[part 1 of 3: package /STLASWCs]
AUTOSAR XML (schema 4-3-0)
package /STLASWCs
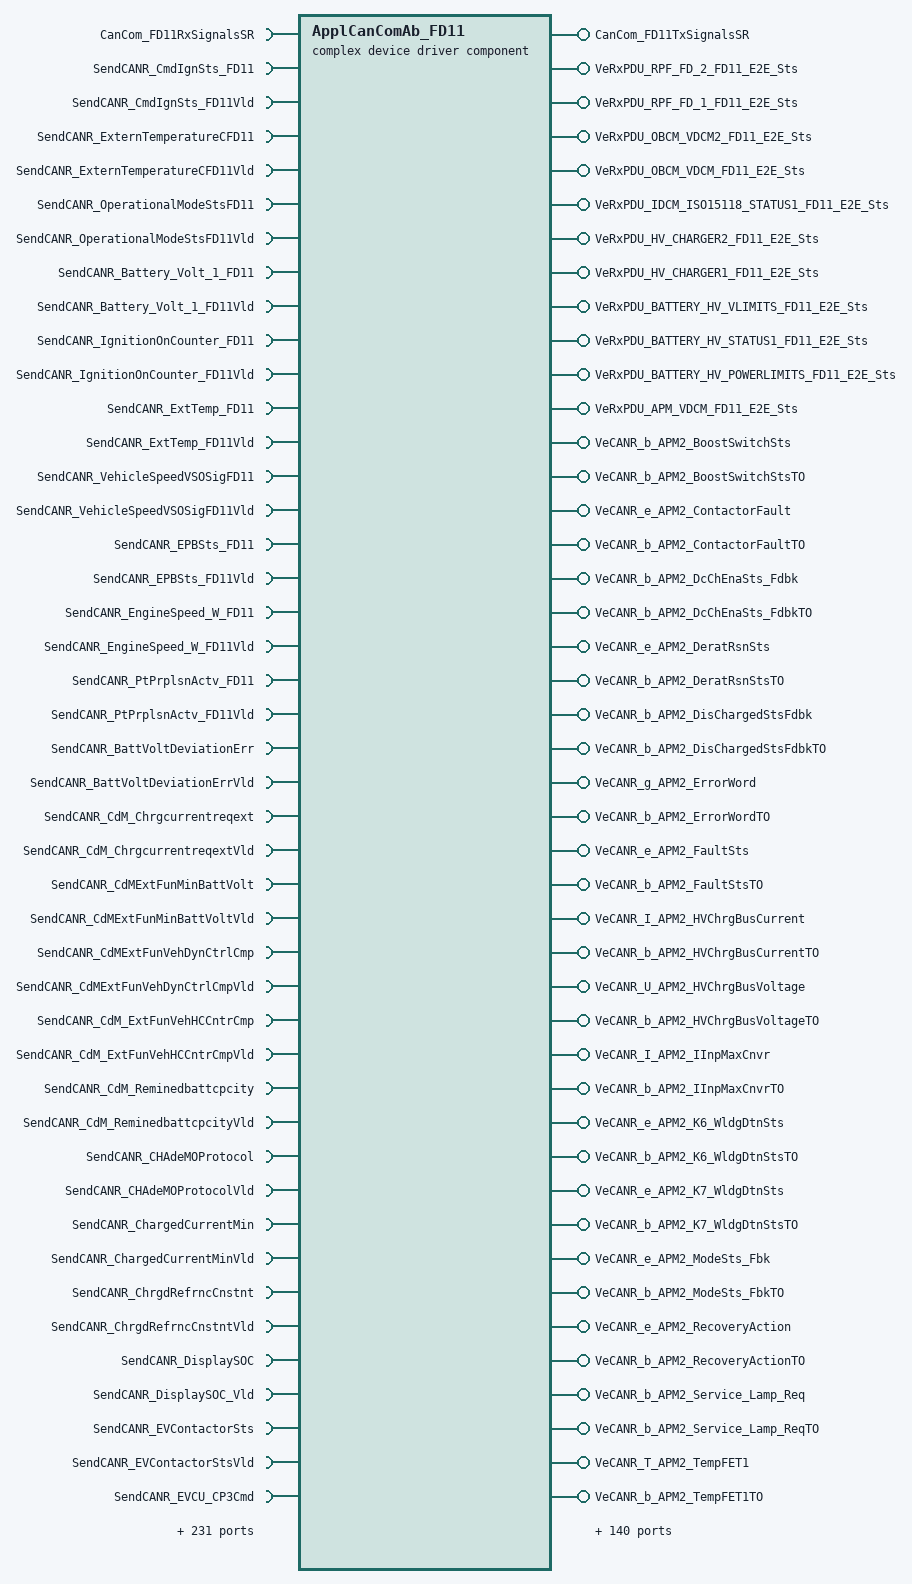
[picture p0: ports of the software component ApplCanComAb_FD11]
  complex device driver sw component type ApplCanComAb_FD11  # Application CAN Communication Abstraction Component - is responsible with receiving and sending CAN data from/to the lower BSW COM layers
    12 x provide port:
      CanCom_FD11TxSignalsSR: provided-interface=CanCom_FD11TxSignalsSR
        provided-com-specs:
          data-element=COMTX_CmdIgnSts_BCM_FD_10_FD11, init-value=constant-reference=COMTX_CmdIgnSts_BCM_FD_10_FD11_Init
          data-element=COMTX_ExternalTemperatureC_BCM_FD_10_FD11, init-value=constant-reference=COMTX_ExternalTemperatureC_BCM_FD_10_FD11_Init
          data-element=COMTX_OperationalModeSts_BCM_FD_2_FD11, init-value=constant-reference=COMTX_OperationalModeSts_BCM_FD_2_FD11_Init
          data-element=COMTX_Battery_Volt_1_BCM_FD_3_FD11, init-value=constant-reference=COMTX_Battery_Volt_1_BCM_FD_3_FD11_Init
          data-element=COMTX_IgnitionOnCounter_BCM_FD_7_FD11, init-value=constant-reference=COMTX_IgnitionOnCounter_BCM_FD_7_FD11_Init
          data-element=COMTX_ExternalTemperature_BCM_FD_9_FD11, init-value=constant-reference=COMTX_ExternalTemperature_BCM_FD_9_FD11_Init
          data-element=COMTX_VehicleSpeedVSOSig_BRAKE_FD_2_FD11, init-value=constant-reference=COMTX_VehicleSpeedVSOSig_BRAKE_FD_2_FD11_Init
          data-element=COMTX_EPBSts_BRAKE_FD_4_FD11, init-value=constant-reference=COMTX_EPBSts_BRAKE_FD_4_FD11_Init
          data-element=COMTX_EngineSpeed_W_ENGINE_FD_2_FD11, init-value=constant-reference=COMTX_EngineSpeed_W_ENGINE_FD_2_FD11_Init
          data-element=COMTX_PowertrainPrplsnActv_ENGINE_FD_2_FD11, init-value=constant-reference=COMTX_PowertrainPrplsnActv_ENGINE_FD_2_FD11_Init
          data-element=COMTX_BattVoltDeviationErr_EVCU_CHADEMO_STATUS1_FD11, init-value=constant-reference=COMTX_BattVoltDeviationErr_EVCU_CHADEMO_STATUS1_FD11_Init
          data-element=COMTX_CdM_Chrg_current_req_ext_EVCU_CHADEMO_STATUS1_FD11, init-value=constant-reference=COMTX_CdM_Chrg_current_req_ext_EVCU_CHADEMO_STATUS1_FD11_Init
          data-element=COMTX_CdM_ExtFun_Min_Batt_Volt_EVCU_CHADEMO_STATUS1_FD11, init-value=constant-reference=COMTX_CdM_ExtFun_Min_Batt_Volt_EVCU_CHADEMO_STATUS1_FD11_Init
          data-element=COMTX_CdM_ExtFun_Veh_Dyn_Control_Comp_EVCU_CHADEMO_STATUS1_FD11, init-value=constant-reference=COMTX_CdM_ExtFun_Veh_Dyn_Control_Comp_EVCU_CHADEMO_STATUS1_FD11_Init
          data-element=COMTX_CdM_ExtFun_Veh_HC_Control_Comp_EVCU_CHADEMO_STATUS1_FD11, init-value=constant-reference=COMTX_CdM_ExtFun_Veh_HC_Control_Comp_EVCU_CHADEMO_STATUS1_FD11_Init
          data-element=COMTX_CdM_Remained_batt_capacity_EVCU_CHADEMO_STATUS1_FD11, init-value=constant-reference=COMTX_CdM_Remained_batt_capacity_EVCU_CHADEMO_STATUS1_FD11_Init
          data-element=COMTX_CHAdeMOProtocol_EVCU_CHADEMO_STATUS1_FD11, init-value=constant-reference=COMTX_CHAdeMOProtocol_EVCU_CHADEMO_STATUS1_FD11_Init
          data-element=COMTX_ChargedCurrentMin_EVCU_CHADEMO_STATUS1_FD11, init-value=constant-reference=COMTX_ChargedCurrentMin_EVCU_CHADEMO_STATUS1_FD11_Init
          data-element=COMTX_ChargedReferenceConstant_EVCU_CHADEMO_STATUS1_FD11, init-value=constant-reference=COMTX_ChargedReferenceConstant_EVCU_CHADEMO_STATUS1_FD11_Init
          data-element=COMTX_DisplaySOC_EVCU_CHADEMO_STATUS1_FD11, init-value=constant-reference=COMTX_DisplaySOC_EVCU_CHADEMO_STATUS1_FD11_Init
          data-element=COMTX_EVContactorSts_EVCU_CHADEMO_STATUS1_FD11, init-value=constant-reference=COMTX_EVContactorSts_EVCU_CHADEMO_STATUS1_FD11_Init
          data-element=COMTX_EVCU_CP3Cmd_EVCU_CHADEMO_STATUS1_FD11, init-value=constant-reference=COMTX_EVCU_CP3Cmd_EVCU_CHADEMO_STATUS1_FD11_Init
          data-element=COMTX_MinBatteryPackVoltage_EVCU_CHADEMO_STATUS1_FD11, init-value=constant-reference=COMTX_MinBatteryPackVoltage_EVCU_CHADEMO_STATUS1_FD11_Init
          data-element=COMTX_StopReqBeforeCharge_EVCU_CHADEMO_STATUS1_FD11, init-value=constant-reference=COMTX_StopReqBeforeCharge_EVCU_CHADEMO_STATUS1_FD11_Init
          data-element=COMTX_TotalBatteryCapacity_EVCU_CHADEMO_STATUS1_FD11, init-value=constant-reference=COMTX_TotalBatteryCapacity_EVCU_CHADEMO_STATUS1_FD11_Init
          data-element=COMTX_VehicleDriveSts_EVCU_CHADEMO_STATUS1_FD11, init-value=constant-reference=COMTX_VehicleDriveSts_EVCU_CHADEMO_STATUS1_FD11_Init
          data-element=COMTX_N_PDU_7B_GLIWA_MCPA_TX_FD11, init-value=constant-reference=COMTX_N_PDU_7B_GLIWA_MCPA_TX_FD11_Init
          data-element=COMTX_N_PDU_7C_GLIWA_MCPB_TX_FD11, init-value=constant-reference=COMTX_N_PDU_7C_GLIWA_MCPB_TX_FD11_Init
          data-element=COMTX_N_PDU_86_GLIWA_SGCP_TX_FD11, init-value=constant-reference=COMTX_N_PDU_86_GLIWA_SGCP_TX_FD11_Init
          data-element=COMTX_N_PDU_342_GLIWA_T1_TX_FD11, init-value=constant-reference=COMTX_N_PDU_342_GLIWA_T1_TX_FD11_Init
          data-element=COMTX_CRC_HYBRID_DISPLAY2_HYBRID_DISPLAY2_FD11, init-value=constant-reference=COMTX_CRC_HYBRID_DISPLAY2_HYBRID_DISPLAY2_FD11_Init
          data-element=COMTX_DischargingSysStatus_HYBRID_DISPLAY2_FD11, init-value=constant-reference=COMTX_DischargingSysStatus_HYBRID_DISPLAY2_FD11_Init
          data-element=COMTX_LID_Status_120V_Socket_A_HYBRID_DISPLAY2_FD11, init-value=constant-reference=COMTX_LID_Status_120V_Socket_A_HYBRID_DISPLAY2_FD11_Init
          data-element=COMTX_LID_Status_120V_Socket_B_HYBRID_DISPLAY2_FD11, init-value=constant-reference=COMTX_LID_Status_120V_Socket_B_HYBRID_DISPLAY2_FD11_Init
          data-element=COMTX_LID_Status_240V_Socket_HYBRID_DISPLAY2_FD11, init-value=constant-reference=COMTX_LID_Status_240V_Socket_HYBRID_DISPLAY2_FD11_Init
          data-element=COMTX_Max_Allwd_AC_Output_Current_L1_HYBRID_DISPLAY2_FD11, init-value=constant-reference=COMTX_Max_Allwd_AC_Output_Current_L1_HYBRID_DISPLAY2_FD11_Init
          data-element=COMTX_Max_Allwd_AC_Output_Voltage_L1_HYBRID_DISPLAY2_FD11, init-value=constant-reference=COMTX_Max_Allwd_AC_Output_Voltage_L1_HYBRID_DISPLAY2_FD11_Init
          data-element=COMTX_MC_HYBRID_DISPLAY2_HYBRID_DISPLAY2_FD11, init-value=constant-reference=COMTX_MC_HYBRID_DISPLAY2_HYBRID_DISPLAY2_FD11_Init
          data-element=COMTX_CRC_HYBRID_SYSTEM_EPT1_HYBRID_SYSTEM_EPT1_FD11, init-value=constant-reference=COMTX_CRC_HYBRID_SYSTEM_EPT1_HYBRID_SYSTEM_EPT1_FD11_Init
          data-element=COMTX_HCP_ShutdownCommand_HYBRID_SYSTEM_EPT1_FD11, init-value=constant-reference=COMTX_HCP_ShutdownCommand_HYBRID_SYSTEM_EPT1_FD11_Init
          data-element=COMTX_HybridDriveModeSts_HYBRID_SYSTEM_EPT1_FD11, init-value=constant-reference=COMTX_HybridDriveModeSts_HYBRID_SYSTEM_EPT1_FD11_Init
          data-element=COMTX_LOC_DiagEnable_ePT_HYBRID_SYSTEM_EPT1_FD11, init-value=constant-reference=COMTX_LOC_DiagEnable_ePT_HYBRID_SYSTEM_EPT1_FD11_Init
          data-element=COMTX_MessageCounter_HYBRID_SYSTEM_EPT1_HYBRID_SYSTEM_EPT1_FD11, init-value=constant-reference=COMTX_MessageCounter_HYBRID_SYSTEM_EPT1_HYBRID_SYSTEM_EPT1_FD11_Init
          data-element=COMTX_PerWakeUp_Diag_HYBRID_SYSTEM_EPT1_FD11, init-value=constant-reference=COMTX_PerWakeUp_Diag_HYBRID_SYSTEM_EPT1_FD11_Init
          data-element=COMTX_PropulsionSystemActive_10B_HYBRID_SYSTEM_EPT1_FD11, init-value=constant-reference=COMTX_PropulsionSystemActive_10B_HYBRID_SYSTEM_EPT1_FD11_Init
          data-element=COMTX_WU_Timer_Value_HYBRID_SYSTEM_EPT1_FD11, init-value=constant-reference=COMTX_WU_Timer_Value_HYBRID_SYSTEM_EPT1_FD11_Init
          data-element=COMTX_IMPACTCommand_IMPACT_INFO_FD11, init-value=constant-reference=COMTX_IMPACTCommand_IMPACT_INFO_FD11_Init
          data-element=COMTX_IMPACTConfirm_IMPACT_INFO_FD11, init-value=constant-reference=COMTX_IMPACTConfirm_IMPACT_INFO_FD11_Init
          data-element=COMTX_TotalOdometer_IPC_FD_1_FD11, init-value=constant-reference=COMTX_TotalOdometer_IPC_FD_1_FD11_Init
          data-element=COMTX_MCPA_Temp_MCPA_DATA2_FD11, init-value=constant-reference=COMTX_MCPA_Temp_MCPA_DATA2_FD11_Init
          data-element=COMTX_CRC_MCPA_STATUS_MCPA_STATUS_FD11, init-value=constant-reference=COMTX_CRC_MCPA_STATUS_MCPA_STATUS_FD11_Init
          data-element=COMTX_MC_MCPA_STATUS_MCPA_STATUS_FD11, init-value=constant-reference=COMTX_MC_MCPA_STATUS_MCPA_STATUS_FD11_Init
          data-element=COMTX_MCPA_DC_Current_P_MCPA_STATUS_FD11, init-value=constant-reference=COMTX_MCPA_DC_Current_P_MCPA_STATUS_FD11_Init
          data-element=COMTX_MCPB_Temp_MCPB_DATA2_FD11, init-value=constant-reference=COMTX_MCPB_Temp_MCPB_DATA2_FD11_Init
          data-element=COMTX_CRC_MCPB_STATUS_MCPB_STATUS_FD11, init-value=constant-reference=COMTX_CRC_MCPB_STATUS_MCPB_STATUS_FD11_Init
          data-element=COMTX_MC_MCPB_STATUS_MCPB_STATUS_FD11, init-value=constant-reference=COMTX_MC_MCPB_STATUS_MCPB_STATUS_FD11_Init
          data-element=COMTX_MCPB_DC_Current_P_MCPB_STATUS_FD11, init-value=constant-reference=COMTX_MCPB_DC_Current_P_MCPB_STATUS_FD11_Init
          data-element=COMTX_CurrentCanNMState_FD03_EVCU2_PDC_INFO_FD_EVCU2_FD11, init-value=constant-reference=COMTX_CurrentCanNMState_FD03_EVCU2_PDC_INFO_FD_EVCU2_FD11_Init
          data-element=COMTX_CurrentCanNMState_FD05_EVCU2_PDC_INFO_FD_EVCU2_FD11, init-value=constant-reference=COMTX_CurrentCanNMState_FD05_EVCU2_PDC_INFO_FD_EVCU2_FD11_Init
          data-element=COMTX_CurrentCanNMState_FD11_EVCU2_PDC_INFO_FD_EVCU2_FD11, init-value=constant-reference=COMTX_CurrentCanNMState_FD11_EVCU2_PDC_INFO_FD_EVCU2_FD11_Init
          data-element=COMTX_CurrentCanNMState_FD16_EVCU2_PDC_INFO_FD_EVCU2_FD11, init-value=constant-reference=COMTX_CurrentCanNMState_FD16_EVCU2_PDC_INFO_FD_EVCU2_FD11_Init
          data-element=COMTX_CurrentFailSts_FD03_EVCU2_PDC_INFO_FD_EVCU2_FD11, init-value=constant-reference=COMTX_CurrentFailSts_FD03_EVCU2_PDC_INFO_FD_EVCU2_FD11_Init
          data-element=COMTX_CurrentFailSts_FD05_EVCU2_PDC_INFO_FD_EVCU2_FD11, init-value=constant-reference=COMTX_CurrentFailSts_FD05_EVCU2_PDC_INFO_FD_EVCU2_FD11_Init
          data-element=COMTX_CurrentFailSts_FD11_EVCU2_PDC_INFO_FD_EVCU2_FD11, init-value=constant-reference=COMTX_CurrentFailSts_FD11_EVCU2_PDC_INFO_FD_EVCU2_FD11_Init
          data-element=COMTX_CurrentFailSts_FD16_EVCU2_PDC_INFO_FD_EVCU2_FD11, init-value=constant-reference=COMTX_CurrentFailSts_FD16_EVCU2_PDC_INFO_FD_EVCU2_FD11_Init
          data-element=COMTX_DES_FD03_EVCU2_PDC_INFO_FD_EVCU2_FD11, init-value=constant-reference=COMTX_DES_FD03_EVCU2_PDC_INFO_FD_EVCU2_FD11_Init
          data-element=COMTX_DES_FD05_EVCU2_PDC_INFO_FD_EVCU2_FD11, init-value=constant-reference=COMTX_DES_FD05_EVCU2_PDC_INFO_FD_EVCU2_FD11_Init
          data-element=COMTX_DES_FD11_EVCU2_PDC_INFO_FD_EVCU2_FD11, init-value=constant-reference=COMTX_DES_FD11_EVCU2_PDC_INFO_FD_EVCU2_FD11_Init
          data-element=COMTX_DES_FD16_EVCU2_PDC_INFO_FD_EVCU2_FD11, init-value=constant-reference=COMTX_DES_FD16_EVCU2_PDC_INFO_FD_EVCU2_FD11_Init
          data-element=COMTX_EOL_FD03_EVCU2_PDC_INFO_FD_EVCU2_FD11, init-value=constant-reference=COMTX_EOL_FD03_EVCU2_PDC_INFO_FD_EVCU2_FD11_Init
          data-element=COMTX_EOL_FD05_EVCU2_PDC_INFO_FD_EVCU2_FD11, init-value=constant-reference=COMTX_EOL_FD05_EVCU2_PDC_INFO_FD_EVCU2_FD11_Init
          data-element=COMTX_EOL_FD11_EVCU2_PDC_INFO_FD_EVCU2_FD11, init-value=constant-reference=COMTX_EOL_FD11_EVCU2_PDC_INFO_FD_EVCU2_FD11_Init
          data-element=COMTX_EOL_FD16_EVCU2_PDC_INFO_FD_EVCU2_FD11, init-value=constant-reference=COMTX_EOL_FD16_EVCU2_PDC_INFO_FD_EVCU2_FD11_Init
          data-element=COMTX_GenericFailSts_FD03_EVCU2_PDC_INFO_FD_EVCU2_FD11, init-value=constant-reference=COMTX_GenericFailSts_FD03_EVCU2_PDC_INFO_FD_EVCU2_FD11_Init
          data-element=COMTX_GenericFailSts_FD05_EVCU2_PDC_INFO_FD_EVCU2_FD11, init-value=constant-reference=COMTX_GenericFailSts_FD05_EVCU2_PDC_INFO_FD_EVCU2_FD11_Init
          data-element=COMTX_GenericFailSts_FD11_EVCU2_PDC_INFO_FD_EVCU2_FD11, init-value=constant-reference=COMTX_GenericFailSts_FD11_EVCU2_PDC_INFO_FD_EVCU2_FD11_Init
          data-element=COMTX_GenericFailSts_FD16_EVCU2_PDC_INFO_FD_EVCU2_FD11, init-value=constant-reference=COMTX_GenericFailSts_FD16_EVCU2_PDC_INFO_FD_EVCU2_FD11_Init
          data-element=COMTX_PreviousCanNMState_FD03_EVCU2_PDC_INFO_FD_EVCU2_FD11, init-value=constant-reference=COMTX_PreviousCanNMState_FD03_EVCU2_PDC_INFO_FD_EVCU2_FD11_Init
          data-element=COMTX_PreviousCanNMState_FD05_EVCU2_PDC_INFO_FD_EVCU2_FD11, init-value=constant-reference=COMTX_PreviousCanNMState_FD05_EVCU2_PDC_INFO_FD_EVCU2_FD11_Init
          data-element=COMTX_PreviousCanNMState_FD11_EVCU2_PDC_INFO_FD_EVCU2_FD11, init-value=constant-reference=COMTX_PreviousCanNMState_FD11_EVCU2_PDC_INFO_FD_EVCU2_FD11_Init
          data-element=COMTX_PreviousCanNMState_FD16_EVCU2_PDC_INFO_FD_EVCU2_FD11, init-value=constant-reference=COMTX_PreviousCanNMState_FD16_EVCU2_PDC_INFO_FD_EVCU2_FD11_Init
          data-element=COMTX_StayActiveSource_FD03_EVCU2_PDC_INFO_FD_EVCU2_FD11, init-value=constant-reference=COMTX_StayActiveSource_FD03_EVCU2_PDC_INFO_FD_EVCU2_FD11_Init
          data-element=COMTX_StayActiveSource_FD05_EVCU2_PDC_INFO_FD_EVCU2_FD11, init-value=constant-reference=COMTX_StayActiveSource_FD05_EVCU2_PDC_INFO_FD_EVCU2_FD11_Init
          data-element=COMTX_StayActiveSource_FD11_EVCU2_PDC_INFO_FD_EVCU2_FD11, init-value=constant-reference=COMTX_StayActiveSource_FD11_EVCU2_PDC_INFO_FD_EVCU2_FD11_Init
          data-element=COMTX_StayActiveSource_FD16_EVCU2_PDC_INFO_FD_EVCU2_FD11, init-value=constant-reference=COMTX_StayActiveSource_FD16_EVCU2_PDC_INFO_FD_EVCU2_FD11_Init
          data-element=COMTX_WakeupSource_FD03_EVCU2_PDC_INFO_FD_EVCU2_FD11, init-value=constant-reference=COMTX_WakeupSource_FD03_EVCU2_PDC_INFO_FD_EVCU2_FD11_Init
          data-element=COMTX_WakeupSource_FD05_EVCU2_PDC_INFO_FD_EVCU2_FD11, init-value=constant-reference=COMTX_WakeupSource_FD05_EVCU2_PDC_INFO_FD_EVCU2_FD11_Init
          data-element=COMTX_WakeupSource_FD11_EVCU2_PDC_INFO_FD_EVCU2_FD11, init-value=constant-reference=COMTX_WakeupSource_FD11_EVCU2_PDC_INFO_FD_EVCU2_FD11_Init
          data-element=COMTX_WakeupSource_FD16_EVCU2_PDC_INFO_FD_EVCU2_FD11, init-value=constant-reference=COMTX_WakeupSource_FD16_EVCU2_PDC_INFO_FD_EVCU2_FD11_Init
          data-element=COMTX_DriveReady_PT_PT_SYSTEM_FD_1_FD11, init-value=constant-reference=COMTX_DriveReady_PT_PT_SYSTEM_FD_1_FD11_Init
          data-element=COMTX_GearEngaged_PT_PT_SYSTEM_FD_1_FD11, init-value=constant-reference=COMTX_GearEngaged_PT_PT_SYSTEM_FD_1_FD11_Init
          data-element=COMTX_GearEngagedForDisplay_PT_PT_SYSTEM_FD_1_FD11, init-value=constant-reference=COMTX_GearEngagedForDisplay_PT_PT_SYSTEM_FD_1_FD11_Init
          data-element=COMTX_PowertrainPrplsnActv_PT_PT_SYSTEM_FD_1_FD11, init-value=constant-reference=COMTX_PowertrainPrplsnActv_PT_PT_SYSTEM_FD_1_FD11_Init
          data-element=COMTX_SGCP_Temp_SGCP_DATA2_FD11, init-value=constant-reference=COMTX_SGCP_Temp_SGCP_DATA2_FD11_Init
          data-element=COMTX_SGCP_DC_Current_P_SGCP_STATUS_FD11, init-value=constant-reference=COMTX_SGCP_DC_Current_P_SGCP_STATUS_FD11_Init
          data-element=COMTX_QualifyDriveCycle_SYNCHRO_DC_GLOBAL_FD11, init-value=constant-reference=COMTX_QualifyDriveCycle_SYNCHRO_DC_GLOBAL_FD11_Init
          data-element=COMTX_GPS_Date_Day_TELEMATIC_FD_1_FD11, init-value=constant-reference=COMTX_GPS_Date_Day_TELEMATIC_FD_1_FD11_Init
          data-element=COMTX_GPS_Date_Month_TELEMATIC_FD_1_FD11, init-value=constant-reference=COMTX_GPS_Date_Month_TELEMATIC_FD_1_FD11_Init
          data-element=COMTX_GPS_Date_Year_TELEMATIC_FD_1_FD11, init-value=constant-reference=COMTX_GPS_Date_Year_TELEMATIC_FD_1_FD11_Init
          data-element=COMTX_GPS_UTC_Hour_TELEMATIC_FD_1_FD11, init-value=constant-reference=COMTX_GPS_UTC_Hour_TELEMATIC_FD_1_FD11_Init
          data-element=COMTX_GPS_UTC_Minute_TELEMATIC_FD_1_FD11, init-value=constant-reference=COMTX_GPS_UTC_Minute_TELEMATIC_FD_1_FD11_Init
          data-element=COMTX_GPS_UTC_Second_TELEMATIC_FD_1_FD11, init-value=constant-reference=COMTX_GPS_UTC_Second_TELEMATIC_FD_1_FD11_Init
          data-element=COMTX_GearEngagedForDisplay_TRANSM_FD_2_FD11, init-value=constant-reference=COMTX_GearEngagedForDisplay_TRANSM_FD_2_FD11_Init
          data-element=COMTX_HVCMS_BulkChargingComplete_VDCM_OBCM_FD11, init-value=constant-reference=COMTX_HVCMS_BulkChargingComplete_VDCM_OBCM_FD11_Init
          data-element=COMTX_HVCMS_ChargingComplete_VDCM_OBCM_FD11, init-value=constant-reference=COMTX_HVCMS_ChargingComplete_VDCM_OBCM_FD11_Init
          data-element=COMTX_HVCMS_EVEnergyCapacity_VDCM_OBCM_FD11, init-value=constant-reference=COMTX_HVCMS_EVEnergyCapacity_VDCM_OBCM_FD11_Init
          data-element=COMTX_HVCMS_EVEnergyRequest_VDCM_OBCM_FD11, init-value=constant-reference=COMTX_HVCMS_EVEnergyRequest_VDCM_OBCM_FD11_Init
          data-element=COMTX_HVCMS_EVErrorCode_VDCM_OBCM_FD11, init-value=constant-reference=COMTX_HVCMS_EVErrorCode_VDCM_OBCM_FD11_Init
          data-element=COMTX_HVCMS_EVMax_I_Limit_VDCM_OBCM_FD11, init-value=constant-reference=COMTX_HVCMS_EVMax_I_Limit_VDCM_OBCM_FD11_Init
          data-element=COMTX_HVCMS_EVMax_P_Limit_VDCM_OBCM_FD11, init-value=constant-reference=COMTX_HVCMS_EVMax_P_Limit_VDCM_OBCM_FD11_Init
          data-element=COMTX_HVCMS_EVMax_V_Limit_VDCM_OBCM_FD11, init-value=constant-reference=COMTX_HVCMS_EVMax_V_Limit_VDCM_OBCM_FD11_Init
          data-element=COMTX_HVCMS_EVReady_VDCM_OBCM_FD11, init-value=constant-reference=COMTX_HVCMS_EVReady_VDCM_OBCM_FD11_Init
          data-element=COMTX_HVCMS_EVRESS_SOC_VDCM_OBCM_FD11, init-value=constant-reference=COMTX_HVCMS_EVRESS_SOC_VDCM_OBCM_FD11_Init
          data-element=COMTX_HVCMS_EVRESSConditioning_VDCM_OBCM_FD11, init-value=constant-reference=COMTX_HVCMS_EVRESSConditioning_VDCM_OBCM_FD11_Init
          data-element=COMTX_HVCMS_EVTargetCurrent_VDCM_OBCM_FD11, init-value=constant-reference=COMTX_HVCMS_EVTargetCurrent_VDCM_OBCM_FD11_Init
          data-element=COMTX_HVCMS_EVTargetVoltage_VDCM_OBCM_FD11, init-value=constant-reference=COMTX_HVCMS_EVTargetVoltage_VDCM_OBCM_FD11_Init
          data-element=COMTX_HVCMS_Protocol_Entry{1..3}_VDCM_OBCM_FD11, init-value=constant-reference=COMTX_HVCMS_Protocol_Entry{1..3}_VDCM_OBCM_FD11_Init
          data-element=COMTX_HVCMS_ReadyToChargeState_VDCM_OBCM_FD11, init-value=constant-reference=COMTX_HVCMS_ReadyToChargeState_VDCM_OBCM_FD11_Init
          data-element=COMTX_HVCMS_RemaningTimeToBulkSOC_VDCM_OBCM_FD11, init-value=constant-reference=COMTX_HVCMS_RemaningTimeToBulkSOC_VDCM_OBCM_FD11_Init
          data-element=COMTX_HVCMS_RemaningTimeToFullSOC_VDCM_OBCM_FD11, init-value=constant-reference=COMTX_HVCMS_RemaningTimeToFullSOC_VDCM_OBCM_FD11_Init
          data-element=COMTX_HVCMS_SelectedEnergyTransferType_VDCM_OBCM_FD11, init-value=constant-reference=COMTX_HVCMS_SelectedEnergyTransferType_VDCM_OBCM_FD11_Init
          data-element=COMTX_HVCMS_SelectedPaymentOptn_VDCM_OBCM_FD11, init-value=constant-reference=COMTX_HVCMS_SelectedPaymentOptn_VDCM_OBCM_FD11_Init
          data-element=COMTX_HVCMS_SelectedServiceId_VDCM_OBCM_FD11, init-value=constant-reference=COMTX_HVCMS_SelectedServiceId_VDCM_OBCM_FD11_Init
          data-element=COMTX_HVCMS_ServiceCategory_VDCM_OBCM_FD11, init-value=constant-reference=COMTX_HVCMS_ServiceCategory_VDCM_OBCM_FD11_Init
          data-element=COMTX_HVCMS_ServiceScope_VDCM_OBCM_FD11, init-value=constant-reference=COMTX_HVCMS_ServiceScope_VDCM_OBCM_FD11_Init
          data-element=COMTX_OBCM_OutVoltageSyncTgt_VDCM_OBCM_FD11, init-value=constant-reference=COMTX_OBCM_OutVoltageSyncTgt_VDCM_OBCM_FD11_Init
          data-element=COMTX_V2X_HVCMS_SlctdEnergyTransfType_VDCM_OBCM_FD11, init-value=constant-reference=COMTX_V2X_HVCMS_SlctdEnergyTransfType_VDCM_OBCM_FD11_Init
          data-element=COMTX_VDCM_BattBulkSOC_VDCM_OBCM_FD11, init-value=constant-reference=COMTX_VDCM_BattBulkSOC_VDCM_OBCM_FD11_Init
          data-element=COMTX_VDCM_ContractAuthenticationID_VDCM_OBCM_FD11, init-value=constant-reference=COMTX_VDCM_ContractAuthenticationID_VDCM_OBCM_FD11_Init
          data-element=COMTX_VDCM_GenChallenge_VDCM_OBCM_FD11, init-value=constant-reference=COMTX_VDCM_GenChallenge_VDCM_OBCM_FD11_Init
          data-element=COMTX_VDCM_OBCDischCurrentLim_VDCM_OBCM_FD11, init-value=constant-reference=COMTX_VDCM_OBCDischCurrentLim_VDCM_OBCM_FD11_Init
          data-element=COMTX_VDCM_TypeCNegotiationSts_VDCM_OBCM_FD11, init-value=constant-reference=COMTX_VDCM_TypeCNegotiationSts_VDCM_OBCM_FD11_Init
          data-element=COMTX_ClrLgsDiagInfo_VDCM_PWT3_FD11, init-value=constant-reference=COMTX_ClrLgsDiagInfo_VDCM_PWT3_FD11_Init
          data-element=COMTX_VIN_DATA_VIN_FD11, init-value=constant-reference=COMTX_VIN_DATA_VIN_FD11_Init
          data-element=COMTX_VIN_MSG_VIN_FD11, init-value=constant-reference=COMTX_VIN_MSG_VIN_FD11_Init
      VeRxPDU_RPF_FD_2_FD11_E2E_Sts: provided-com-specs=[{data-element=E2ECheckSts, init-value=0}, {data-element=OpRetVal, init-value=0}], provided-interface=VeRxPDU_RPF_FD_2_FD11_E2E_Sts
      VeRxPDU_RPF_FD_1_FD11_E2E_Sts: provided-com-specs=[{data-element=E2ECheckSts, init-value=0}, {data-element=OpRetVal, init-value=0}], provided-interface=VeRxPDU_RPF_FD_1_FD11_E2E_Sts
      VeRxPDU_OBCM_VDCM2_FD11_E2E_Sts: provided-com-specs=[{data-element=E2ECheckSts, init-value=0}, {data-element=OpRetVal, init-value=0}], provided-interface=VeRxPDU_OBCM_VDCM2_FD11_E2E_Sts
      VeRxPDU_OBCM_VDCM_FD11_E2E_Sts: provided-com-specs=[{data-element=E2ECheckSts, init-value=0}, {data-element=OpRetVal, init-value=0}], provided-interface=VeRxPDU_OBCM_VDCM_FD11_E2E_Sts
      VeRxPDU_IDCM_ISO15118_STATUS1_FD11_E2E_Sts: provided-com-specs=[{data-element=E2ECheckSts, init-value=0}, {data-element=OpRetVal, init-value=0}], provided-interface=VeRxPDU_IDCM_ISO15118_STATUS1_FD11_E2E_Sts
      VeRxPDU_HV_CHARGER2_FD11_E2E_Sts: provided-com-specs=[{data-element=E2ECheckSts, init-value=0}, {data-element=OpRetVal, init-value=0}], provided-interface=VeRxPDU_HV_CHARGER2_FD11_E2E_Sts
      VeRxPDU_HV_CHARGER1_FD11_E2E_Sts: provided-com-specs=[{data-element=E2ECheckSts, init-value=0}, {data-element=OpRetVal, init-value=0}], provided-interface=VeRxPDU_HV_CHARGER1_FD11_E2E_Sts
      VeRxPDU_BATTERY_HV_VLIMITS_FD11_E2E_Sts: provided-com-specs=[{data-element=E2ECheckSts, init-value=0}, {data-element=OpRetVal, init-value=0}], provided-interface=VeRxPDU_BATTERY_HV_VLIMITS_FD11_E2E_Sts
      VeRxPDU_BATTERY_HV_STATUS1_FD11_E2E_Sts: provided-com-specs=[{data-element=E2ECheckSts, init-value=0}, {data-element=OpRetVal, init-value=0}], provided-interface=VeRxPDU_BATTERY_HV_STATUS1_FD11_E2E_Sts
      VeRxPDU_BATTERY_HV_POWERLIMITS_FD11_E2E_Sts: provided-com-specs=[{data-element=E2ECheckSts, init-value=0}, {data-element=OpRetVal, init-value=0}], provided-interface=VeRxPDU_BATTERY_HV_POWERLIMITS_FD11_E2E_Sts
      VeRxPDU_APM_VDCM_FD11_E2E_Sts: provided-com-specs=[{data-element=E2ECheckSts, init-value=0}, {data-element=OpRetVal, init-value=0}], provided-interface=VeRxPDU_APM_VDCM_FD11_E2E_Sts
    require port CanCom_FD11RxSignalsSR: required-interface=CanCom_FD11RxSignalsSR
      required-com-specs:
        data-element=COMRX_APM2_BoostSwitchSts_APM2_VDCM_FD11, alive-timeout=0.1, handle-never-received=true, init-value=constant-reference=COMRX_APM2_BoostSwitchSts_APM2_VDCM_FD11_Init
        data-element=COMRX_APM2_ContactorFault_APM2_VDCM_FD11, alive-timeout=0.1, handle-never-received=true, init-value=constant-reference=COMRX_APM2_ContactorFault_APM2_VDCM_FD11_Init
        data-element=COMRX_APM2_DcChEnaSts_Fdbk_APM2_VDCM_FD11, alive-timeout=0.1, handle-never-received=true, init-value=constant-reference=COMRX_APM2_DcChEnaSts_Fdbk_APM2_VDCM_FD11_Init
        data-element=COMRX_APM2_DeratRsnSts_APM2_VDCM_FD11, alive-timeout=0.1, handle-never-received=true, init-value=constant-reference=COMRX_APM2_DeratRsnSts_APM2_VDCM_FD11_Init
        data-element=COMRX_APM2_DisChargedSts_Fdbk_APM2_VDCM_FD11, alive-timeout=0.1, handle-never-received=true, init-value=constant-reference=COMRX_APM2_DisChargedSts_Fdbk_APM2_VDCM_FD11_Init
        data-element=COMRX_APM2_ErrorWord_APM2_VDCM_FD11, alive-timeout=0.1, handle-never-received=true, init-value=constant-reference=COMRX_APM2_ErrorWord_APM2_VDCM_FD11_Init
        data-element=COMRX_APM2_FaultSts_APM2_VDCM_FD11, alive-timeout=0.1, handle-never-received=true, init-value=constant-reference=COMRX_APM2_FaultSts_APM2_VDCM_FD11_Init
        data-element=COMRX_APM2_HVChrgBusCurrent_APM2_VDCM_FD11, alive-timeout=0.1, handle-never-received=true, init-value=constant-reference=COMRX_APM2_HVChrgBusCurrent_APM2_VDCM_FD11_Init
        data-element=COMRX_APM2_HVChrgBusVoltage_APM2_VDCM_FD11, alive-timeout=0.1, handle-never-received=true, init-value=constant-reference=COMRX_APM2_HVChrgBusVoltage_APM2_VDCM_FD11_Init
        data-element=COMRX_APM2_IInpMaxCnvr_APM2_VDCM_FD11, alive-timeout=0.1, handle-never-received=true, init-value=constant-reference=COMRX_APM2_IInpMaxCnvr_APM2_VDCM_FD11_Init
        data-element=COMRX_APM2_K6_WldgDtnSts_APM2_VDCM_FD11, alive-timeout=0.1, handle-never-received=true, init-value=constant-reference=COMRX_APM2_K6_WldgDtnSts_APM2_VDCM_FD11_Init
        data-element=COMRX_APM2_K7_WldgDtnSts_APM2_VDCM_FD11, alive-timeout=0.1, handle-never-received=true, init-value=constant-reference=COMRX_APM2_K7_WldgDtnSts_APM2_VDCM_FD11_Init
        data-element=COMRX_APM2_ModeSts_Fbk_APM2_VDCM_FD11, alive-timeout=0.1, handle-never-received=true, init-value=constant-reference=COMRX_APM2_ModeSts_Fbk_APM2_VDCM_FD11_Init
        data-element=COMRX_APM2_RecoveryAction_APM2_VDCM_FD11, alive-timeout=0.1, handle-never-received=true, init-value=constant-reference=COMRX_APM2_RecoveryAction_APM2_VDCM_FD11_Init
        data-element=COMRX_APM2_Service_Lamp_Request_APM2_VDCM_FD11, alive-timeout=0.1, handle-never-received=true, init-value=constant-reference=COMRX_APM2_Service_Lamp_Request_APM2_VDCM_FD11_Init
        data-element=COMRX_APM2_TempFET1_APM2_VDCM_FD11, alive-timeout=0.1, handle-never-received=true, init-value=constant-reference=COMRX_APM2_TempFET1_APM2_VDCM_FD11_Init
        data-element=COMRX_APM2_TempFET2_APM2_VDCM_FD11, alive-timeout=0.1, handle-never-received=true, init-value=constant-reference=COMRX_APM2_TempFET2_APM2_VDCM_FD11_Init
        data-element=COMRX_APM2_TempInlet_APM2_VDCM_FD11, alive-timeout=0.1, handle-never-received=true, init-value=constant-reference=COMRX_APM2_TempInlet_APM2_VDCM_FD11_Init
        data-element=COMRX_APM2_TempInt_APM2_VDCM_FD11, alive-timeout=0.1, handle-never-received=true, init-value=constant-reference=COMRX_APM2_TempInt_APM2_VDCM_FD11_Init
        data-element=COMRX_APM2_TempL1_APM2_VDCM_FD11, alive-timeout=0.1, handle-never-received=true, init-value=constant-reference=COMRX_APM2_TempL1_APM2_VDCM_FD11_Init
        data-element=COMRX_APM2_TempL2_APM2_VDCM_FD11, alive-timeout=0.1, handle-never-received=true, init-value=constant-reference=COMRX_APM2_TempL2_APM2_VDCM_FD11_Init
        data-element=COMRX_APM2_TempMargin_APM2_VDCM_FD11, alive-timeout=0.1, handle-never-received=true, init-value=constant-reference=COMRX_APM2_TempMargin_APM2_VDCM_FD11_Init
        data-element=COMRX_APM2InterlockSts_APM2_VDCM_FD11, alive-timeout=0.1, handle-never-received=true, init-value=constant-reference=COMRX_APM2InterlockSts_APM2_VDCM_FD11_Init
        data-element=COMRX_CurrEVSE_APM2_VDCM_FD11, alive-timeout=0.1, handle-never-received=true, init-value=constant-reference=COMRX_CurrEVSE_APM2_VDCM_FD11_Init
        data-element=COMRX_PwrEff_APM2_VDCM_FD11, alive-timeout=0.1, handle-never-received=true, init-value=constant-reference=COMRX_PwrEff_APM2_VDCM_FD11_Init
        data-element=COMRX_VltgChgEVSE_APM2_VDCM_FD11, alive-timeout=0.1, handle-never-received=true, init-value=constant-reference=COMRX_VltgChgEVSE_APM2_VDCM_FD11_Init
        data-element=COMRX_VltgChgInt_APM2_VDCM_FD11, alive-timeout=0.1, handle-never-received=true, init-value=constant-reference=COMRX_VltgChgInt_APM2_VDCM_FD11_Init
        data-element=COMRX_ImpactHardwire_BATTERY_HV_FD11, alive-timeout=0.1, handle-never-received=true, init-value=constant-reference=COMRX_ImpactHardwire_BATTERY_HV_FD11_Init
        data-element=COMRX_ImpactHardwireV_BATTERY_HV_FD11, alive-timeout=0.1, handle-never-received=true, init-value=constant-reference=COMRX_ImpactHardwireV_BATTERY_HV_FD11_Init
        data-element=COMRX_BMS_HV_High_Temp_Thrsh_BATTERY_HV2_FD11, alive-timeout=5, handle-never-received=true, init-value=constant-reference=COMRX_BMS_HV_High_Temp_Thrsh_BATTERY_HV2_FD11_Init
        data-element=COMRX_BMS_HV_Low_Temp_Thrsh_BATTERY_HV2_FD11, alive-timeout=5, handle-never-received=true, init-value=constant-reference=COMRX_BMS_HV_Low_Temp_Thrsh_BATTERY_HV2_FD11_Init
        data-element=COMRX_BMS_HV_SOC_AccuracySts_BATTERY_HV2_FD11, alive-timeout=5, handle-never-received=true, init-value=constant-reference=COMRX_BMS_HV_SOC_AccuracySts_BATTERY_HV2_FD11_Init
        data-element=COMRX_BMS_HV_SOC_Max_BATTERY_HV2_FD11, alive-timeout=5, handle-never-received=true, init-value=constant-reference=COMRX_BMS_HV_SOC_Max_BATTERY_HV2_FD11_Init
        data-element=COMRX_BMS_HV_SOC_Min_BATTERY_HV2_FD11, alive-timeout=5, handle-never-received=true, init-value=constant-reference=COMRX_BMS_HV_SOC_Min_BATTERY_HV2_FD11_Init
        data-element=COMRX_HEV_OnRq_BPCM_BATTERY_HV2_FD11, alive-timeout=5, handle-never-received=true, init-value=constant-reference=COMRX_HEV_OnRq_BPCM_BATTERY_HV2_FD11_Init
        data-element=COMRX_HVBatCell_Voltage_High_Thrsh_BATTERY_HV2_FD11, alive-timeout=5, handle-never-received=true, init-value=constant-reference=COMRX_HVBatCell_Voltage_High_Thrsh_BATTERY_HV2_FD11_Init
        data-element=COMRX_HVBatCell_Voltage_Low_Thrsh_BATTERY_HV2_FD11, alive-timeout=5, handle-never-received=true, init-value=constant-reference=COMRX_HVBatCell_Voltage_Low_Thrsh_BATTERY_HV2_FD11_Init
        data-element=COMRX_OBC_Temp{1..4}_DUALCHARGER_THERMAL_FD11, alive-timeout=2.5, handle-never-received=true, init-value=constant-reference=COMRX_OBC_Temp{1..4}_DUALCHARGER_THERMAL_FD11_Init
        data-element=COMRX_CRC_FOTA_MASTER_FOTA_MASTER_FD11, alive-timeout=10, handle-never-received=true, init-value=constant-reference=COMRX_CRC_FOTA_MASTER_FOTA_MASTER_FD11_Init
        data-element=COMRX_FOTA_Status_FOTA_MASTER_FD11, alive-timeout=10, handle-never-received=true, init-value=constant-reference=COMRX_FOTA_Status_FOTA_MASTER_FD11_Init
        data-element=COMRX_MessageCounter_FOTA_MASTER_FOTA_MASTER_FD11, alive-timeout=10, handle-never-received=true, init-value=constant-reference=COMRX_MessageCounter_FOTA_MASTER_FOTA_MASTER_FD11_Init
        data-element=COMRX_N_PDU_7E_GLIWA_MCPA_RX_FD11, handle-never-received=true, init-value=constant-reference=COMRX_N_PDU_7E_GLIWA_MCPA_RX_FD11_Init
        data-element=COMRX_N_PDU_7F_GLIWA_MCPB_RX_FD11, handle-never-received=true, init-value=constant-reference=COMRX_N_PDU_7F_GLIWA_MCPB_RX_FD11_Init
        data-element=COMRX_N_PDU_81_GLIWA_SGCP_RX_FD11, handle-never-received=true, init-value=constant-reference=COMRX_N_PDU_81_GLIWA_SGCP_RX_FD11_Init
        data-element=COMRX_N_PDU_343_GLIWA_T1_RX_FD11, handle-never-received=true, init-value=constant-reference=COMRX_N_PDU_343_GLIWA_T1_RX_FD11_Init
        data-element=COMRX_HVBatteryMILRequest_HVBATTERY2_FD11, alive-timeout=1, handle-never-received=true, init-value=constant-reference=COMRX_HVBatteryMILRequest_HVBATTERY2_FD11_Init
        data-element=COMRX_HVBattery_RealTimeClock_HVBATTERY5_FD11, alive-timeout=10, handle-never-received=true, init-value=constant-reference=COMRX_HVBattery_RealTimeClock_HVBATTERY5_FD11_Init
        data-element=COMRX_HVBattery_RealTimeClockV_HVBATTERY5_FD11, alive-timeout=10, handle-never-received=true, init-value=constant-reference=COMRX_HVBattery_RealTimeClockV_HVBATTERY5_FD11_Init
        data-element=COMRX_Warning_PackTempHigh_HVBATTERY_RM_CHARGING1_FD11, alive-timeout=10, handle-never-received=true, init-value=constant-reference=COMRX_Warning_PackTempHigh_HVBATTERY_RM_CHARGING1_FD11_Init
        data-element=COMRX_HVBatSleepTime_HVBATTERY_THERMAL_FD11, alive-timeout=1, handle-never-received=true, init-value=constant-reference=COMRX_HVBatSleepTime_HVBATTERY_THERMAL_FD11_Init
        data-element=COMRX_CdM_Avail_output_current_EXT_IDCM_CHADEMO_STATUS1_FD11, alive-timeout=1, handle-never-received=true, init-value=constant-reference=COMRX_CdM_Avail_output_current_EXT_IDCM_CHADEMO_STATUS1_FD11_Init
        data-element=COMRX_CdM_Charger_connector_lock_IDCM_CHADEMO_STATUS1_FD11, alive-timeout=1, handle-never-received=true, init-value=constant-reference=COMRX_CdM_Charger_connector_lock_IDCM_CHADEMO_STATUS1_FD11_Init
        data-element=COMRX_CdM_ExtFun_Thres_Volt_IDCM_CHADEMO_STATUS1_FD11, alive-timeout=1, handle-never-received=true, init-value=constant-reference=COMRX_CdM_ExtFun_Thres_Volt_IDCM_CHADEMO_STATUS1_FD11_Init
        data-element=COMRX_EVSE_BatteryCompatibilty_IDCM_CHADEMO_STATUS1_FD11, alive-timeout=1, handle-never-received=true, init-value=constant-reference=COMRX_EVSE_BatteryCompatibilty_IDCM_CHADEMO_STATUS1_FD11_Init
        data-element=COMRX_EVSE_CHAdeMOProtocol_IDCM_CHADEMO_STATUS1_FD11, alive-timeout=1, handle-never-received=true, init-value=constant-reference=COMRX_EVSE_CHAdeMOProtocol_IDCM_CHADEMO_STATUS1_FD11_Init
        data-element=COMRX_EVSE_ChargingSystemError_IDCM_CHADEMO_STATUS1_FD11, alive-timeout=1, handle-never-received=true, init-value=constant-reference=COMRX_EVSE_ChargingSystemError_IDCM_CHADEMO_STATUS1_FD11_Init
        data-element=COMRX_EVSE_EnergizingState_IDCM_CHADEMO_STATUS1_FD11, alive-timeout=1, handle-never-received=true, init-value=constant-reference=COMRX_EVSE_EnergizingState_IDCM_CHADEMO_STATUS1_FD11_Init
        data-element=COMRX_EVSE_RemainingMin_IDCM_CHADEMO_STATUS1_FD11, alive-timeout=1, handle-never-received=true, init-value=constant-reference=COMRX_EVSE_RemainingMin_IDCM_CHADEMO_STATUS1_FD11_Init
        data-element=COMRX_EVSE_RemainingSec_IDCM_CHADEMO_STATUS1_FD11, alive-timeout=1, handle-never-received=true, init-value=constant-reference=COMRX_EVSE_RemainingSec_IDCM_CHADEMO_STATUS1_FD11_Init
        data-element=COMRX_EVSE_ThrshldVoltage_IDCM_CHADEMO_STATUS1_FD11, alive-timeout=1, handle-never-received=true, init-value=constant-reference=COMRX_EVSE_ThrshldVoltage_IDCM_CHADEMO_STATUS1_FD11_Init
        data-element=COMRX_CRC_IDCM_OBD_DTC_IDCM_OBD_DTC_FD11, alive-timeout=1, handle-never-received=true, init-value=constant-reference=COMRX_CRC_IDCM_OBD_DTC_IDCM_OBD_DTC_FD11_Init
        data-element=COMRX_IDCM_CAL_ID_IDCM_OBD_DTC_FD11, alive-timeout=1, handle-never-received=true, init-value=constant-reference=COMRX_IDCM_CAL_ID_IDCM_OBD_DTC_FD11_Init
        data-element=COMRX_IDCM_CAL_VN_IDCM_OBD_DTC_FD11, alive-timeout=1, handle-never-received=true, init-value=constant-reference=COMRX_IDCM_CAL_VN_IDCM_OBD_DTC_FD11_Init
        data-element=COMRX_IDCM_DTC_Idx{1..8}_IDCM_OBD_DTC_FD11, alive-timeout=1, handle-never-received=true, init-value=constant-reference=COMRX_IDCM_DTC_Idx{1..8}_IDCM_OBD_DTC_FD11_Init
        data-element=COMRX_IDCM_DTC_Stat{1..8}_IDCM_OBD_DTC_FD11, alive-timeout=1, handle-never-received=true, init-value=constant-reference=COMRX_IDCM_DTC_Stat{1..8}_IDCM_OBD_DTC_FD11_Init
        data-element=COMRX_IDCM_RBM_Idx_IDCM_OBD_DTC_FD11, alive-timeout=1, handle-never-received=true, init-value=constant-reference=COMRX_IDCM_RBM_Idx_IDCM_OBD_DTC_FD11_Init
        data-element=COMRX_IDCM_RBM_Stat_IDCM_OBD_DTC_FD11, alive-timeout=1, handle-never-received=true, init-value=constant-reference=COMRX_IDCM_RBM_Stat_IDCM_OBD_DTC_FD11_Init
        data-element=COMRX_MessageCounter_IDCM_OBD_DTC_IDCM_OBD_DTC_FD11, alive-timeout=1, handle-never-received=true, init-value=constant-reference=COMRX_MessageCounter_IDCM_OBD_DTC_IDCM_OBD_DTC_FD11_Init
        data-element=COMRX_IDCM_Wakeup_HCP_LV_CHARGER1_FD11, alive-timeout=0.5, handle-never-received=true, init-value=constant-reference=COMRX_IDCM_Wakeup_HCP_LV_CHARGER1_FD11_Init
    172 x provide port:
      VeCANR_b_APM2_BoostSwitchSts: nonqueued-sender-com-spec{data-element=VeCANR_b_APM2_BoostSwitchSts, init-value=VeCANR_b_APM2_BoostSwitchStsValue:0}, provided-interface=VeCANR_b_APM2_BoostSwitchSts
      VeCANR_b_APM2_BoostSwitchStsTO: nonqueued-sender-com-spec{data-element=VeCANR_b_APM2_BoostSwitchStsTO, init-value=VeCANR_b_APM2_BoostSwitchStsTOValue:0}, provided-interface=VeCANR_b_APM2_BoostSwitchStsTO
      VeCANR_e_APM2_ContactorFault: nonqueued-sender-com-spec{data-element=VeCANR_e_APM2_ContactorFault, init-value=VeCANR_e_APM2_ContactorFaultValue:2}, provided-interface=VeCANR_e_APM2_ContactorFault
      VeCANR_b_APM2_ContactorFaultTO: nonqueued-sender-com-spec{data-element=VeCANR_b_APM2_ContactorFaultTO, init-value=VeCANR_b_APM2_ContactorFaultTOValue:0}, provided-interface=VeCANR_b_APM2_ContactorFaultTO
      VeCANR_b_APM2_DcChEnaSts_Fdbk: nonqueued-sender-com-spec{data-element=VeCANR_b_APM2_DcChEnaSts_Fdbk, init-value=VeCANR_b_APM2_DcChEnaSts_FdbkValue:0}, provided-interface=VeCANR_b_APM2_DcChEnaSts_Fdbk
      VeCANR_b_APM2_DcChEnaSts_FdbkTO: nonqueued-sender-com-spec{data-element=VeCANR_b_APM2_DcChEnaSts_FdbkTO, init-value=VeCANR_b_APM2_DcChEnaSts_FdbkTOValue:0}, provided-interface=VeCANR_b_APM2_DcChEnaSts_FdbkTO
      VeCANR_e_APM2_DeratRsnSts: nonqueued-sender-com-spec{data-element=VeCANR_e_APM2_DeratRsnSts, init-value=VeCANR_e_APM2_DeratRsnStsValue:0}, provided-interface=VeCANR_e_APM2_DeratRsnSts
      VeCANR_b_APM2_DeratRsnStsTO: nonqueued-sender-com-spec{data-element=VeCANR_b_APM2_DeratRsnStsTO, init-value=VeCANR_b_APM2_DeratRsnStsTOValue:0}, provided-interface=VeCANR_b_APM2_DeratRsnStsTO
      VeCANR_b_APM2_DisChargedStsFdbk: nonqueued-sender-com-spec{data-element=VeCANR_b_APM2_DisChargedStsFdbk, init-value=VeCANR_b_APM2_DisChargedStsFdbkValue:0}, provided-interface=VeCANR_b_APM2_DisChargedStsFdbk
      VeCANR_b_APM2_DisChargedStsFdbkTO: nonqueued-sender-com-spec{data-element=VeCANR_b_APM2_DisChargedStsFdbkTO, init-value=VeCANR_b_APM2_DisChargedStsFdbkTOValue:0}, provided-interface=VeCANR_b_APM2_DisChargedStsFdbkTO
      VeCANR_g_APM2_ErrorWord: nonqueued-sender-com-spec{data-element=VeCANR_g_APM2_ErrorWord, init-value=VeCANR_g_APM2_ErrorWordValue:0}, provided-interface=VeCANR_g_APM2_ErrorWord
      VeCANR_b_APM2_ErrorWordTO: nonqueued-sender-com-spec{data-element=VeCANR_b_APM2_ErrorWordTO, init-value=VeCANR_b_APM2_ErrorWordTOValue:0}, provided-interface=VeCANR_b_APM2_ErrorWordTO
      VeCANR_e_APM2_FaultSts: nonqueued-sender-com-spec{data-element=VeCANR_e_APM2_FaultSts, init-value=VeCANR_e_APM2_FaultStsValue:0}, provided-interface=VeCANR_e_APM2_FaultSts
      VeCANR_b_APM2_FaultStsTO: nonqueued-sender-com-spec{data-element=VeCANR_b_APM2_FaultStsTO, init-value=VeCANR_b_APM2_FaultStsTOValue:0}, provided-interface=VeCANR_b_APM2_FaultStsTO
      VeCANR_I_APM2_HVChrgBusCurrent: nonqueued-sender-com-spec{data-element=VeCANR_I_APM2_HVChrgBusCurrent, init-value=VeCANR_I_APM2_HVChrgBusCurrentValue:0}, provided-interface=VeCANR_I_APM2_HVChrgBusCurrent
      VeCANR_b_APM2_HVChrgBusCurrentTO: nonqueued-sender-com-spec{data-element=VeCANR_b_APM2_HVChrgBusCurrentTO, init-value=VeCANR_b_APM2_HVChrgBusCurrentTOValue:0}, provided-interface=VeCANR_b_APM2_HVChrgBusCurrentTO
      VeCANR_U_APM2_HVChrgBusVoltage: nonqueued-sender-com-spec{data-element=VeCANR_U_APM2_HVChrgBusVoltage, init-value=VeCANR_U_APM2_HVChrgBusVoltageValue:0}, provided-interface=VeCANR_U_APM2_HVChrgBusVoltage
      VeCANR_b_APM2_HVChrgBusVoltageTO: nonqueued-sender-com-spec{data-element=VeCANR_b_APM2_HVChrgBusVoltageTO, init-value=VeCANR_b_APM2_HVChrgBusVoltageTOValue:0}, provided-interface=VeCANR_b_APM2_HVChrgBusVoltageTO
      VeCANR_I_APM2_IInpMaxCnvr: nonqueued-sender-com-spec{data-element=VeCANR_I_APM2_IInpMaxCnvr, init-value=VeCANR_I_APM2_IInpMaxCnvrValue:0}, provided-interface=VeCANR_I_APM2_IInpMaxCnvr
      VeCANR_b_APM2_IInpMaxCnvrTO: nonqueued-sender-com-spec{data-element=VeCANR_b_APM2_IInpMaxCnvrTO, init-value=VeCANR_b_APM2_IInpMaxCnvrTOValue:0}, provided-interface=VeCANR_b_APM2_IInpMaxCnvrTO
      VeCANR_e_APM2_K6_WldgDtnSts: nonqueued-sender-com-spec{data-element=VeCANR_e_APM2_K6_WldgDtnSts, init-value=VeCANR_e_APM2_K6_WldgDtnStsValue:0}, provided-interface=VeCANR_e_APM2_K6_WldgDtnSts
      VeCANR_b_APM2_K6_WldgDtnStsTO: nonqueued-sender-com-spec{data-element=VeCANR_b_APM2_K6_WldgDtnStsTO, init-value=VeCANR_b_APM2_K6_WldgDtnStsTOValue:0}, provided-interface=VeCANR_b_APM2_K6_WldgDtnStsTO
      VeCANR_e_APM2_K7_WldgDtnSts: nonqueued-sender-com-spec{data-element=VeCANR_e_APM2_K7_WldgDtnSts, init-value=VeCANR_e_APM2_K7_WldgDtnStsValue:0}, provided-interface=VeCANR_e_APM2_K7_WldgDtnSts
      VeCANR_b_APM2_K7_WldgDtnStsTO: nonqueued-sender-com-spec{data-element=VeCANR_b_APM2_K7_WldgDtnStsTO, init-value=VeCANR_b_APM2_K7_WldgDtnStsTOValue:0}, provided-interface=VeCANR_b_APM2_K7_WldgDtnStsTO
      VeCANR_e_APM2_ModeSts_Fbk: nonqueued-sender-com-spec{data-element=VeCANR_e_APM2_ModeSts_Fbk, init-value=VeCANR_e_APM2_ModeSts_FbkValue:0}, provided-interface=VeCANR_e_APM2_ModeSts_Fbk
      VeCANR_b_APM2_ModeSts_FbkTO: nonqueued-sender-com-spec{data-element=VeCANR_b_APM2_ModeSts_FbkTO, init-value=VeCANR_b_APM2_ModeSts_FbkTOValue:0}, provided-interface=VeCANR_b_APM2_ModeSts_FbkTO
      VeCANR_e_APM2_RecoveryAction: nonqueued-sender-com-spec{data-element=VeCANR_e_APM2_RecoveryAction, init-value=VeCANR_e_APM2_RecoveryActionValue:0}, provided-interface=VeCANR_e_APM2_RecoveryAction
      VeCANR_b_APM2_RecoveryActionTO: nonqueued-sender-com-spec{data-element=VeCANR_b_APM2_RecoveryActionTO, init-value=VeCANR_b_APM2_RecoveryActionTOValue:0}, provided-interface=VeCANR_b_APM2_RecoveryActionTO
      VeCANR_b_APM2_Service_Lamp_Req: nonqueued-sender-com-spec{data-element=VeCANR_b_APM2_Service_Lamp_Req, init-value=VeCANR_b_APM2_Service_Lamp_ReqValue:0}, provided-interface=VeCANR_b_APM2_Service_Lamp_Req
      VeCANR_b_APM2_Service_Lamp_ReqTO: nonqueued-sender-com-spec{data-element=VeCANR_b_APM2_Service_Lamp_ReqTO, init-value=VeCANR_b_APM2_Service_Lamp_ReqTOValue:0}, provided-interface=VeCANR_b_APM2_Service_Lamp_ReqTO
      VeCANR_T_APM2_TempFET1: nonqueued-sender-com-spec{data-element=VeCANR_T_APM2_TempFET1, init-value=VeCANR_T_APM2_TempFET1Value:20}, provided-interface=VeCANR_T_APM2_TempFET1
      VeCANR_b_APM2_TempFET1TO: nonqueued-sender-com-spec{data-element=VeCANR_b_APM2_TempFET1TO, init-value=VeCANR_b_APM2_TempFET1TOValue:0}, provided-interface=VeCANR_b_APM2_TempFET1TO
      VeCANR_T_APM2_TempFET2: nonqueued-sender-com-spec{data-element=VeCANR_T_APM2_TempFET2, init-value=VeCANR_T_APM2_TempFET2Value:20}, provided-interface=VeCANR_T_APM2_TempFET2
      VeCANR_b_APM2_TempFET2TO: nonqueued-sender-com-spec{data-element=VeCANR_b_APM2_TempFET2TO, init-value=VeCANR_b_APM2_TempFET2TOValue:0}, provided-interface=VeCANR_b_APM2_TempFET2TO
      VeCANR_T_APM2_TempInlet: nonqueued-sender-com-spec{data-element=VeCANR_T_APM2_TempInlet, init-value=VeCANR_T_APM2_TempInletValue:-40}, provided-interface=VeCANR_T_APM2_TempInlet
      VeCANR_b_APM2_TempInletTO: nonqueued-sender-com-spec{data-element=VeCANR_b_APM2_TempInletTO, init-value=VeCANR_b_APM2_TempInletTOValue:0}, provided-interface=VeCANR_b_APM2_TempInletTO
      VeCANR_T_APM2_TempInt: nonqueued-sender-com-spec{data-element=VeCANR_T_APM2_TempInt, init-value=VeCANR_T_APM2_TempIntValue:20}, provided-interface=VeCANR_T_APM2_TempInt
      VeCANR_b_APM2_TempIntTO: nonqueued-sender-com-spec{data-element=VeCANR_b_APM2_TempIntTO, init-value=VeCANR_b_APM2_TempIntTOValue:0}, provided-interface=VeCANR_b_APM2_TempIntTO
      VeCANR_T_APM2_TempL1: nonqueued-sender-com-spec{data-element=VeCANR_T_APM2_TempL1, init-value=VeCANR_T_APM2_TempL1Value:20}, provided-interface=VeCANR_T_APM2_TempL1
      VeCANR_b_APM2_TempL1TO: nonqueued-sender-com-spec{data-element=VeCANR_b_APM2_TempL1TO, init-value=VeCANR_b_APM2_TempL1TOValue:0}, provided-interface=VeCANR_b_APM2_TempL1TO
      VeCANR_T_APM2_TempL2: nonqueued-sender-com-spec{data-element=VeCANR_T_APM2_TempL2, init-value=VeCANR_T_APM2_TempL2Value:20}, provided-interface=VeCANR_T_APM2_TempL2
      VeCANR_b_APM2_TempL2TO: nonqueued-sender-com-spec{data-element=VeCANR_b_APM2_TempL2TO, init-value=VeCANR_b_APM2_TempL2TOValue:0}, provided-interface=VeCANR_b_APM2_TempL2TO
      VeCANR_T_APM2_TempMargin: nonqueued-sender-com-spec{data-element=VeCANR_T_APM2_TempMargin, init-value=VeCANR_T_APM2_TempMarginValue:0.312000000000001}, provided-interface=VeCANR_T_APM2_TempMargin
      VeCANR_b_APM2_TempMarginTO: nonqueued-sender-com-spec{data-element=VeCANR_b_APM2_TempMarginTO, init-value=VeCANR_b_APM2_TempMarginTOValue:0}, provided-interface=VeCANR_b_APM2_TempMarginTO
      VeCANR_e_APM2InterlockSts: nonqueued-sender-com-spec{data-element=VeCANR_e_APM2InterlockSts, init-value=VeCANR_e_APM2InterlockStsValue:0}, provided-interface=VeCANR_e_APM2InterlockSts
      VeCANR_b_APM2InterlockStsTO: nonqueued-sender-com-spec{data-element=VeCANR_b_APM2InterlockStsTO, init-value=VeCANR_b_APM2InterlockStsTOValue:0}, provided-interface=VeCANR_b_APM2InterlockStsTO
      VeCANR_I_CurrEVSE: nonqueued-sender-com-spec{data-element=VeCANR_I_CurrEVSE, init-value=VeCANR_I_CurrEVSEValue:0}, provided-interface=VeCANR_I_CurrEVSE
      VeCANR_b_CurrEVSE_TO: nonqueued-sender-com-spec{data-element=VeCANR_b_CurrEVSE_TO, init-value=VeCANR_b_CurrEVSE_TOValue:0}, provided-interface=VeCANR_b_CurrEVSE_TO
      VeCANR_Pct_PwrEff: nonqueued-sender-com-spec{data-element=VeCANR_Pct_PwrEff, init-value=VeCANR_Pct_PwrEffValue:0}, provided-interface=VeCANR_Pct_PwrEff
      VeCANR_b_PwrEffTO: nonqueued-sender-com-spec{data-element=VeCANR_b_PwrEffTO, init-value=VeCANR_b_PwrEffTOValue:0}, provided-interface=VeCANR_b_PwrEffTO
      VeCANR_U_VltgChgEVSE: nonqueued-sender-com-spec{data-element=VeCANR_U_VltgChgEVSE, init-value=VeCANR_U_VltgChgEVSEValue:0}, provided-interface=VeCANR_U_VltgChgEVSE
      VeCANR_b_VltgChgEVSE_TO: nonqueued-sender-com-spec{data-element=VeCANR_b_VltgChgEVSE_TO, init-value=VeCANR_b_VltgChgEVSE_TOValue:0}, provided-interface=VeCANR_b_VltgChgEVSE_TO
      VeCANR_U_VltgChgInt: nonqueued-sender-com-spec{data-element=VeCANR_U_VltgChgInt, init-value=VeCANR_U_VltgChgIntValue:0}, provided-interface=VeCANR_U_VltgChgInt
      VeCANR_b_VltgChgIntTO: nonqueued-sender-com-spec{data-element=VeCANR_b_VltgChgIntTO, init-value=VeCANR_b_VltgChgIntTOValue:0}, provided-interface=VeCANR_b_VltgChgIntTO
      VeCANR_b_ImpactHardwire_FD11: nonqueued-sender-com-spec{data-element=VeCANR_b_ImpactHardwire_FD11, init-value=VeCANR_b_ImpactHardwire_FD11Value:0}, provided-interface=VeCANR_b_ImpactHardwire_FD11
      VeCANR_b_ImpactHardwire_FD11TO: nonqueued-sender-com-spec{data-element=VeCANR_b_ImpactHardwire_FD11TO, init-value=VeCANR_b_ImpactHardwire_FD11TOValue:0}, provided-interface=VeCANR_b_ImpactHardwire_FD11TO
      VeCANR_b_ImpactHardwireV_FD11: nonqueued-sender-com-spec{data-element=VeCANR_b_ImpactHardwireV_FD11, init-value=VeCANR_b_ImpactHardwireV_FD11Value:0}, provided-interface=VeCANR_b_ImpactHardwireV_FD11
      VeCANR_b_ImpactHardwireV_FD11TO: nonqueued-sender-com-spec{data-element=VeCANR_b_ImpactHardwireV_FD11TO, init-value=VeCANR_b_ImpactHardwireV_FD11TOValue:0}, provided-interface=VeCANR_b_ImpactHardwireV_FD11TO
      VeCANR_T_BMS_HV_HiTempThd_FD11: nonqueued-sender-com-spec{data-element=VeCANR_T_BMS_HV_HiTempThd_FD11, init-value=VeCANR_T_BMS_HV_HiTempThd_FD11Value:-40}, provided-interface=VeCANR_T_BMS_HV_HiTempThd_FD11
      VeCANR_b_BMS_HV_HiTempThd_FD11TO: nonqueued-sender-com-spec{data-element=VeCANR_b_BMS_HV_HiTempThd_FD11TO, init-value=VeCANR_b_BMS_HV_HiTempThd_FD11TOValue:0}, provided-interface=VeCANR_b_BMS_HV_HiTempThd_FD11TO
      VeCANR_T_BMS_HVLoTempThd_FD11: nonqueued-sender-com-spec{data-element=VeCANR_T_BMS_HVLoTempThd_FD11, init-value=VeCANR_T_BMS_HVLoTempThd_FD11Value:-40}, provided-interface=VeCANR_T_BMS_HVLoTempThd_FD11
      VeCANR_b_BMS_HVLoTempThd_FD11TO: nonqueued-sender-com-spec{data-element=VeCANR_b_BMS_HVLoTempThd_FD11TO, init-value=VeCANR_b_BMS_HVLoTempThd_FD11TOValue:0}, provided-interface=VeCANR_b_BMS_HVLoTempThd_FD11TO
      VeCANR_e_BMS_HV_SOCAcrcyStsFD11: nonqueued-sender-com-spec{data-element=VeCANR_e_BMS_HV_SOCAcrcyStsFD11, init-value=VeCANR_e_BMS_HV_SOCAcrcyStsFD11Value:0}, provided-interface=VeCANR_e_BMS_HV_SOCAcrcyStsFD11
      VeCANR_b_BMS_HV_SOCAcrcyStsFD11TO: nonqueued-sender-com-spec{data-element=VeCANR_b_BMS_HV_SOCAcrcyStsFD11TO, init-value=VeCANR_b_BMS_HV_SOCAcrcyStsFD11TOValue:0}, provided-interface=VeCANR_b_BMS_HV_SOCAcrcyStsFD11TO
      VeCANR_Pct_BMS_HV_SOC_Max_FD11: nonqueued-sender-com-spec{data-element=VeCANR_Pct_BMS_HV_SOC_Max_FD11, init-value=VeCANR_Pct_BMS_HV_SOC_Max_FD11Value:19.60785}, provided-interface=VeCANR_Pct_BMS_HV_SOC_Max_FD11
      VeCANR_b_BMS_HV_SOC_Max_FD11TO: nonqueued-sender-com-spec{data-element=VeCANR_b_BMS_HV_SOC_Max_FD11TO, init-value=VeCANR_b_BMS_HV_SOC_Max_FD11TOValue:0}, provided-interface=VeCANR_b_BMS_HV_SOC_Max_FD11TO
      VeCANR_Pct_BMS_HV_SOC_Min_FD11: nonqueued-sender-com-spec{data-element=VeCANR_Pct_BMS_HV_SOC_Min_FD11, init-value=VeCANR_Pct_BMS_HV_SOC_Min_FD11Value:19.56285}, provided-interface=VeCANR_Pct_BMS_HV_SOC_Min_FD11
      VeCANR_b_BMS_HV_SOC_Min_FD11TO: nonqueued-sender-com-spec{data-element=VeCANR_b_BMS_HV_SOC_Min_FD11TO, init-value=VeCANR_b_BMS_HV_SOC_Min_FD11TOValue:0}, provided-interface=VeCANR_b_BMS_HV_SOC_Min_FD11TO
      VeCANR_b_HEV_OnRq_BPCM_FD11: nonqueued-sender-com-spec{data-element=VeCANR_b_HEV_OnRq_BPCM_FD11, init-value=VeCANR_b_HEV_OnRq_BPCM_FD11Value:0}, provided-interface=VeCANR_b_HEV_OnRq_BPCM_FD11
      VeCANR_b_HEV_OnRq_BPCM_FD11TO: nonqueued-sender-com-spec{data-element=VeCANR_b_HEV_OnRq_BPCM_FD11TO, init-value=VeCANR_b_HEV_OnRq_BPCM_FD11TOValue:0}, provided-interface=VeCANR_b_HEV_OnRq_BPCM_FD11TO
      VeCANR_d_HVBatCelVoltHiThrsFD11: nonqueued-sender-com-spec{data-element=VeCANR_d_HVBatCelVoltHiThrsFD11, init-value=VeCANR_d_HVBatCelVoltHiThrsFD11Value:0}, provided-interface=VeCANR_d_HVBatCelVoltHiThrsFD11
      VeCANR_b_HVBatCelVoltHiThrsFD11TO: nonqueued-sender-com-spec{data-element=VeCANR_b_HVBatCelVoltHiThrsFD11TO, init-value=VeCANR_b_HVBatCelVoltHiThrsFD11TOValue:0}, provided-interface=VeCANR_b_HVBatCelVoltHiThrsFD11TO
      VeCANR_h_HVBatCelVoltLoThrsFD11: nonqueued-sender-com-spec{data-element=VeCANR_h_HVBatCelVoltLoThrsFD11, init-value=VeCANR_h_HVBatCelVoltLoThrsFD11Value:0}, provided-interface=VeCANR_h_HVBatCelVoltLoThrsFD11
      VeCANR_b_HVBatCelVoltLoThrsFD11TO: nonqueued-sender-com-spec{data-element=VeCANR_b_HVBatCelVoltLoThrsFD11TO, init-value=VeCANR_b_HVBatCelVoltLoThrsFD11TOValue:0}, provided-interface=VeCANR_b_HVBatCelVoltLoThrsFD11TO
      VeCANR_T_OBC_Temp1_FD11: nonqueued-sender-com-spec{data-element=VeCANR_T_OBC_Temp1_FD11, init-value=VeCANR_T_OBC_Temp1_FD11Value:-40}, provided-interface=VeCANR_T_OBC_Temp1_FD11
      VeCANR_b_OBC_Temp1_FD11TO: nonqueued-sender-com-spec{data-element=VeCANR_b_OBC_Temp1_FD11TO, init-value=VeCANR_b_OBC_Temp1_FD11TOValue:0}, provided-interface=VeCANR_b_OBC_Temp1_FD11TO
      VeCANR_T_OBC_Temp2_FD11: nonqueued-sender-com-spec{data-element=VeCANR_T_OBC_Temp2_FD11, init-value=VeCANR_T_OBC_Temp2_FD11Value:-40}, provided-interface=VeCANR_T_OBC_Temp2_FD11
      VeCANR_b_OBC_Temp2_FD11TO: nonqueued-sender-com-spec{data-element=VeCANR_b_OBC_Temp2_FD11TO, init-value=VeCANR_b_OBC_Temp2_FD11TOValue:0}, provided-interface=VeCANR_b_OBC_Temp2_FD11TO
      VeCANR_T_OBC_Temp3_FD11: nonqueued-sender-com-spec{data-element=VeCANR_T_OBC_Temp3_FD11, init-value=VeCANR_T_OBC_Temp3_FD11Value:-40}, provided-interface=VeCANR_T_OBC_Temp3_FD11
      VeCANR_b_OBC_Temp3_FD11TO: nonqueued-sender-com-spec{data-element=VeCANR_b_OBC_Temp3_FD11TO, init-value=VeCANR_b_OBC_Temp3_FD11TOValue:0}, provided-interface=VeCANR_b_OBC_Temp3_FD11TO
      VeCANR_T_OBC_Temp4_FD11: nonqueued-sender-com-spec{data-element=VeCANR_T_OBC_Temp4_FD11, init-value=VeCANR_T_OBC_Temp4_FD11Value:-40}, provided-interface=VeCANR_T_OBC_Temp4_FD11
      VeCANR_b_OBC_Temp4_FD11TO: nonqueued-sender-com-spec{data-element=VeCANR_b_OBC_Temp4_FD11TO, init-value=VeCANR_b_OBC_Temp4_FD11TOValue:0}, provided-interface=VeCANR_b_OBC_Temp4_FD11TO
      VeCANR_y_CRC_FOTA_MASTER: nonqueued-sender-com-spec{data-element=VeCANR_y_CRC_FOTA_MASTER, init-value=VeCANR_y_CRC_FOTA_MASTERValue:0}, provided-interface=VeCANR_y_CRC_FOTA_MASTER
      VeCANR_b_CRC_FOTA_MASTER_TO: nonqueued-sender-com-spec{data-element=VeCANR_b_CRC_FOTA_MASTER_TO, init-value=VeCANR_b_CRC_FOTA_MASTER_TOValue:0}, provided-interface=VeCANR_b_CRC_FOTA_MASTER_TO
      VeCANR_e_FOTA_Status: nonqueued-sender-com-spec{data-element=VeCANR_e_FOTA_Status, init-value=VeCANR_e_FOTA_StatusValue:0}, provided-interface=VeCANR_e_FOTA_Status
      VeCANR_b_FOTA_StatusTO: nonqueued-sender-com-spec{data-element=VeCANR_b_FOTA_StatusTO, init-value=VeCANR_b_FOTA_StatusTOValue:0}, provided-interface=VeCANR_b_FOTA_StatusTO
      VeCANR_y_MC_FOTA_MASTER: nonqueued-sender-com-spec{data-element=VeCANR_y_MC_FOTA_MASTER, init-value=VeCANR_y_MC_FOTA_MASTERValue:0}, provided-interface=VeCANR_y_MC_FOTA_MASTER
      VeCANR_b_MC_FOTA_MASTER_TO: nonqueued-sender-com-spec{data-element=VeCANR_b_MC_FOTA_MASTER_TO, init-value=VeCANR_b_MC_FOTA_MASTER_TOValue:0}, provided-interface=VeCANR_b_MC_FOTA_MASTER_TO
      VeCANR_cmp_N_PDU_7E_FD11: nonqueued-sender-com-spec{data-element=VeCANR_cmp_N_PDU_7E_FD11, init-value=VeCANR_cmp_N_PDU_7E_FD11Value:0}, provided-interface=VeCANR_cmp_N_PDU_7E_FD11
      VeCANR_b_N_PDU_7E_FD11TO: nonqueued-sender-com-spec{data-element=VeCANR_b_N_PDU_7E_FD11TO, init-value=VeCANR_b_N_PDU_7E_FD11TOValue:0}, provided-interface=VeCANR_b_N_PDU_7E_FD11TO
      VeCANR_cmp_N_PDU_7F_FD11: nonqueued-sender-com-spec{data-element=VeCANR_cmp_N_PDU_7F_FD11, init-value=VeCANR_cmp_N_PDU_7F_FD11Value:0}, provided-interface=VeCANR_cmp_N_PDU_7F_FD11
      VeCANR_b_N_PDU_7F_FD11TO: nonqueued-sender-com-spec{data-element=VeCANR_b_N_PDU_7F_FD11TO, init-value=VeCANR_b_N_PDU_7F_FD11TOValue:0}, provided-interface=VeCANR_b_N_PDU_7F_FD11TO
      VeCANR_cmp_N_PDU_81_FD11: nonqueued-sender-com-spec{data-element=VeCANR_cmp_N_PDU_81_FD11, init-value=VeCANR_cmp_N_PDU_81_FD11Value:0}, provided-interface=VeCANR_cmp_N_PDU_81_FD11
      VeCANR_b_N_PDU_81_FD11TO: nonqueued-sender-com-spec{data-element=VeCANR_b_N_PDU_81_FD11TO, init-value=VeCANR_b_N_PDU_81_FD11TOValue:0}, provided-interface=VeCANR_b_N_PDU_81_FD11TO
      VeCANR_cmp_N_PDU_343_FD11: nonqueued-sender-com-spec{data-element=VeCANR_cmp_N_PDU_343_FD11, init-value=VeCANR_cmp_N_PDU_343_FD11Value:0}, provided-interface=VeCANR_cmp_N_PDU_343_FD11
      VeCANR_b_N_PDU_343_FD11TO: nonqueued-sender-com-spec{data-element=VeCANR_b_N_PDU_343_FD11TO, init-value=VeCANR_b_N_PDU_343_FD11TOValue:0}, provided-interface=VeCANR_b_N_PDU_343_FD11TO
      VeCANR_b_HVBatteryMILReq_FD11: nonqueued-sender-com-spec{data-element=VeCANR_b_HVBatteryMILReq_FD11, init-value=VeCANR_b_HVBatteryMILReq_FD11Value:0}, provided-interface=VeCANR_b_HVBatteryMILReq_FD11
      VeCANR_b_HVBatteryMILReq_FD11TO: nonqueued-sender-com-spec{data-element=VeCANR_b_HVBatteryMILReq_FD11TO, init-value=VeCANR_b_HVBatteryMILReq_FD11TOValue:0}, provided-interface=VeCANR_b_HVBatteryMILReq_FD11TO
      VeCANR_t_HVBattRealTimeClkFD11: nonqueued-sender-com-spec{data-element=VeCANR_t_HVBattRealTimeClkFD11, init-value=VeCANR_t_HVBattRealTimeClkFD11Value:0}, provided-interface=VeCANR_t_HVBattRealTimeClkFD11
      VeCANR_b_HVBattRealTimeClkFD11TO: nonqueued-sender-com-spec{data-element=VeCANR_b_HVBattRealTimeClkFD11TO, init-value=VeCANR_b_HVBattRealTimeClkFD11TOValue:0}, provided-interface=VeCANR_b_HVBattRealTimeClkFD11TO
      VeCANR_b_HVBattRealTimeClkVFD11: nonqueued-sender-com-spec{data-element=VeCANR_b_HVBattRealTimeClkVFD11, init-value=VeCANR_b_HVBattRealTimeClkVFD11Value:0}, provided-interface=VeCANR_b_HVBattRealTimeClkVFD11
      VeCANR_b_HVBattRealTimeClkVFD11TO: nonqueued-sender-com-spec{data-element=VeCANR_b_HVBattRealTimeClkVFD11TO, init-value=VeCANR_b_HVBattRealTimeClkVFD11TOValue:0}, provided-interface=VeCANR_b_HVBattRealTimeClkVFD11TO
      VeCANR_b_Wrng_PackTempHigh_FD11: nonqueued-sender-com-spec{data-element=VeCANR_b_Wrng_PackTempHigh_FD11, init-value=VeCANR_b_Wrng_PackTempHigh_FD11Value:0}, provided-interface=VeCANR_b_Wrng_PackTempHigh_FD11
      VeCANR_b_Wrng_PackTempHigh_FD11TO: nonqueued-sender-com-spec{data-element=VeCANR_b_Wrng_PackTempHigh_FD11TO, init-value=VeCANR_b_Wrng_PackTempHigh_FD11TOValue:0}, provided-interface=VeCANR_b_Wrng_PackTempHigh_FD11TO
      VeCANR_t_HVBatSleepTime_FD11: nonqueued-sender-com-spec{data-element=VeCANR_t_HVBatSleepTime_FD11, init-value=VeCANR_t_HVBatSleepTime_FD11Value:0}, provided-interface=VeCANR_t_HVBatSleepTime_FD11
      VeCANR_b_HVBatSleepTime_FD11TO: nonqueued-sender-com-spec{data-element=VeCANR_b_HVBatSleepTime_FD11TO, init-value=VeCANR_b_HVBatSleepTime_FD11TOValue:0}, provided-interface=VeCANR_b_HVBatSleepTime_FD11TO
      VeCANR_I_CdMAvailopcurentEXT: nonqueued-sender-com-spec{data-element=VeCANR_I_CdMAvailopcurentEXT, init-value=VeCANR_I_CdMAvailopcurentEXTValue:0}, provided-interface=VeCANR_I_CdMAvailopcurentEXT
      VeCANR_b_CdMAvailopcurentEXT_TO: nonqueued-sender-com-spec{data-element=VeCANR_b_CdMAvailopcurentEXT_TO, init-value=VeCANR_b_CdMAvailopcurentEXT_TOValue:0}, provided-interface=VeCANR_b_CdMAvailopcurentEXT_TO
      VeCANR_b_CdMChargerconnectlock: nonqueued-sender-com-spec{data-element=VeCANR_b_CdMChargerconnectlock, init-value=VeCANR_b_CdMChargerconnectlockValue:0}, provided-interface=VeCANR_b_CdMChargerconnectlock
      VeCANR_b_CdMChargerconnectlockTO: nonqueued-sender-com-spec{data-element=VeCANR_b_CdMChargerconnectlockTO, init-value=VeCANR_b_CdMChargerconnectlockTOValue:0}, provided-interface=VeCANR_b_CdMChargerconnectlockTO
      VeCANR_U_CdM_ExtFun_Thres_Volt: nonqueued-sender-com-spec{data-element=VeCANR_U_CdM_ExtFun_Thres_Volt, init-value=VeCANR_U_CdM_ExtFun_Thres_VoltValue:0}, provided-interface=VeCANR_U_CdM_ExtFun_Thres_Volt
      VeCANR_b_CdM_ExtFun_Thres_VoltTO: nonqueued-sender-com-spec{data-element=VeCANR_b_CdM_ExtFun_Thres_VoltTO, init-value=VeCANR_b_CdM_ExtFun_Thres_VoltTOValue:0}, provided-interface=VeCANR_b_CdM_ExtFun_Thres_VoltTO
      VeCANR_b_EVSEBTRyCompatibilty: nonqueued-sender-com-spec{data-element=VeCANR_b_EVSEBTRyCompatibilty, init-value=VeCANR_b_EVSEBTRyCompatibiltyValue:0}, provided-interface=VeCANR_b_EVSEBTRyCompatibilty
      VeCANR_b_EVSEBTRyCompatibiltyTO: nonqueued-sender-com-spec{data-element=VeCANR_b_EVSEBTRyCompatibiltyTO, init-value=VeCANR_b_EVSEBTRyCompatibiltyTOValue:0}, provided-interface=VeCANR_b_EVSEBTRyCompatibiltyTO
      VeCANR_e_EVSE_CHAdeMOProtocol: nonqueued-sender-com-spec{data-element=VeCANR_e_EVSE_CHAdeMOProtocol, init-value=VeCANR_e_EVSE_CHAdeMOProtocolValue:0}, provided-interface=VeCANR_e_EVSE_CHAdeMOProtocol
      VeCANR_b_EVSE_CHAdeMOProtocolTO: nonqueued-sender-com-spec{data-element=VeCANR_b_EVSE_CHAdeMOProtocolTO, init-value=VeCANR_b_EVSE_CHAdeMOProtocolTOValue:0}, provided-interface=VeCANR_b_EVSE_CHAdeMOProtocolTO
      VeCANR_b_EVSEChargingStmError: nonqueued-sender-com-spec{data-element=VeCANR_b_EVSEChargingStmError, init-value=VeCANR_b_EVSEChargingStmErrorValue:0}, provided-interface=VeCANR_b_EVSEChargingStmError
      VeCANR_b_EVSEChargingStmErrorTO: nonqueued-sender-com-spec{data-element=VeCANR_b_EVSEChargingStmErrorTO, init-value=VeCANR_b_EVSEChargingStmErrorTOValue:0}, provided-interface=VeCANR_b_EVSEChargingStmErrorTO
      VeCANR_b_EVSE_EnergizingState: nonqueued-sender-com-spec{data-element=VeCANR_b_EVSE_EnergizingState, init-value=VeCANR_b_EVSE_EnergizingStateValue:0}, provided-interface=VeCANR_b_EVSE_EnergizingState
      VeCANR_b_EVSE_EnergizingStateTO: nonqueued-sender-com-spec{data-element=VeCANR_b_EVSE_EnergizingStateTO, init-value=VeCANR_b_EVSE_EnergizingStateTOValue:0}, provided-interface=VeCANR_b_EVSE_EnergizingStateTO
      VeCANR_t_EVSE_RemainingMin: nonqueued-sender-com-spec{data-element=VeCANR_t_EVSE_RemainingMin, init-value=VeCANR_t_EVSE_RemainingMinValue:0}, provided-interface=VeCANR_t_EVSE_RemainingMin
      VeCANR_b_EVSE_RemainingMinTO: nonqueued-sender-com-spec{data-element=VeCANR_b_EVSE_RemainingMinTO, init-value=VeCANR_b_EVSE_RemainingMinTOValue:0}, provided-interface=VeCANR_b_EVSE_RemainingMinTO
      VeCANR_t_EVSE_RemainingSec: nonqueued-sender-com-spec{data-element=VeCANR_t_EVSE_RemainingSec, init-value=VeCANR_t_EVSE_RemainingSecValue:0}, provided-interface=VeCANR_t_EVSE_RemainingSec
      VeCANR_b_EVSE_RemainingSecTO: nonqueued-sender-com-spec{data-element=VeCANR_b_EVSE_RemainingSecTO, init-value=VeCANR_b_EVSE_RemainingSecTOValue:0}, provided-interface=VeCANR_b_EVSE_RemainingSecTO
      VeCANR_U_EVSE_ThrshldVoltage: nonqueued-sender-com-spec{data-element=VeCANR_U_EVSE_ThrshldVoltage, init-value=VeCANR_U_EVSE_ThrshldVoltageValue:0}, provided-interface=VeCANR_U_EVSE_ThrshldVoltage
      VeCANR_b_EVSE_ThrshldVoltageTO: nonqueued-sender-com-spec{data-element=VeCANR_b_EVSE_ThrshldVoltageTO, init-value=VeCANR_b_EVSE_ThrshldVoltageTOValue:0}, provided-interface=VeCANR_b_EVSE_ThrshldVoltageTO
      VeCANR_y_CRC_IDCM_OBD_DTC: nonqueued-sender-com-spec{data-element=VeCANR_y_CRC_IDCM_OBD_DTC, init-value=VeCANR_y_CRC_IDCM_OBD_DTCValue:0}, provided-interface=VeCANR_y_CRC_IDCM_OBD_DTC
      VeCANR_b_CRC_IDCM_OBD_DTC_TO: nonqueued-sender-com-spec{data-element=VeCANR_b_CRC_IDCM_OBD_DTC_TO, init-value=VeCANR_b_CRC_IDCM_OBD_DTC_TOValue:0}, provided-interface=VeCANR_b_CRC_IDCM_OBD_DTC_TO
      VeCANR_y_IDCM_CAL_ID: nonqueued-sender-com-spec{data-element=VeCANR_y_IDCM_CAL_ID, init-value=VeCANR_y_IDCM_CAL_IDValue:0}, provided-interface=VeCANR_y_IDCM_CAL_ID
      VeCANR_b_IDCM_CAL_ID_TO: nonqueued-sender-com-spec{data-element=VeCANR_b_IDCM_CAL_ID_TO, init-value=VeCANR_b_IDCM_CAL_ID_TOValue:0}, provided-interface=VeCANR_b_IDCM_CAL_ID_TO
      VeCANR_y_IDCM_CAL_VN: nonqueued-sender-com-spec{data-element=VeCANR_y_IDCM_CAL_VN, init-value=VeCANR_y_IDCM_CAL_VNValue:0}, provided-interface=VeCANR_y_IDCM_CAL_VN
      VeCANR_b_IDCM_CAL_VN_TO: nonqueued-sender-com-spec{data-element=VeCANR_b_IDCM_CAL_VN_TO, init-value=VeCANR_b_IDCM_CAL_VN_TOValue:0}, provided-interface=VeCANR_b_IDCM_CAL_VN_TO
      VeCANR_y_IDCM_DTC_Idx1: nonqueued-sender-com-spec{data-element=VeCANR_y_IDCM_DTC_Idx1, init-value=VeCANR_y_IDCM_DTC_Idx1Value:0}, provided-interface=VeCANR_y_IDCM_DTC_Idx1
      VeCANR_b_IDCM_DTC_Idx1TO: nonqueued-sender-com-spec{data-element=VeCANR_b_IDCM_DTC_Idx1TO, init-value=VeCANR_b_IDCM_DTC_Idx1TOValue:0}, provided-interface=VeCANR_b_IDCM_DTC_Idx1TO
      VeCANR_y_IDCM_DTC_Idx2: nonqueued-sender-com-spec{data-element=VeCANR_y_IDCM_DTC_Idx2, init-value=VeCANR_y_IDCM_DTC_Idx2Value:0}, provided-interface=VeCANR_y_IDCM_DTC_Idx2
      VeCANR_b_IDCM_DTC_Idx2TO: nonqueued-sender-com-spec{data-element=VeCANR_b_IDCM_DTC_Idx2TO, init-value=VeCANR_b_IDCM_DTC_Idx2TOValue:0}, provided-interface=VeCANR_b_IDCM_DTC_Idx2TO
      VeCANR_y_IDCM_DTC_Idx3: nonqueued-sender-com-spec{data-element=VeCANR_y_IDCM_DTC_Idx3, init-value=VeCANR_y_IDCM_DTC_Idx3Value:0}, provided-interface=VeCANR_y_IDCM_DTC_Idx3
      VeCANR_b_IDCM_DTC_Idx3TO: nonqueued-sender-com-spec{data-element=VeCANR_b_IDCM_DTC_Idx3TO, init-value=VeCANR_b_IDCM_DTC_Idx3TOValue:0}, provided-interface=VeCANR_b_IDCM_DTC_Idx3TO
      VeCANR_y_IDCM_DTC_Idx4: nonqueued-sender-com-spec{data-element=VeCANR_y_IDCM_DTC_Idx4, init-value=VeCANR_y_IDCM_DTC_Idx4Value:0}, provided-interface=VeCANR_y_IDCM_DTC_Idx4
      VeCANR_b_IDCM_DTC_Idx4TO: nonqueued-sender-com-spec{data-element=VeCANR_b_IDCM_DTC_Idx4TO, init-value=VeCANR_b_IDCM_DTC_Idx4TOValue:0}, provided-interface=VeCANR_b_IDCM_DTC_Idx4TO
      VeCANR_y_IDCM_DTC_Idx5: nonqueued-sender-com-spec{data-element=VeCANR_y_IDCM_DTC_Idx5, init-value=VeCANR_y_IDCM_DTC_Idx5Value:0}, provided-interface=VeCANR_y_IDCM_DTC_Idx5
      VeCANR_b_IDCM_DTC_Idx5TO: nonqueued-sender-com-spec{data-element=VeCANR_b_IDCM_DTC_Idx5TO, init-value=VeCANR_b_IDCM_DTC_Idx5TOValue:0}, provided-interface=VeCANR_b_IDCM_DTC_Idx5TO
      VeCANR_y_IDCM_DTC_Idx6: nonqueued-sender-com-spec{data-element=VeCANR_y_IDCM_DTC_Idx6, init-value=VeCANR_y_IDCM_DTC_Idx6Value:0}, provided-interface=VeCANR_y_IDCM_DTC_Idx6
      VeCANR_b_IDCM_DTC_Idx6TO: nonqueued-sender-com-spec{data-element=VeCANR_b_IDCM_DTC_Idx6TO, init-value=VeCANR_b_IDCM_DTC_Idx6TOValue:0}, provided-interface=VeCANR_b_IDCM_DTC_Idx6TO
      VeCANR_y_IDCM_DTC_Idx7: nonqueued-sender-com-spec{data-element=VeCANR_y_IDCM_DTC_Idx7, init-value=VeCANR_y_IDCM_DTC_Idx7Value:0}, provided-interface=VeCANR_y_IDCM_DTC_Idx7
      VeCANR_b_IDCM_DTC_Idx7TO: nonqueued-sender-com-spec{data-element=VeCANR_b_IDCM_DTC_Idx7TO, init-value=VeCANR_b_IDCM_DTC_Idx7TOValue:0}, provided-interface=VeCANR_b_IDCM_DTC_Idx7TO
      VeCANR_y_IDCM_DTC_Idx8: nonqueued-sender-com-spec{data-element=VeCANR_y_IDCM_DTC_Idx8, init-value=VeCANR_y_IDCM_DTC_Idx8Value:0}, provided-interface=VeCANR_y_IDCM_DTC_Idx8
      VeCANR_b_IDCM_DTC_Idx8TO: nonqueued-sender-com-spec{data-element=VeCANR_b_IDCM_DTC_Idx8TO, init-value=VeCANR_b_IDCM_DTC_Idx8TOValue:0}, provided-interface=VeCANR_b_IDCM_DTC_Idx8TO
      VeCANR_e_IDCM_DTC_Stat1: nonqueued-sender-com-spec{data-element=VeCANR_e_IDCM_DTC_Stat1, init-value=VeCANR_e_IDCM_DTC_Stat1Value:0}, provided-interface=VeCANR_e_IDCM_DTC_Stat1
      VeCANR_b_IDCM_DTC_Stat1TO: nonqueued-sender-com-spec{data-element=VeCANR_b_IDCM_DTC_Stat1TO, init-value=VeCANR_b_IDCM_DTC_Stat1TOValue:0}, provided-interface=VeCANR_b_IDCM_DTC_Stat1TO
      VeCANR_e_IDCM_DTC_Stat2: nonqueued-sender-com-spec{data-element=VeCANR_e_IDCM_DTC_Stat2, init-value=VeCANR_e_IDCM_DTC_Stat2Value:0}, provided-interface=VeCANR_e_IDCM_DTC_Stat2
      VeCANR_b_IDCM_DTC_Stat2TO: nonqueued-sender-com-spec{data-element=VeCANR_b_IDCM_DTC_Stat2TO, init-value=VeCANR_b_IDCM_DTC_Stat2TOValue:0}, provided-interface=VeCANR_b_IDCM_DTC_Stat2TO
      VeCANR_e_IDCM_DTC_Stat3: nonqueued-sender-com-spec{data-element=VeCANR_e_IDCM_DTC_Stat3, init-value=VeCANR_e_IDCM_DTC_Stat3Value:0}, provided-interface=VeCANR_e_IDCM_DTC_Stat3
      VeCANR_b_IDCM_DTC_Stat3TO: nonqueued-sender-com-spec{data-element=VeCANR_b_IDCM_DTC_Stat3TO, init-value=VeCANR_b_IDCM_DTC_Stat3TOValue:0}, provided-interface=VeCANR_b_IDCM_DTC_Stat3TO
      VeCANR_e_IDCM_DTC_Stat4: nonqueued-sender-com-spec{data-element=VeCANR_e_IDCM_DTC_Stat4, init-value=VeCANR_e_IDCM_DTC_Stat4Value:0}, provided-interface=VeCANR_e_IDCM_DTC_Stat4
      VeCANR_b_IDCM_DTC_Stat4TO: nonqueued-sender-com-spec{data-element=VeCANR_b_IDCM_DTC_Stat4TO, init-value=VeCANR_b_IDCM_DTC_Stat4TOValue:0}, provided-interface=VeCANR_b_IDCM_DTC_Stat4TO
      VeCANR_e_IDCM_DTC_Stat5: nonqueued-sender-com-spec{data-element=VeCANR_e_IDCM_DTC_Stat5, init-value=VeCANR_e_IDCM_DTC_Stat5Value:0}, provided-interface=VeCANR_e_IDCM_DTC_Stat5
      VeCANR_b_IDCM_DTC_Stat5TO: nonqueued-sender-com-spec{data-element=VeCANR_b_IDCM_DTC_Stat5TO, init-value=VeCANR_b_IDCM_DTC_Stat5TOValue:0}, provided-interface=VeCANR_b_IDCM_DTC_Stat5TO
      VeCANR_e_IDCM_DTC_Stat6: nonqueued-sender-com-spec{data-element=VeCANR_e_IDCM_DTC_Stat6, init-value=VeCANR_e_IDCM_DTC_Stat6Value:0}, provided-interface=VeCANR_e_IDCM_DTC_Stat6
      VeCANR_b_IDCM_DTC_Stat6TO: nonqueued-sender-com-spec{data-element=VeCANR_b_IDCM_DTC_Stat6TO, init-value=VeCANR_b_IDCM_DTC_Stat6TOValue:0}, provided-interface=VeCANR_b_IDCM_DTC_Stat6TO
      VeCANR_e_IDCM_DTC_Stat7: nonqueued-sender-com-spec{data-element=VeCANR_e_IDCM_DTC_Stat7, init-value=VeCANR_e_IDCM_DTC_Stat7Value:0}, provided-interface=VeCANR_e_IDCM_DTC_Stat7
      VeCANR_b_IDCM_DTC_Stat7TO: nonqueued-sender-com-spec{data-element=VeCANR_b_IDCM_DTC_Stat7TO, init-value=VeCANR_b_IDCM_DTC_Stat7TOValue:0}, provided-interface=VeCANR_b_IDCM_DTC_Stat7TO
      VeCANR_e_IDCM_DTC_Stat8: nonqueued-sender-com-spec{data-element=VeCANR_e_IDCM_DTC_Stat8, init-value=VeCANR_e_IDCM_DTC_Stat8Value:0}, provided-interface=VeCANR_e_IDCM_DTC_Stat8
      VeCANR_b_IDCM_DTC_Stat8TO: nonqueued-sender-com-spec{data-element=VeCANR_b_IDCM_DTC_Stat8TO, init-value=VeCANR_b_IDCM_DTC_Stat8TOValue:0}, provided-interface=VeCANR_b_IDCM_DTC_Stat8TO
      VeCANR_y_IDCM_RBM_Idx: nonqueued-sender-com-spec{data-element=VeCANR_y_IDCM_RBM_Idx, init-value=VeCANR_y_IDCM_RBM_IdxValue:0}, provided-interface=VeCANR_y_IDCM_RBM_Idx
      VeCANR_b_IDCM_RBM_IdxTO: nonqueued-sender-com-spec{data-element=VeCANR_b_IDCM_RBM_IdxTO, init-value=VeCANR_b_IDCM_RBM_IdxTOValue:0}, provided-interface=VeCANR_b_IDCM_RBM_IdxTO
      VeCANR_y_IDCM_RBM_Stat: nonqueued-sender-com-spec{data-element=VeCANR_y_IDCM_RBM_Stat, init-value=VeCANR_y_IDCM_RBM_StatValue:0}, provided-interface=VeCANR_y_IDCM_RBM_Stat
      VeCANR_b_IDCM_RBM_StatTO: nonqueued-sender-com-spec{data-element=VeCANR_b_IDCM_RBM_StatTO, init-value=VeCANR_b_IDCM_RBM_StatTOValue:0}, provided-interface=VeCANR_b_IDCM_RBM_StatTO
      VeCANR_y_MCIDCMOBDDTC: nonqueued-sender-com-spec{data-element=VeCANR_y_MCIDCMOBDDTC, init-value=VeCANR_y_MCIDCMOBDDTCValue:0}, provided-interface=VeCANR_y_MCIDCMOBDDTC
      VeCANR_b_MCIDCMOBDDTC_TO: nonqueued-sender-com-spec{data-element=VeCANR_b_MCIDCMOBDDTC_TO, init-value=VeCANR_b_MCIDCMOBDDTC_TOValue:0}, provided-interface=VeCANR_b_MCIDCMOBDDTC_TO
      VeCANR_b_IDCM_Wakeup_HCP_FD11: nonqueued-sender-com-spec{data-element=VeCANR_b_IDCM_Wakeup_HCP_FD11, init-value=VeCANR_b_IDCM_Wakeup_HCP_FD11Value:0}, provided-interface=VeCANR_b_IDCM_Wakeup_HCP_FD11
      VeCANR_b_IDCM_Wakeup_HCP_FD11TO: nonqueued-sender-com-spec{data-element=VeCANR_b_IDCM_Wakeup_HCP_FD11TO, init-value=VeCANR_b_IDCM_Wakeup_HCP_FD11TOValue:0}, provided-interface=VeCANR_b_IDCM_Wakeup_HCP_FD11TO
    274 x require port:
      SendCANR_CmdIgnSts_FD11: nonqueued-receiver-com-spec{data-element=SendCANR_CmdIgnSts_FD11, init-value=SendCANR_CmdIgnSts_FD11Value:0}, required-interface=SendCANR_CmdIgnSts_FD11
      SendCANR_CmdIgnSts_FD11Vld: nonqueued-receiver-com-spec{data-element=SendCANR_CmdIgnSts_FD11Vld, init-value=SendCANR_CmdIgnSts_FD11VldValue:1}, required-interface=SendCANR_CmdIgnSts_FD11Vld
      SendCANR_ExternTemperatureCFD11: nonqueued-receiver-com-spec{data-element=SendCANR_ExternTemperatureCFD11, init-value=SendCANR_ExternTemperatureCFD11Value:170.5}, required-interface=SendCANR_ExternTemperatureCFD11
      SendCANR_ExternTemperatureCFD11Vld: nonqueued-receiver-com-spec{data-element=SendCANR_ExternTemperatureCFD11Vld, init-value=SendCANR_ExternTemperatureCFD11VldValue:1}, required-interface=SendCANR_ExternTemperatureCFD11Vld
      SendCANR_OperationalModeStsFD11: nonqueued-receiver-com-spec{data-element=SendCANR_OperationalModeStsFD11, init-value=SendCANR_OperationalModeStsFD11Value:0}, required-interface=SendCANR_OperationalModeStsFD11
      SendCANR_OperationalModeStsFD11Vld: nonqueued-receiver-com-spec{data-element=SendCANR_OperationalModeStsFD11Vld, init-value=SendCANR_OperationalModeStsFD11VldValue:1}, required-interface=SendCANR_OperationalModeStsFD11Vld
      SendCANR_Battery_Volt_1_FD11: nonqueued-receiver-com-spec{data-element=SendCANR_Battery_Volt_1_FD11, init-value=SendCANR_Battery_Volt_1_FD11Value:5}, required-interface=SendCANR_Battery_Volt_1_FD11
      SendCANR_Battery_Volt_1_FD11Vld: nonqueued-receiver-com-spec{data-element=SendCANR_Battery_Volt_1_FD11Vld, init-value=SendCANR_Battery_Volt_1_FD11VldValue:1}, required-interface=SendCANR_Battery_Volt_1_FD11Vld
      SendCANR_IgnitionOnCounter_FD11: nonqueued-receiver-com-spec{data-element=SendCANR_IgnitionOnCounter_FD11, init-value=SendCANR_IgnitionOnCounter_FD11Value:0}, required-interface=SendCANR_IgnitionOnCounter_FD11
      SendCANR_IgnitionOnCounter_FD11Vld: nonqueued-receiver-com-spec{data-element=SendCANR_IgnitionOnCounter_FD11Vld, init-value=SendCANR_IgnitionOnCounter_FD11VldValue:1}, required-interface=SendCANR_IgnitionOnCounter_FD11Vld
      SendCANR_ExtTemp_FD11: nonqueued-receiver-com-spec{data-element=SendCANR_ExtTemp_FD11, init-value=SendCANR_ExtTemp_FD11Value:-85}, required-interface=SendCANR_ExtTemp_FD11
      SendCANR_ExtTemp_FD11Vld: nonqueued-receiver-com-spec{data-element=SendCANR_ExtTemp_FD11Vld, init-value=SendCANR_ExtTemp_FD11VldValue:1}, required-interface=SendCANR_ExtTemp_FD11Vld
      SendCANR_VehicleSpeedVSOSigFD11: nonqueued-receiver-com-spec{data-element=SendCANR_VehicleSpeedVSOSigFD11, init-value=SendCANR_VehicleSpeedVSOSigFD11Value:0}, required-interface=SendCANR_VehicleSpeedVSOSigFD11
      SendCANR_VehicleSpeedVSOSigFD11Vld: nonqueued-receiver-com-spec{data-element=SendCANR_VehicleSpeedVSOSigFD11Vld, init-value=SendCANR_VehicleSpeedVSOSigFD11VldValue:1}, required-interface=SendCANR_VehicleSpeedVSOSigFD11Vld
      SendCANR_EPBSts_FD11: nonqueued-receiver-com-spec{data-element=SendCANR_EPBSts_FD11, init-value=SendCANR_EPBSts_FD11Value:0}, required-interface=SendCANR_EPBSts_FD11
      SendCANR_EPBSts_FD11Vld: nonqueued-receiver-com-spec{data-element=SendCANR_EPBSts_FD11Vld, init-value=SendCANR_EPBSts_FD11VldValue:1}, required-interface=SendCANR_EPBSts_FD11Vld
      SendCANR_EngineSpeed_W_FD11: nonqueued-receiver-com-spec{data-element=SendCANR_EngineSpeed_W_FD11, init-value=SendCANR_EngineSpeed_W_FD11Value:0}, required-interface=SendCANR_EngineSpeed_W_FD11
      SendCANR_EngineSpeed_W_FD11Vld: nonqueued-receiver-com-spec{data-element=SendCANR_EngineSpeed_W_FD11Vld, init-value=SendCANR_EngineSpeed_W_FD11VldValue:1}, required-interface=SendCANR_EngineSpeed_W_FD11Vld
      SendCANR_PtPrplsnActv_FD11: nonqueued-receiver-com-spec{data-element=SendCANR_PtPrplsnActv_FD11, init-value=SendCANR_PtPrplsnActv_FD11Value:0}, required-interface=SendCANR_PtPrplsnActv_FD11
      SendCANR_PtPrplsnActv_FD11Vld: nonqueued-receiver-com-spec{data-element=SendCANR_PtPrplsnActv_FD11Vld, init-value=SendCANR_PtPrplsnActv_FD11VldValue:1}, required-interface=SendCANR_PtPrplsnActv_FD11Vld
      SendCANR_BattVoltDeviationErr: nonqueued-receiver-com-spec{data-element=SendCANR_BattVoltDeviationErr, init-value=SendCANR_BattVoltDeviationErrValue:0}, required-interface=SendCANR_BattVoltDeviationErr
      SendCANR_BattVoltDeviationErrVld: nonqueued-receiver-com-spec{data-element=SendCANR_BattVoltDeviationErrVld, init-value=SendCANR_BattVoltDeviationErrVldValue:1}, required-interface=SendCANR_BattVoltDeviationErrVld
      SendCANR_CdM_Chrgcurrentreqext: nonqueued-receiver-com-spec{data-element=SendCANR_CdM_Chrgcurrentreqext, init-value=SendCANR_CdM_ChrgcurrentreqextValue:0}, required-interface=SendCANR_CdM_Chrgcurrentreqext
      SendCANR_CdM_ChrgcurrentreqextVld: nonqueued-receiver-com-spec{data-element=SendCANR_CdM_ChrgcurrentreqextVld, init-value=SendCANR_CdM_ChrgcurrentreqextVldValue:1}, required-interface=SendCANR_CdM_ChrgcurrentreqextVld
      SendCANR_CdMExtFunMinBattVolt: nonqueued-receiver-com-spec{data-element=SendCANR_CdMExtFunMinBattVolt, init-value=SendCANR_CdMExtFunMinBattVoltValue:0}, required-interface=SendCANR_CdMExtFunMinBattVolt
      SendCANR_CdMExtFunMinBattVoltVld: nonqueued-receiver-com-spec{data-element=SendCANR_CdMExtFunMinBattVoltVld, init-value=SendCANR_CdMExtFunMinBattVoltVldValue:1}, required-interface=SendCANR_CdMExtFunMinBattVoltVld
      SendCANR_CdMExtFunVehDynCtrlCmp: nonqueued-receiver-com-spec{data-element=SendCANR_CdMExtFunVehDynCtrlCmp, init-value=SendCANR_CdMExtFunVehDynCtrlCmpValue:0}, required-interface=SendCANR_CdMExtFunVehDynCtrlCmp
      SendCANR_CdMExtFunVehDynCtrlCmpVld: nonqueued-receiver-com-spec{data-element=SendCANR_CdMExtFunVehDynCtrlCmpVld, init-value=SendCANR_CdMExtFunVehDynCtrlCmpVldValue:1}, required-interface=SendCANR_CdMExtFunVehDynCtrlCmpVld
      SendCANR_CdM_ExtFunVehHCCntrCmp: nonqueued-receiver-com-spec{data-element=SendCANR_CdM_ExtFunVehHCCntrCmp, init-value=SendCANR_CdM_ExtFunVehHCCntrCmpValue:0}, required-interface=SendCANR_CdM_ExtFunVehHCCntrCmp
      SendCANR_CdM_ExtFunVehHCCntrCmpVld: nonqueued-receiver-com-spec{data-element=SendCANR_CdM_ExtFunVehHCCntrCmpVld, init-value=SendCANR_CdM_ExtFunVehHCCntrCmpVldValue:1}, required-interface=SendCANR_CdM_ExtFunVehHCCntrCmpVld
      SendCANR_CdM_Reminedbattcpcity: nonqueued-receiver-com-spec{data-element=SendCANR_CdM_Reminedbattcpcity, init-value=SendCANR_CdM_ReminedbattcpcityValue:0}, required-interface=SendCANR_CdM_Reminedbattcpcity
      SendCANR_CdM_ReminedbattcpcityVld: nonqueued-receiver-com-spec{data-element=SendCANR_CdM_ReminedbattcpcityVld, init-value=SendCANR_CdM_ReminedbattcpcityVldValue:1}, required-interface=SendCANR_CdM_ReminedbattcpcityVld
      SendCANR_CHAdeMOProtocol: nonqueued-receiver-com-spec{data-element=SendCANR_CHAdeMOProtocol, init-value=SendCANR_CHAdeMOProtocolValue:0}, required-interface=SendCANR_CHAdeMOProtocol
      SendCANR_CHAdeMOProtocolVld: nonqueued-receiver-com-spec{data-element=SendCANR_CHAdeMOProtocolVld, init-value=SendCANR_CHAdeMOProtocolVldValue:1}, required-interface=SendCANR_CHAdeMOProtocolVld
      SendCANR_ChargedCurrentMin: nonqueued-receiver-com-spec{data-element=SendCANR_ChargedCurrentMin, init-value=SendCANR_ChargedCurrentMinValue:0}, required-interface=SendCANR_ChargedCurrentMin
      SendCANR_ChargedCurrentMinVld: nonqueued-receiver-com-spec{data-element=SendCANR_ChargedCurrentMinVld, init-value=SendCANR_ChargedCurrentMinVldValue:1}, required-interface=SendCANR_ChargedCurrentMinVld
      SendCANR_ChrgdRefrncCnstnt: nonqueued-receiver-com-spec{data-element=SendCANR_ChrgdRefrncCnstnt, init-value=SendCANR_ChrgdRefrncCnstntValue:0}, required-interface=SendCANR_ChrgdRefrncCnstnt
      SendCANR_ChrgdRefrncCnstntVld: nonqueued-receiver-com-spec{data-element=SendCANR_ChrgdRefrncCnstntVld, init-value=SendCANR_ChrgdRefrncCnstntVldValue:1}, required-interface=SendCANR_ChrgdRefrncCnstntVld
      SendCANR_DisplaySOC: nonqueued-receiver-com-spec{data-element=SendCANR_DisplaySOC, init-value=SendCANR_DisplaySOCValue:0}, required-interface=SendCANR_DisplaySOC
      SendCANR_DisplaySOC_Vld: nonqueued-receiver-com-spec{data-element=SendCANR_DisplaySOC_Vld, init-value=SendCANR_DisplaySOC_VldValue:1}, required-interface=SendCANR_DisplaySOC_Vld
      SendCANR_EVContactorSts: nonqueued-receiver-com-spec{data-element=SendCANR_EVContactorSts, init-value=SendCANR_EVContactorStsValue:0}, required-interface=SendCANR_EVContactorSts
      SendCANR_EVContactorStsVld: nonqueued-receiver-com-spec{data-element=SendCANR_EVContactorStsVld, init-value=SendCANR_EVContactorStsVldValue:1}, required-interface=SendCANR_EVContactorStsVld
      SendCANR_EVCU_CP3Cmd: nonqueued-receiver-com-spec{data-element=SendCANR_EVCU_CP3Cmd, init-value=SendCANR_EVCU_CP3CmdValue:0}, required-interface=SendCANR_EVCU_CP3Cmd
      SendCANR_EVCU_CP3CmdVld: nonqueued-receiver-com-spec{data-element=SendCANR_EVCU_CP3CmdVld, init-value=SendCANR_EVCU_CP3CmdVldValue:1}, required-interface=SendCANR_EVCU_CP3CmdVld
      SendCANR_MinBatteryPackVoltage: nonqueued-receiver-com-spec{data-element=SendCANR_MinBatteryPackVoltage, init-value=SendCANR_MinBatteryPackVoltageValue:0}, required-interface=SendCANR_MinBatteryPackVoltage
      SendCANR_MinBatteryPackVoltageVld: nonqueued-receiver-com-spec{data-element=SendCANR_MinBatteryPackVoltageVld, init-value=SendCANR_MinBatteryPackVoltageVldValue:1}, required-interface=SendCANR_MinBatteryPackVoltageVld
      SendCANR_StopReqBeforeCharge: nonqueued-receiver-com-spec{data-element=SendCANR_StopReqBeforeCharge, init-value=SendCANR_StopReqBeforeChargeValue:0}, required-interface=SendCANR_StopReqBeforeCharge
      SendCANR_StopReqBeforeChargeVld: nonqueued-receiver-com-spec{data-element=SendCANR_StopReqBeforeChargeVld, init-value=SendCANR_StopReqBeforeChargeVldValue:1}, required-interface=SendCANR_StopReqBeforeChargeVld
      SendCANR_TotalBatteryCapacity: nonqueued-receiver-com-spec{data-element=SendCANR_TotalBatteryCapacity, init-value=SendCANR_TotalBatteryCapacityValue:0}, required-interface=SendCANR_TotalBatteryCapacity
      SendCANR_TotalBatteryCapacityVld: nonqueued-receiver-com-spec{data-element=SendCANR_TotalBatteryCapacityVld, init-value=SendCANR_TotalBatteryCapacityVldValue:1}, required-interface=SendCANR_TotalBatteryCapacityVld
      SendCANR_VehicleDriveSts: nonqueued-receiver-com-spec{data-element=SendCANR_VehicleDriveSts, init-value=SendCANR_VehicleDriveStsValue:0}, required-interface=SendCANR_VehicleDriveSts
      SendCANR_VehicleDriveStsVld: nonqueued-receiver-com-spec{data-element=SendCANR_VehicleDriveStsVld, init-value=SendCANR_VehicleDriveStsVldValue:1}, required-interface=SendCANR_VehicleDriveStsVld
      SendCANR_N_PDU_7B_FD11: nonqueued-receiver-com-spec{data-element=SendCANR_N_PDU_7B_FD11, init-value=SendCANR_N_PDU_7B_FD11Value:0}, required-interface=SendCANR_N_PDU_7B_FD11
      SendCANR_N_PDU_7B_FD11Vld: nonqueued-receiver-com-spec{data-element=SendCANR_N_PDU_7B_FD11Vld, init-value=SendCANR_N_PDU_7B_FD11VldValue:1}, required-interface=SendCANR_N_PDU_7B_FD11Vld
      SendCANR_N_PDU_7C_FD11: nonqueued-receiver-com-spec{data-element=SendCANR_N_PDU_7C_FD11, init-value=SendCANR_N_PDU_7C_FD11Value:0}, required-interface=SendCANR_N_PDU_7C_FD11
      SendCANR_N_PDU_7C_FD11Vld: nonqueued-receiver-com-spec{data-element=SendCANR_N_PDU_7C_FD11Vld, init-value=SendCANR_N_PDU_7C_FD11VldValue:1}, required-interface=SendCANR_N_PDU_7C_FD11Vld
      SendCANR_N_PDU_86: nonqueued-receiver-com-spec{data-element=SendCANR_N_PDU_86, init-value=SendCANR_N_PDU_86Value:0}, required-interface=SendCANR_N_PDU_86
      SendCANR_N_PDU_86Vld: nonqueued-receiver-com-spec{data-element=SendCANR_N_PDU_86Vld, init-value=SendCANR_N_PDU_86VldValue:1}, required-interface=SendCANR_N_PDU_86Vld
      SendCANR_N_PDU_342_FD11: nonqueued-receiver-com-spec{data-element=SendCANR_N_PDU_342_FD11, init-value=SendCANR_N_PDU_342_FD11Value:0}, required-interface=SendCANR_N_PDU_342_FD11
      SendCANR_N_PDU_342_FD11Vld: nonqueued-receiver-com-spec{data-element=SendCANR_N_PDU_342_FD11Vld, init-value=SendCANR_N_PDU_342_FD11VldValue:1}, required-interface=SendCANR_N_PDU_342_FD11Vld
      SendCANR_CRC_HYBRID_DISPLAY2: nonqueued-receiver-com-spec{data-element=SendCANR_CRC_HYBRID_DISPLAY2, init-value=SendCANR_CRC_HYBRID_DISPLAY2Value:0}, required-interface=SendCANR_CRC_HYBRID_DISPLAY2
      SendCANR_CRC_HYBRID_DISPLAY2Vld: nonqueued-receiver-com-spec{data-element=SendCANR_CRC_HYBRID_DISPLAY2Vld, init-value=SendCANR_CRC_HYBRID_DISPLAY2VldValue:1}, required-interface=SendCANR_CRC_HYBRID_DISPLAY2Vld
      SendCANR_DischrgngSysStatusFD11: nonqueued-receiver-com-spec{data-element=SendCANR_DischrgngSysStatusFD11, init-value=SendCANR_DischrgngSysStatusFD11Value:0}, required-interface=SendCANR_DischrgngSysStatusFD11
      SendCANR_DischrgngSysStatusFD11Vld: nonqueued-receiver-com-spec{data-element=SendCANR_DischrgngSysStatusFD11Vld, init-value=SendCANR_DischrgngSysStatusFD11VldValue:1}, required-interface=SendCANR_DischrgngSysStatusFD11Vld
      SendCANR_LID_Status_120VSocketA: nonqueued-receiver-com-spec{data-element=SendCANR_LID_Status_120VSocketA, init-value=SendCANR_LID_Status_120VSocketAValue:0}, required-interface=SendCANR_LID_Status_120VSocketA
      SendCANR_LID_Status_120VSocketA_Vld: nonqueued-receiver-com-spec{data-element=SendCANR_LID_Status_120VSocketA_Vld, init-value=SendCANR_LID_Status_120VSocketA_VldValue:1}, required-interface=SendCANR_LID_Status_120VSocketA_Vld
      SendCANR_LID_Status_120VSocketB: nonqueued-receiver-com-spec{data-element=SendCANR_LID_Status_120VSocketB, init-value=SendCANR_LID_Status_120VSocketBValue:0}, required-interface=SendCANR_LID_Status_120VSocketB
      SendCANR_LID_Status_120VSocketB_Vld: nonqueued-receiver-com-spec{data-element=SendCANR_LID_Status_120VSocketB_Vld, init-value=SendCANR_LID_Status_120VSocketB_VldValue:1}, required-interface=SendCANR_LID_Status_120VSocketB_Vld
      SendCANR_LID_Status_240V_Socket: nonqueued-receiver-com-spec{data-element=SendCANR_LID_Status_240V_Socket, init-value=SendCANR_LID_Status_240V_SocketValue:0}, required-interface=SendCANR_LID_Status_240V_Socket
      SendCANR_LID_Status_240V_SocketVld: nonqueued-receiver-com-spec{data-element=SendCANR_LID_Status_240V_SocketVld, init-value=SendCANR_LID_Status_240V_SocketVldValue:1}, required-interface=SendCANR_LID_Status_240V_SocketVld
      SendCANR_Max_AllwdACOutputCurL1: nonqueued-receiver-com-spec{data-element=SendCANR_Max_AllwdACOutputCurL1, init-value=SendCANR_Max_AllwdACOutputCurL1Value:0}, required-interface=SendCANR_Max_AllwdACOutputCurL1
      SendCANR_Max_AllwdACOutputCurL1Vld: nonqueued-receiver-com-spec{data-element=SendCANR_Max_AllwdACOutputCurL1Vld, init-value=SendCANR_Max_AllwdACOutputCurL1VldValue:1}, required-interface=SendCANR_Max_AllwdACOutputCurL1Vld
      SendCANR_Max_AllwdACOutputVltL1: nonqueued-receiver-com-spec{data-element=SendCANR_Max_AllwdACOutputVltL1, init-value=SendCANR_Max_AllwdACOutputVltL1Value:0}, required-interface=SendCANR_Max_AllwdACOutputVltL1
      SendCANR_Max_AllwdACOutputVltL1Vld: nonqueued-receiver-com-spec{data-element=SendCANR_Max_AllwdACOutputVltL1Vld, init-value=SendCANR_Max_AllwdACOutputVltL1VldValue:1}, required-interface=SendCANR_Max_AllwdACOutputVltL1Vld
      SendCANR_MC_HYBRID_DISPLAY2: nonqueued-receiver-com-spec{data-element=SendCANR_MC_HYBRID_DISPLAY2, init-value=SendCANR_MC_HYBRID_DISPLAY2Value:0}, required-interface=SendCANR_MC_HYBRID_DISPLAY2
      SendCANR_MC_HYBRID_DISPLAY2Vld: nonqueued-receiver-com-spec{data-element=SendCANR_MC_HYBRID_DISPLAY2Vld, init-value=SendCANR_MC_HYBRID_DISPLAY2VldValue:1}, required-interface=SendCANR_MC_HYBRID_DISPLAY2Vld
      SendCANR_CRC_HYBRID_SYSTEM_EPT1: nonqueued-receiver-com-spec{data-element=SendCANR_CRC_HYBRID_SYSTEM_EPT1, init-value=SendCANR_CRC_HYBRID_SYSTEM_EPT1Value:0}, required-interface=SendCANR_CRC_HYBRID_SYSTEM_EPT1
      SendCANR_CRC_HYBRID_SYSTEM_EPT1Vld: nonqueued-receiver-com-spec{data-element=SendCANR_CRC_HYBRID_SYSTEM_EPT1Vld, init-value=SendCANR_CRC_HYBRID_SYSTEM_EPT1VldValue:1}, required-interface=SendCANR_CRC_HYBRID_SYSTEM_EPT1Vld
      SendCANR_HCP_ShutdownCommand: nonqueued-receiver-com-spec{data-element=SendCANR_HCP_ShutdownCommand, init-value=SendCANR_HCP_ShutdownCommandValue:0}, required-interface=SendCANR_HCP_ShutdownCommand
      SendCANR_HCP_ShutdownCommandVld: nonqueued-receiver-com-spec{data-element=SendCANR_HCP_ShutdownCommandVld, init-value=SendCANR_HCP_ShutdownCommandVldValue:1}, required-interface=SendCANR_HCP_ShutdownCommandVld
      SendCANR_HybridDriveModeSts: nonqueued-receiver-com-spec{data-element=SendCANR_HybridDriveModeSts, init-value=SendCANR_HybridDriveModeStsValue:0}, required-interface=SendCANR_HybridDriveModeSts
      SendCANR_HybridDriveModeStsVld: nonqueued-receiver-com-spec{data-element=SendCANR_HybridDriveModeStsVld, init-value=SendCANR_HybridDriveModeStsVldValue:1}, required-interface=SendCANR_HybridDriveModeStsVld
      SendCANR_LOC_DiagEnable_ePT: nonqueued-receiver-com-spec{data-element=SendCANR_LOC_DiagEnable_ePT, init-value=SendCANR_LOC_DiagEnable_ePTValue:0}, required-interface=SendCANR_LOC_DiagEnable_ePT
      SendCANR_LOC_DiagEnable_ePT_Vld: nonqueued-receiver-com-spec{data-element=SendCANR_LOC_DiagEnable_ePT_Vld, init-value=SendCANR_LOC_DiagEnable_ePT_VldValue:1}, required-interface=SendCANR_LOC_DiagEnable_ePT_Vld
      SendCANR_MsgCtrHYB_SYSTEM_EPT1: nonqueued-receiver-com-spec{data-element=SendCANR_MsgCtrHYB_SYSTEM_EPT1, init-value=SendCANR_MsgCtrHYB_SYSTEM_EPT1Value:0}, required-interface=SendCANR_MsgCtrHYB_SYSTEM_EPT1
      SendCANR_MsgCtrHYB_SYSTEM_EPT1Vld: nonqueued-receiver-com-spec{data-element=SendCANR_MsgCtrHYB_SYSTEM_EPT1Vld, init-value=SendCANR_MsgCtrHYB_SYSTEM_EPT1VldValue:1}, required-interface=SendCANR_MsgCtrHYB_SYSTEM_EPT1Vld
      SendCANR_PerWakeUp_Diag_FD11: nonqueued-receiver-com-spec{data-element=SendCANR_PerWakeUp_Diag_FD11, init-value=SendCANR_PerWakeUp_Diag_FD11Value:0}, required-interface=SendCANR_PerWakeUp_Diag_FD11
      SendCANR_PerWakeUp_Diag_FD11Vld: nonqueued-receiver-com-spec{data-element=SendCANR_PerWakeUp_Diag_FD11Vld, init-value=SendCANR_PerWakeUp_Diag_FD11VldValue:1}, required-interface=SendCANR_PerWakeUp_Diag_FD11Vld
      SendCANR_PrplsnSysActive_10B: nonqueued-receiver-com-spec{data-element=SendCANR_PrplsnSysActive_10B, init-value=SendCANR_PrplsnSysActive_10BValue:0}, required-interface=SendCANR_PrplsnSysActive_10B
      SendCANR_PrplsnSysActive_10B_Vld: nonqueued-receiver-com-spec{data-element=SendCANR_PrplsnSysActive_10B_Vld, init-value=SendCANR_PrplsnSysActive_10B_VldValue:1}, required-interface=SendCANR_PrplsnSysActive_10B_Vld
      SendCANR_WU_Timer_Value_FD11: nonqueued-receiver-com-spec{data-element=SendCANR_WU_Timer_Value_FD11, init-value=SendCANR_WU_Timer_Value_FD11Value:0}, required-interface=SendCANR_WU_Timer_Value_FD11
      SendCANR_WU_Timer_Value_FD11Vld: nonqueued-receiver-com-spec{data-element=SendCANR_WU_Timer_Value_FD11Vld, init-value=SendCANR_WU_Timer_Value_FD11VldValue:1}, required-interface=SendCANR_WU_Timer_Value_FD11Vld
      SendCANR_IMPACTCommand_FD11: nonqueued-receiver-com-spec{data-element=SendCANR_IMPACTCommand_FD11, init-value=SendCANR_IMPACTCommand_FD11Value:0}, required-interface=SendCANR_IMPACTCommand_FD11
      SendCANR_IMPACTCommand_FD11Vld: nonqueued-receiver-com-spec{data-element=SendCANR_IMPACTCommand_FD11Vld, init-value=SendCANR_IMPACTCommand_FD11VldValue:1}, required-interface=SendCANR_IMPACTCommand_FD11Vld
      SendCANR_IMPACTConfirm_FD11: nonqueued-receiver-com-spec{data-element=SendCANR_IMPACTConfirm_FD11, init-value=SendCANR_IMPACTConfirm_FD11Value:1}, required-interface=SendCANR_IMPACTConfirm_FD11
      SendCANR_IMPACTConfirm_FD11Vld: nonqueued-receiver-com-spec{data-element=SendCANR_IMPACTConfirm_FD11Vld, init-value=SendCANR_IMPACTConfirm_FD11VldValue:1}, required-interface=SendCANR_IMPACTConfirm_FD11Vld
      SendCANR_TotalOdometer_FD11: nonqueued-receiver-com-spec{data-element=SendCANR_TotalOdometer_FD11, init-value=SendCANR_TotalOdometer_FD11Value:0}, required-interface=SendCANR_TotalOdometer_FD11
      SendCANR_TotalOdometer_FD11Vld: nonqueued-receiver-com-spec{data-element=SendCANR_TotalOdometer_FD11Vld, init-value=SendCANR_TotalOdometer_FD11VldValue:1}, required-interface=SendCANR_TotalOdometer_FD11Vld
      SendCANR_MCPA_Temp_FD11: nonqueued-receiver-com-spec{data-element=SendCANR_MCPA_Temp_FD11, init-value=SendCANR_MCPA_Temp_FD11Value:0}, required-interface=SendCANR_MCPA_Temp_FD11
      SendCANR_MCPA_Temp_FD11Vld: nonqueued-receiver-com-spec{data-element=SendCANR_MCPA_Temp_FD11Vld, init-value=SendCANR_MCPA_Temp_FD11VldValue:1}, required-interface=SendCANR_MCPA_Temp_FD11Vld
      SendCANR_CRC_MCPA_STATUS_FD11: nonqueued-receiver-com-spec{data-element=SendCANR_CRC_MCPA_STATUS_FD11, init-value=SendCANR_CRC_MCPA_STATUS_FD11Value:0}, required-interface=SendCANR_CRC_MCPA_STATUS_FD11
      SendCANR_CRC_MCPA_STATUS_FD11Vld: nonqueued-receiver-com-spec{data-element=SendCANR_CRC_MCPA_STATUS_FD11Vld, init-value=SendCANR_CRC_MCPA_STATUS_FD11VldValue:1}, required-interface=SendCANR_CRC_MCPA_STATUS_FD11Vld
      SendCANR_MC_MCPA_STATUS_FD11: nonqueued-receiver-com-spec{data-element=SendCANR_MC_MCPA_STATUS_FD11, init-value=SendCANR_MC_MCPA_STATUS_FD11Value:0}, required-interface=SendCANR_MC_MCPA_STATUS_FD11
      SendCANR_MC_MCPA_STATUS_FD11Vld: nonqueued-receiver-com-spec{data-element=SendCANR_MC_MCPA_STATUS_FD11Vld, init-value=SendCANR_MC_MCPA_STATUS_FD11VldValue:1}, required-interface=SendCANR_MC_MCPA_STATUS_FD11Vld
      SendCANR_MCPA_DC_Current_P_FD11: nonqueued-receiver-com-spec{data-element=SendCANR_MCPA_DC_Current_P_FD11, init-value=SendCANR_MCPA_DC_Current_P_FD11Value:0}, required-interface=SendCANR_MCPA_DC_Current_P_FD11
      SendCANR_MCPA_DC_Current_P_FD11Vld: nonqueued-receiver-com-spec{data-element=SendCANR_MCPA_DC_Current_P_FD11Vld, init-value=SendCANR_MCPA_DC_Current_P_FD11VldValue:1}, required-interface=SendCANR_MCPA_DC_Current_P_FD11Vld
      SendCANR_MCPB_Temp_FD11: nonqueued-receiver-com-spec{data-element=SendCANR_MCPB_Temp_FD11, init-value=SendCANR_MCPB_Temp_FD11Value:0}, required-interface=SendCANR_MCPB_Temp_FD11
      SendCANR_MCPB_Temp_FD11Vld: nonqueued-receiver-com-spec{data-element=SendCANR_MCPB_Temp_FD11Vld, init-value=SendCANR_MCPB_Temp_FD11VldValue:1}, required-interface=SendCANR_MCPB_Temp_FD11Vld
      SendCANR_CRC_MCPB_STATUS_FD11: nonqueued-receiver-com-spec{data-element=SendCANR_CRC_MCPB_STATUS_FD11, init-value=SendCANR_CRC_MCPB_STATUS_FD11Value:0}, required-interface=SendCANR_CRC_MCPB_STATUS_FD11
      SendCANR_CRC_MCPB_STATUS_FD11Vld: nonqueued-receiver-com-spec{data-element=SendCANR_CRC_MCPB_STATUS_FD11Vld, init-value=SendCANR_CRC_MCPB_STATUS_FD11VldValue:1}, required-interface=SendCANR_CRC_MCPB_STATUS_FD11Vld
      SendCANR_MC_MCPB_STATUS_FD11: nonqueued-receiver-com-spec{data-element=SendCANR_MC_MCPB_STATUS_FD11, init-value=SendCANR_MC_MCPB_STATUS_FD11Value:0}, required-interface=SendCANR_MC_MCPB_STATUS_FD11
      SendCANR_MC_MCPB_STATUS_FD11Vld: nonqueued-receiver-com-spec{data-element=SendCANR_MC_MCPB_STATUS_FD11Vld, init-value=SendCANR_MC_MCPB_STATUS_FD11VldValue:1}, required-interface=SendCANR_MC_MCPB_STATUS_FD11Vld
      SendCANR_MCPB_DC_Current_P_FD11: nonqueued-receiver-com-spec{data-element=SendCANR_MCPB_DC_Current_P_FD11, init-value=SendCANR_MCPB_DC_Current_P_FD11Value:0}, required-interface=SendCANR_MCPB_DC_Current_P_FD11
      SendCANR_MCPB_DC_Current_P_FD11Vld: nonqueued-receiver-com-spec{data-element=SendCANR_MCPB_DC_Current_P_FD11Vld, init-value=SendCANR_MCPB_DC_Current_P_FD11VldValue:1}, required-interface=SendCANR_MCPB_DC_Current_P_FD11Vld
      SendCANR_CrCanNMStFD03EVCU2FD11: nonqueued-receiver-com-spec{data-element=SendCANR_CrCanNMStFD03EVCU2FD11, init-value=SendCANR_CrCanNMStFD03EVCU2FD11Value:0}, required-interface=SendCANR_CrCanNMStFD03EVCU2FD11
      SendCANR_CrCanNMStFD03EVCU2FD11Vld: nonqueued-receiver-com-spec{data-element=SendCANR_CrCanNMStFD03EVCU2FD11Vld, init-value=SendCANR_CrCanNMStFD03EVCU2FD11VldValue:1}, required-interface=SendCANR_CrCanNMStFD03EVCU2FD11Vld
      SendCANR_CrCanNMStFD05EVCU2FD11: nonqueued-receiver-com-spec{data-element=SendCANR_CrCanNMStFD05EVCU2FD11, init-value=SendCANR_CrCanNMStFD05EVCU2FD11Value:0}, required-interface=SendCANR_CrCanNMStFD05EVCU2FD11
      SendCANR_CrCanNMStFD05EVCU2FD11Vld: nonqueued-receiver-com-spec{data-element=SendCANR_CrCanNMStFD05EVCU2FD11Vld, init-value=SendCANR_CrCanNMStFD05EVCU2FD11VldValue:1}, required-interface=SendCANR_CrCanNMStFD05EVCU2FD11Vld
      SendCANR_CrCanNMStFD11EVCU2FD11: nonqueued-receiver-com-spec{data-element=SendCANR_CrCanNMStFD11EVCU2FD11, init-value=SendCANR_CrCanNMStFD11EVCU2FD11Value:0}, required-interface=SendCANR_CrCanNMStFD11EVCU2FD11
      SendCANR_CrCanNMStFD11EVCU2FD11Vld: nonqueued-receiver-com-spec{data-element=SendCANR_CrCanNMStFD11EVCU2FD11Vld, init-value=SendCANR_CrCanNMStFD11EVCU2FD11VldValue:1}, required-interface=SendCANR_CrCanNMStFD11EVCU2FD11Vld
      SendCANR_CrCanNMStFD16EVCU2FD11: nonqueued-receiver-com-spec{data-element=SendCANR_CrCanNMStFD16EVCU2FD11, init-value=SendCANR_CrCanNMStFD16EVCU2FD11Value:0}, required-interface=SendCANR_CrCanNMStFD16EVCU2FD11
      SendCANR_CrCanNMStFD16EVCU2FD11Vld: nonqueued-receiver-com-spec{data-element=SendCANR_CrCanNMStFD16EVCU2FD11Vld, init-value=SendCANR_CrCanNMStFD16EVCU2FD11VldValue:1}, required-interface=SendCANR_CrCanNMStFD16EVCU2FD11Vld
      SendCANR_CurFailStFD03EVCU2FD11: nonqueued-receiver-com-spec{data-element=SendCANR_CurFailStFD03EVCU2FD11, init-value=SendCANR_CurFailStFD03EVCU2FD11Value:0}, required-interface=SendCANR_CurFailStFD03EVCU2FD11
      SendCANR_CurFailStFD03EVCU2FD11Vld: nonqueued-receiver-com-spec{data-element=SendCANR_CurFailStFD03EVCU2FD11Vld, init-value=SendCANR_CurFailStFD03EVCU2FD11VldValue:1}, required-interface=SendCANR_CurFailStFD03EVCU2FD11Vld
      SendCANR_CurFailStFD05EVCU2FD11: nonqueued-receiver-com-spec{data-element=SendCANR_CurFailStFD05EVCU2FD11, init-value=SendCANR_CurFailStFD05EVCU2FD11Value:0}, required-interface=SendCANR_CurFailStFD05EVCU2FD11
      SendCANR_CurFailStFD05EVCU2FD11Vld: nonqueued-receiver-com-spec{data-element=SendCANR_CurFailStFD05EVCU2FD11Vld, init-value=SendCANR_CurFailStFD05EVCU2FD11VldValue:1}, required-interface=SendCANR_CurFailStFD05EVCU2FD11Vld
      SendCANR_CurFailStFD11EVCU2FD11: nonqueued-receiver-com-spec{data-element=SendCANR_CurFailStFD11EVCU2FD11, init-value=SendCANR_CurFailStFD11EVCU2FD11Value:0}, required-interface=SendCANR_CurFailStFD11EVCU2FD11
      SendCANR_CurFailStFD11EVCU2FD11Vld: nonqueued-receiver-com-spec{data-element=SendCANR_CurFailStFD11EVCU2FD11Vld, init-value=SendCANR_CurFailStFD11EVCU2FD11VldValue:1}, required-interface=SendCANR_CurFailStFD11EVCU2FD11Vld
      SendCANR_CurFailStFD16EVCU2FD11: nonqueued-receiver-com-spec{data-element=SendCANR_CurFailStFD16EVCU2FD11, init-value=SendCANR_CurFailStFD16EVCU2FD11Value:0}, required-interface=SendCANR_CurFailStFD16EVCU2FD11
      SendCANR_CurFailStFD16EVCU2FD11Vld: nonqueued-receiver-com-spec{data-element=SendCANR_CurFailStFD16EVCU2FD11Vld, init-value=SendCANR_CurFailStFD16EVCU2FD11VldValue:1}, required-interface=SendCANR_CurFailStFD16EVCU2FD11Vld
      SendCANR_DES_FD03_EVCU2_FD11: nonqueued-receiver-com-spec{data-element=SendCANR_DES_FD03_EVCU2_FD11, init-value=SendCANR_DES_FD03_EVCU2_FD11Value:0}, required-interface=SendCANR_DES_FD03_EVCU2_FD11
      SendCANR_DES_FD03_EVCU2_FD11Vld: nonqueued-receiver-com-spec{data-element=SendCANR_DES_FD03_EVCU2_FD11Vld, init-value=SendCANR_DES_FD03_EVCU2_FD11VldValue:1}, required-interface=SendCANR_DES_FD03_EVCU2_FD11Vld
      SendCANR_DES_FD05_EVCU2_FD11: nonqueued-receiver-com-spec{data-element=SendCANR_DES_FD05_EVCU2_FD11, init-value=SendCANR_DES_FD05_EVCU2_FD11Value:0}, required-interface=SendCANR_DES_FD05_EVCU2_FD11
      SendCANR_DES_FD05_EVCU2_FD11Vld: nonqueued-receiver-com-spec{data-element=SendCANR_DES_FD05_EVCU2_FD11Vld, init-value=SendCANR_DES_FD05_EVCU2_FD11VldValue:1}, required-interface=SendCANR_DES_FD05_EVCU2_FD11Vld
      SendCANR_DES_FD11_EVCU2_FD11: nonqueued-receiver-com-spec{data-element=SendCANR_DES_FD11_EVCU2_FD11, init-value=SendCANR_DES_FD11_EVCU2_FD11Value:0}, required-interface=SendCANR_DES_FD11_EVCU2_FD11
      SendCANR_DES_FD11_EVCU2_FD11Vld: nonqueued-receiver-com-spec{data-element=SendCANR_DES_FD11_EVCU2_FD11Vld, init-value=SendCANR_DES_FD11_EVCU2_FD11VldValue:1}, required-interface=SendCANR_DES_FD11_EVCU2_FD11Vld
      SendCANR_DES_FD16_EVCU2_FD11: nonqueued-receiver-com-spec{data-element=SendCANR_DES_FD16_EVCU2_FD11, init-value=SendCANR_DES_FD16_EVCU2_FD11Value:0}, required-interface=SendCANR_DES_FD16_EVCU2_FD11
      SendCANR_DES_FD16_EVCU2_FD11Vld: nonqueued-receiver-com-spec{data-element=SendCANR_DES_FD16_EVCU2_FD11Vld, init-value=SendCANR_DES_FD16_EVCU2_FD11VldValue:1}, required-interface=SendCANR_DES_FD16_EVCU2_FD11Vld
      SendCANR_EOL_FD03_EVCU2_FD11: nonqueued-receiver-com-spec{data-element=SendCANR_EOL_FD03_EVCU2_FD11, init-value=SendCANR_EOL_FD03_EVCU2_FD11Value:0}, required-interface=SendCANR_EOL_FD03_EVCU2_FD11
      SendCANR_EOL_FD03_EVCU2_FD11Vld: nonqueued-receiver-com-spec{data-element=SendCANR_EOL_FD03_EVCU2_FD11Vld, init-value=SendCANR_EOL_FD03_EVCU2_FD11VldValue:1}, required-interface=SendCANR_EOL_FD03_EVCU2_FD11Vld
      SendCANR_EOL_FD05_EVCU2_FD11: nonqueued-receiver-com-spec{data-element=SendCANR_EOL_FD05_EVCU2_FD11, init-value=SendCANR_EOL_FD05_EVCU2_FD11Value:0}, required-interface=SendCANR_EOL_FD05_EVCU2_FD11
      SendCANR_EOL_FD05_EVCU2_FD11Vld: nonqueued-receiver-com-spec{data-element=SendCANR_EOL_FD05_EVCU2_FD11Vld, init-value=SendCANR_EOL_FD05_EVCU2_FD11VldValue:1}, required-interface=SendCANR_EOL_FD05_EVCU2_FD11Vld
      SendCANR_EOL_FD11_EVCU2_FD11: nonqueued-receiver-com-spec{data-element=SendCANR_EOL_FD11_EVCU2_FD11, init-value=SendCANR_EOL_FD11_EVCU2_FD11Value:0}, required-interface=SendCANR_EOL_FD11_EVCU2_FD11
      SendCANR_EOL_FD11_EVCU2_FD11Vld: nonqueued-receiver-com-spec{data-element=SendCANR_EOL_FD11_EVCU2_FD11Vld, init-value=SendCANR_EOL_FD11_EVCU2_FD11VldValue:1}, required-interface=SendCANR_EOL_FD11_EVCU2_FD11Vld
      SendCANR_EOL_FD16_EVCU2_FD11: nonqueued-receiver-com-spec{data-element=SendCANR_EOL_FD16_EVCU2_FD11, init-value=SendCANR_EOL_FD16_EVCU2_FD11Value:0}, required-interface=SendCANR_EOL_FD16_EVCU2_FD11
      SendCANR_EOL_FD16_EVCU2_FD11Vld: nonqueued-receiver-com-spec{data-element=SendCANR_EOL_FD16_EVCU2_FD11Vld, init-value=SendCANR_EOL_FD16_EVCU2_FD11VldValue:1}, required-interface=SendCANR_EOL_FD16_EVCU2_FD11Vld
      SendCANR_GenFailStFD03EVCU2FD11: nonqueued-receiver-com-spec{data-element=SendCANR_GenFailStFD03EVCU2FD11, init-value=SendCANR_GenFailStFD03EVCU2FD11Value:0}, required-interface=SendCANR_GenFailStFD03EVCU2FD11
      SendCANR_GenFailStFD03EVCU2FD11Vld: nonqueued-receiver-com-spec{data-element=SendCANR_GenFailStFD03EVCU2FD11Vld, init-value=SendCANR_GenFailStFD03EVCU2FD11VldValue:1}, required-interface=SendCANR_GenFailStFD03EVCU2FD11Vld
      SendCANR_GenFailStFD05EVCU2FD11: nonqueued-receiver-com-spec{data-element=SendCANR_GenFailStFD05EVCU2FD11, init-value=SendCANR_GenFailStFD05EVCU2FD11Value:0}, required-interface=SendCANR_GenFailStFD05EVCU2FD11
      SendCANR_GenFailStFD05EVCU2FD11Vld: nonqueued-receiver-com-spec{data-element=SendCANR_GenFailStFD05EVCU2FD11Vld, init-value=SendCANR_GenFailStFD05EVCU2FD11VldValue:1}, required-interface=SendCANR_GenFailStFD05EVCU2FD11Vld
      SendCANR_GenFailStFD11EVCU2FD11: nonqueued-receiver-com-spec{data-element=SendCANR_GenFailStFD11EVCU2FD11, init-value=SendCANR_GenFailStFD11EVCU2FD11Value:0}, required-interface=SendCANR_GenFailStFD11EVCU2FD11
      SendCANR_GenFailStFD11EVCU2FD11Vld: nonqueued-receiver-com-spec{data-element=SendCANR_GenFailStFD11EVCU2FD11Vld, init-value=SendCANR_GenFailStFD11EVCU2FD11VldValue:1}, required-interface=SendCANR_GenFailStFD11EVCU2FD11Vld
      SendCANR_GenFailStFD16EVCU2FD11: nonqueued-receiver-com-spec{data-element=SendCANR_GenFailStFD16EVCU2FD11, init-value=SendCANR_GenFailStFD16EVCU2FD11Value:0}, required-interface=SendCANR_GenFailStFD16EVCU2FD11
      SendCANR_GenFailStFD16EVCU2FD11Vld: nonqueued-receiver-com-spec{data-element=SendCANR_GenFailStFD16EVCU2FD11Vld, init-value=SendCANR_GenFailStFD16EVCU2FD11VldValue:1}, required-interface=SendCANR_GenFailStFD16EVCU2FD11Vld
      SendCANR_PvCanNMStFD03EVCU2FD11: nonqueued-receiver-com-spec{data-element=SendCANR_PvCanNMStFD03EVCU2FD11, init-value=SendCANR_PvCanNMStFD03EVCU2FD11Value:0}, required-interface=SendCANR_PvCanNMStFD03EVCU2FD11
      SendCANR_PvCanNMStFD03EVCU2FD11Vld: nonqueued-receiver-com-spec{data-element=SendCANR_PvCanNMStFD03EVCU2FD11Vld, init-value=SendCANR_PvCanNMStFD03EVCU2FD11VldValue:1}, required-interface=SendCANR_PvCanNMStFD03EVCU2FD11Vld
      SendCANR_PvCanNMStFD05EVCU2FD11: nonqueued-receiver-com-spec{data-element=SendCANR_PvCanNMStFD05EVCU2FD11, init-value=SendCANR_PvCanNMStFD05EVCU2FD11Value:0}, required-interface=SendCANR_PvCanNMStFD05EVCU2FD11
      SendCANR_PvCanNMStFD05EVCU2FD11Vld: nonqueued-receiver-com-spec{data-element=SendCANR_PvCanNMStFD05EVCU2FD11Vld, init-value=SendCANR_PvCanNMStFD05EVCU2FD11VldValue:1}, required-interface=SendCANR_PvCanNMStFD05EVCU2FD11Vld
      SendCANR_PvCanNMStFD11EVCU2FD11: nonqueued-receiver-com-spec{data-element=SendCANR_PvCanNMStFD11EVCU2FD11, init-value=SendCANR_PvCanNMStFD11EVCU2FD11Value:0}, required-interface=SendCANR_PvCanNMStFD11EVCU2FD11
      SendCANR_PvCanNMStFD11EVCU2FD11Vld: nonqueued-receiver-com-spec{data-element=SendCANR_PvCanNMStFD11EVCU2FD11Vld, init-value=SendCANR_PvCanNMStFD11EVCU2FD11VldValue:1}, required-interface=SendCANR_PvCanNMStFD11EVCU2FD11Vld
      SendCANR_PvCanNMStFD16EVCU2FD11: nonqueued-receiver-com-spec{data-element=SendCANR_PvCanNMStFD16EVCU2FD11, init-value=SendCANR_PvCanNMStFD16EVCU2FD11Value:0}, required-interface=SendCANR_PvCanNMStFD16EVCU2FD11
      SendCANR_PvCanNMStFD16EVCU2FD11Vld: nonqueued-receiver-com-spec{data-element=SendCANR_PvCanNMStFD16EVCU2FD11Vld, init-value=SendCANR_PvCanNMStFD16EVCU2FD11VldValue:1}, required-interface=SendCANR_PvCanNMStFD16EVCU2FD11Vld
      SendCANR_StyActSrcFD03EVCU2FD11: nonqueued-receiver-com-spec{data-element=SendCANR_StyActSrcFD03EVCU2FD11, init-value=SendCANR_StyActSrcFD03EVCU2FD11Value:0}, required-interface=SendCANR_StyActSrcFD03EVCU2FD11
      SendCANR_StyActSrcFD03EVCU2FD11Vld: nonqueued-receiver-com-spec{data-element=SendCANR_StyActSrcFD03EVCU2FD11Vld, init-value=SendCANR_StyActSrcFD03EVCU2FD11VldValue:1}, required-interface=SendCANR_StyActSrcFD03EVCU2FD11Vld
      SendCANR_StyActSrcFD05EVCU2FD11: nonqueued-receiver-com-spec{data-element=SendCANR_StyActSrcFD05EVCU2FD11, init-value=SendCANR_StyActSrcFD05EVCU2FD11Value:0}, required-interface=SendCANR_StyActSrcFD05EVCU2FD11
      SendCANR_StyActSrcFD05EVCU2FD11Vld: nonqueued-receiver-com-spec{data-element=SendCANR_StyActSrcFD05EVCU2FD11Vld, init-value=SendCANR_StyActSrcFD05EVCU2FD11VldValue:1}, required-interface=SendCANR_StyActSrcFD05EVCU2FD11Vld
      SendCANR_StyActSrcFD11EVCU2FD11: nonqueued-receiver-com-spec{data-element=SendCANR_StyActSrcFD11EVCU2FD11, init-value=SendCANR_StyActSrcFD11EVCU2FD11Value:0}, required-interface=SendCANR_StyActSrcFD11EVCU2FD11
      SendCANR_StyActSrcFD11EVCU2FD11Vld: nonqueued-receiver-com-spec{data-element=SendCANR_StyActSrcFD11EVCU2FD11Vld, init-value=SendCANR_StyActSrcFD11EVCU2FD11VldValue:1}, required-interface=SendCANR_StyActSrcFD11EVCU2FD11Vld
      SendCANR_StyActSrcFD16EVCU2FD11: nonqueued-receiver-com-spec{data-element=SendCANR_StyActSrcFD16EVCU2FD11, init-value=SendCANR_StyActSrcFD16EVCU2FD11Value:0}, required-interface=SendCANR_StyActSrcFD16EVCU2FD11
      SendCANR_StyActSrcFD16EVCU2FD11Vld: nonqueued-receiver-com-spec{data-element=SendCANR_StyActSrcFD16EVCU2FD11Vld, init-value=SendCANR_StyActSrcFD16EVCU2FD11VldValue:1}, required-interface=SendCANR_StyActSrcFD16EVCU2FD11Vld
      SendCANR_WkeupSrcFD03_EVCU2FD11: nonqueued-receiver-com-spec{data-element=SendCANR_WkeupSrcFD03_EVCU2FD11, init-value=SendCANR_WkeupSrcFD03_EVCU2FD11Value:0}, required-interface=SendCANR_WkeupSrcFD03_EVCU2FD11
      SendCANR_WkeupSrcFD03_EVCU2FD11Vld: nonqueued-receiver-com-spec{data-element=SendCANR_WkeupSrcFD03_EVCU2FD11Vld, init-value=SendCANR_WkeupSrcFD03_EVCU2FD11VldValue:1}, required-interface=SendCANR_WkeupSrcFD03_EVCU2FD11Vld
      SendCANR_WkeupSrcFD05_EVCU2FD11: nonqueued-receiver-com-spec{data-element=SendCANR_WkeupSrcFD05_EVCU2FD11, init-value=SendCANR_WkeupSrcFD05_EVCU2FD11Value:0}, required-interface=SendCANR_WkeupSrcFD05_EVCU2FD11
      SendCANR_WkeupSrcFD05_EVCU2FD11Vld: nonqueued-receiver-com-spec{data-element=SendCANR_WkeupSrcFD05_EVCU2FD11Vld, init-value=SendCANR_WkeupSrcFD05_EVCU2FD11VldValue:1}, required-interface=SendCANR_WkeupSrcFD05_EVCU2FD11Vld
      SendCANR_WkeupSrcFD11_EVCU2FD11: nonqueued-receiver-com-spec{data-element=SendCANR_WkeupSrcFD11_EVCU2FD11, init-value=SendCANR_WkeupSrcFD11_EVCU2FD11Value:0}, required-interface=SendCANR_WkeupSrcFD11_EVCU2FD11
      SendCANR_WkeupSrcFD11_EVCU2FD11Vld: nonqueued-receiver-com-spec{data-element=SendCANR_WkeupSrcFD11_EVCU2FD11Vld, init-value=SendCANR_WkeupSrcFD11_EVCU2FD11VldValue:1}, required-interface=SendCANR_WkeupSrcFD11_EVCU2FD11Vld
      SendCANR_WkeupSrcFD16_EVCU2FD11: nonqueued-receiver-com-spec{data-element=SendCANR_WkeupSrcFD16_EVCU2FD11, init-value=SendCANR_WkeupSrcFD16_EVCU2FD11Value:0}, required-interface=SendCANR_WkeupSrcFD16_EVCU2FD11
      SendCANR_WkeupSrcFD16_EVCU2FD11Vld: nonqueued-receiver-com-spec{data-element=SendCANR_WkeupSrcFD16_EVCU2FD11Vld, init-value=SendCANR_WkeupSrcFD16_EVCU2FD11VldValue:1}, required-interface=SendCANR_WkeupSrcFD16_EVCU2FD11Vld
      SendCANR_DriveReady_PT_FD11: nonqueued-receiver-com-spec{data-element=SendCANR_DriveReady_PT_FD11, init-value=SendCANR_DriveReady_PT_FD11Value:0}, required-interface=SendCANR_DriveReady_PT_FD11
      SendCANR_DriveReady_PT_FD11Vld: nonqueued-receiver-com-spec{data-element=SendCANR_DriveReady_PT_FD11Vld, init-value=SendCANR_DriveReady_PT_FD11VldValue:1}, required-interface=SendCANR_DriveReady_PT_FD11Vld
      SendCANR_GearEngaged_PT_FD11: nonqueued-receiver-com-spec{data-element=SendCANR_GearEngaged_PT_FD11, init-value=SendCANR_GearEngaged_PT_FD11Value:0}, required-interface=SendCANR_GearEngaged_PT_FD11
      SendCANR_GearEngaged_PT_FD11Vld: nonqueued-receiver-com-spec{data-element=SendCANR_GearEngaged_PT_FD11Vld, init-value=SendCANR_GearEngaged_PT_FD11VldValue:1}, required-interface=SendCANR_GearEngaged_PT_FD11Vld
      SendCANR_GearEngdForDispPTFD11: nonqueued-receiver-com-spec{data-element=SendCANR_GearEngdForDispPTFD11, init-value=SendCANR_GearEngdForDispPTFD11Value:0}, required-interface=SendCANR_GearEngdForDispPTFD11
      SendCANR_GearEngdForDispPTFD11Vld: nonqueued-receiver-com-spec{data-element=SendCANR_GearEngdForDispPTFD11Vld, init-value=SendCANR_GearEngdForDispPTFD11VldValue:1}, required-interface=SendCANR_GearEngdForDispPTFD11Vld
      SendCANR_PtrainPrplsnActvPTFD11: nonqueued-receiver-com-spec{data-element=SendCANR_PtrainPrplsnActvPTFD11, init-value=SendCANR_PtrainPrplsnActvPTFD11Value:0}, required-interface=SendCANR_PtrainPrplsnActvPTFD11
      SendCANR_PtrainPrplsnActvPTFD11Vld: nonqueued-receiver-com-spec{data-element=SendCANR_PtrainPrplsnActvPTFD11Vld, init-value=SendCANR_PtrainPrplsnActvPTFD11VldValue:1}, required-interface=SendCANR_PtrainPrplsnActvPTFD11Vld
      SendCANR_SGCP_Temp_FD11: nonqueued-receiver-com-spec{data-element=SendCANR_SGCP_Temp_FD11, init-value=SendCANR_SGCP_Temp_FD11Value:-40}, required-interface=SendCANR_SGCP_Temp_FD11
      SendCANR_SGCP_Temp_FD11Vld: nonqueued-receiver-com-spec{data-element=SendCANR_SGCP_Temp_FD11Vld, init-value=SendCANR_SGCP_Temp_FD11VldValue:1}, required-interface=SendCANR_SGCP_Temp_FD11Vld
      SendCANR_SGCP_DC_Current_P_FD11: nonqueued-receiver-com-spec{data-element=SendCANR_SGCP_DC_Current_P_FD11, init-value=SendCANR_SGCP_DC_Current_P_FD11Value:0}, required-interface=SendCANR_SGCP_DC_Current_P_FD11
      SendCANR_SGCP_DC_Current_P_FD11Vld: nonqueued-receiver-com-spec{data-element=SendCANR_SGCP_DC_Current_P_FD11Vld, init-value=SendCANR_SGCP_DC_Current_P_FD11VldValue:1}, required-interface=SendCANR_SGCP_DC_Current_P_FD11Vld
      SendCANR_QualifyDriveCycle_FD11: nonqueued-receiver-com-spec{data-element=SendCANR_QualifyDriveCycle_FD11, init-value=SendCANR_QualifyDriveCycle_FD11Value:0}, required-interface=SendCANR_QualifyDriveCycle_FD11
      SendCANR_QualifyDriveCycle_FD11Vld: nonqueued-receiver-com-spec{data-element=SendCANR_QualifyDriveCycle_FD11Vld, init-value=SendCANR_QualifyDriveCycle_FD11VldValue:1}, required-interface=SendCANR_QualifyDriveCycle_FD11Vld
      SendCANR_GPS_Date_Day_FD11: nonqueued-receiver-com-spec{data-element=SendCANR_GPS_Date_Day_FD11, init-value=SendCANR_GPS_Date_Day_FD11Value:255}, required-interface=SendCANR_GPS_Date_Day_FD11
      SendCANR_GPS_Date_Day_FD11Vld: nonqueued-receiver-com-spec{data-element=SendCANR_GPS_Date_Day_FD11Vld, init-value=SendCANR_GPS_Date_Day_FD11VldValue:1}, required-interface=SendCANR_GPS_Date_Day_FD11Vld
      SendCANR_GPS_Date_Month_FD11: nonqueued-receiver-com-spec{data-element=SendCANR_GPS_Date_Month_FD11, init-value=SendCANR_GPS_Date_Month_FD11Value:255}, required-interface=SendCANR_GPS_Date_Month_FD11
      SendCANR_GPS_Date_Month_FD11Vld: nonqueued-receiver-com-spec{data-element=SendCANR_GPS_Date_Month_FD11Vld, init-value=SendCANR_GPS_Date_Month_FD11VldValue:1}, required-interface=SendCANR_GPS_Date_Month_FD11Vld
      SendCANR_GPS_Date_Year_FD11: nonqueued-receiver-com-spec{data-element=SendCANR_GPS_Date_Year_FD11, init-value=SendCANR_GPS_Date_Year_FD11Value:65535}, required-interface=SendCANR_GPS_Date_Year_FD11
      SendCANR_GPS_Date_Year_FD11Vld: nonqueued-receiver-com-spec{data-element=SendCANR_GPS_Date_Year_FD11Vld, init-value=SendCANR_GPS_Date_Year_FD11VldValue:1}, required-interface=SendCANR_GPS_Date_Year_FD11Vld
      SendCANR_GPS_UTC_Hour_FD11: nonqueued-receiver-com-spec{data-element=SendCANR_GPS_UTC_Hour_FD11, init-value=SendCANR_GPS_UTC_Hour_FD11Value:255}, required-interface=SendCANR_GPS_UTC_Hour_FD11
      SendCANR_GPS_UTC_Hour_FD11Vld: nonqueued-receiver-com-spec{data-element=SendCANR_GPS_UTC_Hour_FD11Vld, init-value=SendCANR_GPS_UTC_Hour_FD11VldValue:1}, required-interface=SendCANR_GPS_UTC_Hour_FD11Vld
      SendCANR_GPS_UTC_Minute_FD11: nonqueued-receiver-com-spec{data-element=SendCANR_GPS_UTC_Minute_FD11, init-value=SendCANR_GPS_UTC_Minute_FD11Value:255}, required-interface=SendCANR_GPS_UTC_Minute_FD11
      SendCANR_GPS_UTC_Minute_FD11Vld: nonqueued-receiver-com-spec{data-element=SendCANR_GPS_UTC_Minute_FD11Vld, init-value=SendCANR_GPS_UTC_Minute_FD11VldValue:1}, required-interface=SendCANR_GPS_UTC_Minute_FD11Vld
      SendCANR_GPS_UTC_Second_FD11: nonqueued-receiver-com-spec{data-element=SendCANR_GPS_UTC_Second_FD11, init-value=SendCANR_GPS_UTC_Second_FD11Value:655.35}, required-interface=SendCANR_GPS_UTC_Second_FD11
      SendCANR_GPS_UTC_Second_FD11Vld: nonqueued-receiver-com-spec{data-element=SendCANR_GPS_UTC_Second_FD11Vld, init-value=SendCANR_GPS_UTC_Second_FD11VldValue:1}, required-interface=SendCANR_GPS_UTC_Second_FD11Vld
      SendCANR_GearEngagedForDisplay: nonqueued-receiver-com-spec{data-element=SendCANR_GearEngagedForDisplay, init-value=SendCANR_GearEngagedForDisplayValue:31}, required-interface=SendCANR_GearEngagedForDisplay
      SendCANR_GearEngagedForDisplayVld: nonqueued-receiver-com-spec{data-element=SendCANR_GearEngagedForDisplayVld, init-value=SendCANR_GearEngagedForDisplayVldValue:1}, required-interface=SendCANR_GearEngagedForDisplayVld
      SendCANR_HVCMS_BulChrgnCmplFD11: nonqueued-receiver-com-spec{data-element=SendCANR_HVCMS_BulChrgnCmplFD11, init-value=SendCANR_HVCMS_BulChrgnCmplFD11Value:0}, required-interface=SendCANR_HVCMS_BulChrgnCmplFD11
      SendCANR_HVCMS_BulChrgnCmplFD11Vld: nonqueued-receiver-com-spec{data-element=SendCANR_HVCMS_BulChrgnCmplFD11Vld, init-value=SendCANR_HVCMS_BulChrgnCmplFD11VldValue:1}, required-interface=SendCANR_HVCMS_BulChrgnCmplFD11Vld
      SendCANR_HVCMS_ChrgnCmpl_FD11: nonqueued-receiver-com-spec{data-element=SendCANR_HVCMS_ChrgnCmpl_FD11, init-value=SendCANR_HVCMS_ChrgnCmpl_FD11Value:0}, required-interface=SendCANR_HVCMS_ChrgnCmpl_FD11
      SendCANR_HVCMS_ChrgnCmpl_FD11Vld: nonqueued-receiver-com-spec{data-element=SendCANR_HVCMS_ChrgnCmpl_FD11Vld, init-value=SendCANR_HVCMS_ChrgnCmpl_FD11VldValue:1}, required-interface=SendCANR_HVCMS_ChrgnCmpl_FD11Vld
      SendCANR_HVCMS_EVEgyCap_FD11: nonqueued-receiver-com-spec{data-element=SendCANR_HVCMS_EVEgyCap_FD11, init-value=SendCANR_HVCMS_EVEgyCap_FD11Value:0}, required-interface=SendCANR_HVCMS_EVEgyCap_FD11
      SendCANR_HVCMS_EVEgyCap_FD11Vld: nonqueued-receiver-com-spec{data-element=SendCANR_HVCMS_EVEgyCap_FD11Vld, init-value=SendCANR_HVCMS_EVEgyCap_FD11VldValue:1}, required-interface=SendCANR_HVCMS_EVEgyCap_FD11Vld
      SendCANR_HVCMS_EVEgyReq_FD11: nonqueued-receiver-com-spec{data-element=SendCANR_HVCMS_EVEgyReq_FD11, init-value=SendCANR_HVCMS_EVEgyReq_FD11Value:131071}, required-interface=SendCANR_HVCMS_EVEgyReq_FD11
      SendCANR_HVCMS_EVEgyReq_FD11Vld: nonqueued-receiver-com-spec{data-element=SendCANR_HVCMS_EVEgyReq_FD11Vld, init-value=SendCANR_HVCMS_EVEgyReq_FD11VldValue:1}, required-interface=SendCANR_HVCMS_EVEgyReq_FD11Vld
      SendCANR_HVCMS_EVErrorCode_FD11: nonqueued-receiver-com-spec{data-element=SendCANR_HVCMS_EVErrorCode_FD11, init-value=SendCANR_HVCMS_EVErrorCode_FD11Value:0}, required-interface=SendCANR_HVCMS_EVErrorCode_FD11
      SendCANR_HVCMS_EVErrorCode_FD11Vld: nonqueued-receiver-com-spec{data-element=SendCANR_HVCMS_EVErrorCode_FD11Vld, init-value=SendCANR_HVCMS_EVErrorCode_FD11VldValue:1}, required-interface=SendCANR_HVCMS_EVErrorCode_FD11Vld
      SendCANR_HVCMS_EVMaxILimit_FD11: nonqueued-receiver-com-spec{data-element=SendCANR_HVCMS_EVMaxILimit_FD11, init-value=SendCANR_HVCMS_EVMaxILimit_FD11Value:-500}, required-interface=SendCANR_HVCMS_EVMaxILimit_FD11
      SendCANR_HVCMS_EVMaxILimit_FD11Vld: nonqueued-receiver-com-spec{data-element=SendCANR_HVCMS_EVMaxILimit_FD11Vld, init-value=SendCANR_HVCMS_EVMaxILimit_FD11VldValue:1}, required-interface=SendCANR_HVCMS_EVMaxILimit_FD11Vld
      SendCANR_HVCMS_EVMaxPLimit_FD11: nonqueued-receiver-com-spec{data-element=SendCANR_HVCMS_EVMaxPLimit_FD11, init-value=SendCANR_HVCMS_EVMaxPLimit_FD11Value:0}, required-interface=SendCANR_HVCMS_EVMaxPLimit_FD11
      SendCANR_HVCMS_EVMaxPLimit_FD11Vld: nonqueued-receiver-com-spec{data-element=SendCANR_HVCMS_EVMaxPLimit_FD11Vld, init-value=SendCANR_HVCMS_EVMaxPLimit_FD11VldValue:1}, required-interface=SendCANR_HVCMS_EVMaxPLimit_FD11Vld
      SendCANR_HVCMSEVMaxVLimit_FD11: nonqueued-receiver-com-spec{data-element=SendCANR_HVCMSEVMaxVLimit_FD11, init-value=SendCANR_HVCMSEVMaxVLimit_FD11Value:0}, required-interface=SendCANR_HVCMSEVMaxVLimit_FD11
      SendCANR_HVCMSEVMaxVLimit_FD11Vld: nonqueued-receiver-com-spec{data-element=SendCANR_HVCMSEVMaxVLimit_FD11Vld, init-value=SendCANR_HVCMSEVMaxVLimit_FD11VldValue:1}, required-interface=SendCANR_HVCMSEVMaxVLimit_FD11Vld
      SendCANR_HVCMS_EVReady_FD11: nonqueued-receiver-com-spec{data-element=SendCANR_HVCMS_EVReady_FD11, init-value=SendCANR_HVCMS_EVReady_FD11Value:0}, required-interface=SendCANR_HVCMS_EVReady_FD11
      SendCANR_HVCMS_EVReady_FD11Vld: nonqueued-receiver-com-spec{data-element=SendCANR_HVCMS_EVReady_FD11Vld, init-value=SendCANR_HVCMS_EVReady_FD11VldValue:1}, required-interface=SendCANR_HVCMS_EVReady_FD11Vld
      SendCANR_HVCMS_EVRESS_SOC_FD11: nonqueued-receiver-com-spec{data-element=SendCANR_HVCMS_EVRESS_SOC_FD11, init-value=SendCANR_HVCMS_EVRESS_SOC_FD11Value:0}, required-interface=SendCANR_HVCMS_EVRESS_SOC_FD11
      SendCANR_HVCMS_EVRESS_SOC_FD11Vld: nonqueued-receiver-com-spec{data-element=SendCANR_HVCMS_EVRESS_SOC_FD11Vld, init-value=SendCANR_HVCMS_EVRESS_SOC_FD11VldValue:1}, required-interface=SendCANR_HVCMS_EVRESS_SOC_FD11Vld
      SendCANR_HVCMS_EVRESSCdng_FD11: nonqueued-receiver-com-spec{data-element=SendCANR_HVCMS_EVRESSCdng_FD11, init-value=SendCANR_HVCMS_EVRESSCdng_FD11Value:0}, required-interface=SendCANR_HVCMS_EVRESSCdng_FD11
      SendCANR_HVCMS_EVRESSCdng_FD11Vld: nonqueued-receiver-com-spec{data-element=SendCANR_HVCMS_EVRESSCdng_FD11Vld, init-value=SendCANR_HVCMS_EVRESSCdng_FD11VldValue:1}, required-interface=SendCANR_HVCMS_EVRESSCdng_FD11Vld
      SendCANR_HVCMS_EVTarCurr_FD11: nonqueued-receiver-com-spec{data-element=SendCANR_HVCMS_EVTarCurr_FD11, init-value=SendCANR_HVCMS_EVTarCurr_FD11Value:-500}, required-interface=SendCANR_HVCMS_EVTarCurr_FD11
      SendCANR_HVCMS_EVTarCurr_FD11Vld: nonqueued-receiver-com-spec{data-element=SendCANR_HVCMS_EVTarCurr_FD11Vld, init-value=SendCANR_HVCMS_EVTarCurr_FD11VldValue:1}, required-interface=SendCANR_HVCMS_EVTarCurr_FD11Vld
      SendCANR_HVCMS_EVTarVolt_FD11: nonqueued-receiver-com-spec{data-element=SendCANR_HVCMS_EVTarVolt_FD11, init-value=SendCANR_HVCMS_EVTarVolt_FD11Value:0}, required-interface=SendCANR_HVCMS_EVTarVolt_FD11
      SendCANR_HVCMS_EVTarVolt_FD11Vld: nonqueued-receiver-com-spec{data-element=SendCANR_HVCMS_EVTarVolt_FD11Vld, init-value=SendCANR_HVCMS_EVTarVolt_FD11VldValue:1}, required-interface=SendCANR_HVCMS_EVTarVolt_FD11Vld
      SendCANR_HVCMS_PrtclEntry1_FD11: nonqueued-receiver-com-spec{data-element=SendCANR_HVCMS_PrtclEntry1_FD11, init-value=SendCANR_HVCMS_PrtclEntry1_FD11Value:0}, required-interface=SendCANR_HVCMS_PrtclEntry1_FD11
      SendCANR_HVCMS_PrtclEntry1_FD11Vld: nonqueued-receiver-com-spec{data-element=SendCANR_HVCMS_PrtclEntry1_FD11Vld, init-value=SendCANR_HVCMS_PrtclEntry1_FD11VldValue:1}, required-interface=SendCANR_HVCMS_PrtclEntry1_FD11Vld
      SendCANR_HVCMS_PrtclEntry2_FD11: nonqueued-receiver-com-spec{data-element=SendCANR_HVCMS_PrtclEntry2_FD11, init-value=SendCANR_HVCMS_PrtclEntry2_FD11Value:0}, required-interface=SendCANR_HVCMS_PrtclEntry2_FD11
      SendCANR_HVCMS_PrtclEntry2_FD11Vld: nonqueued-receiver-com-spec{data-element=SendCANR_HVCMS_PrtclEntry2_FD11Vld, init-value=SendCANR_HVCMS_PrtclEntry2_FD11VldValue:1}, required-interface=SendCANR_HVCMS_PrtclEntry2_FD11Vld
      SendCANR_HVCMS_PrtclEntry3_FD11: nonqueued-receiver-com-spec{data-element=SendCANR_HVCMS_PrtclEntry3_FD11, init-value=SendCANR_HVCMS_PrtclEntry3_FD11Value:0}, required-interface=SendCANR_HVCMS_PrtclEntry3_FD11
      SendCANR_HVCMS_PrtclEntry3_FD11Vld: nonqueued-receiver-com-spec{data-element=SendCANR_HVCMS_PrtclEntry3_FD11Vld, init-value=SendCANR_HVCMS_PrtclEntry3_FD11VldValue:1}, required-interface=SendCANR_HVCMS_PrtclEntry3_FD11Vld
      SendCANR_HVCMS_RdyToChrgSt_FD11: nonqueued-receiver-com-spec{data-element=SendCANR_HVCMS_RdyToChrgSt_FD11, init-value=SendCANR_HVCMS_RdyToChrgSt_FD11Value:0}, required-interface=SendCANR_HVCMS_RdyToChrgSt_FD11
      SendCANR_HVCMS_RdyToChrgSt_FD11Vld: nonqueued-receiver-com-spec{data-element=SendCANR_HVCMS_RdyToChrgSt_FD11Vld, init-value=SendCANR_HVCMS_RdyToChrgSt_FD11VldValue:1}, required-interface=SendCANR_HVCMS_RdyToChrgSt_FD11Vld
      SendCANR_HVCMS_RmnTiToBuSOCFD11: nonqueued-receiver-com-spec{data-element=SendCANR_HVCMS_RmnTiToBuSOCFD11, init-value=SendCANR_HVCMS_RmnTiToBuSOCFD11Value:0}, required-interface=SendCANR_HVCMS_RmnTiToBuSOCFD11
      SendCANR_HVCMS_RmnTiToBuSOCFD11Vld: nonqueued-receiver-com-spec{data-element=SendCANR_HVCMS_RmnTiToBuSOCFD11Vld, init-value=SendCANR_HVCMS_RmnTiToBuSOCFD11VldValue:1}, required-interface=SendCANR_HVCMS_RmnTiToBuSOCFD11Vld
      SendCANR_HVCMS_RmnTiToFuSOCFD11: nonqueued-receiver-com-spec{data-element=SendCANR_HVCMS_RmnTiToFuSOCFD11, init-value=SendCANR_HVCMS_RmnTiToFuSOCFD11Value:0}, required-interface=SendCANR_HVCMS_RmnTiToFuSOCFD11
      SendCANR_HVCMS_RmnTiToFuSOCFD11Vld: nonqueued-receiver-com-spec{data-element=SendCANR_HVCMS_RmnTiToFuSOCFD11Vld, init-value=SendCANR_HVCMS_RmnTiToFuSOCFD11VldValue:1}, required-interface=SendCANR_HVCMS_RmnTiToFuSOCFD11Vld
      SendCANR_HVCMS_SelEgyTrfTypFD11: nonqueued-receiver-com-spec{data-element=SendCANR_HVCMS_SelEgyTrfTypFD11, init-value=SendCANR_HVCMS_SelEgyTrfTypFD11Value:0}, required-interface=SendCANR_HVCMS_SelEgyTrfTypFD11
      SendCANR_HVCMS_SelEgyTrfTypFD11Vld: nonqueued-receiver-com-spec{data-element=SendCANR_HVCMS_SelEgyTrfTypFD11Vld, init-value=SendCANR_HVCMS_SelEgyTrfTypFD11VldValue:1}, required-interface=SendCANR_HVCMS_SelEgyTrfTypFD11Vld
      SendCANR_HVCMS_SelPmtOptn_FD11: nonqueued-receiver-com-spec{data-element=SendCANR_HVCMS_SelPmtOptn_FD11, init-value=SendCANR_HVCMS_SelPmtOptn_FD11Value:0}, required-interface=SendCANR_HVCMS_SelPmtOptn_FD11
      SendCANR_HVCMS_SelPmtOptn_FD11Vld: nonqueued-receiver-com-spec{data-element=SendCANR_HVCMS_SelPmtOptn_FD11Vld, init-value=SendCANR_HVCMS_SelPmtOptn_FD11VldValue:1}, required-interface=SendCANR_HVCMS_SelPmtOptn_FD11Vld
      SendCANR_HVCMS_SelServId_FD11: nonqueued-receiver-com-spec{data-element=SendCANR_HVCMS_SelServId_FD11, init-value=SendCANR_HVCMS_SelServId_FD11Value:0}, required-interface=SendCANR_HVCMS_SelServId_FD11
      SendCANR_HVCMS_SelServId_FD11Vld: nonqueued-receiver-com-spec{data-element=SendCANR_HVCMS_SelServId_FD11Vld, init-value=SendCANR_HVCMS_SelServId_FD11VldValue:1}, required-interface=SendCANR_HVCMS_SelServId_FD11Vld
      SendCANR_HVCMS_ServCtgy_FD11: nonqueued-receiver-com-spec{data-element=SendCANR_HVCMS_ServCtgy_FD11, init-value=SendCANR_HVCMS_ServCtgy_FD11Value:0}, required-interface=SendCANR_HVCMS_ServCtgy_FD11
      SendCANR_HVCMS_ServCtgy_FD11Vld: nonqueued-receiver-com-spec{data-element=SendCANR_HVCMS_ServCtgy_FD11Vld, init-value=SendCANR_HVCMS_ServCtgy_FD11VldValue:1}, required-interface=SendCANR_HVCMS_ServCtgy_FD11Vld
      SendCANR_HVCMS_ServScope_FD11: nonqueued-receiver-com-spec{data-element=SendCANR_HVCMS_ServScope_FD11, init-value=SendCANR_HVCMS_ServScope_FD11Value:0}, required-interface=SendCANR_HVCMS_ServScope_FD11
      SendCANR_HVCMS_ServScope_FD11Vld: nonqueued-receiver-com-spec{data-element=SendCANR_HVCMS_ServScope_FD11Vld, init-value=SendCANR_HVCMS_ServScope_FD11VldValue:1}, required-interface=SendCANR_HVCMS_ServScope_FD11Vld
      SendCANR_OBCMOutVoltSyncTgtFD11: nonqueued-receiver-com-spec{data-element=SendCANR_OBCMOutVoltSyncTgtFD11, init-value=SendCANR_OBCMOutVoltSyncTgtFD11Value:0}, required-interface=SendCANR_OBCMOutVoltSyncTgtFD11
      SendCANR_OBCMOutVoltSyncTgtFD11Vld: nonqueued-receiver-com-spec{data-element=SendCANR_OBCMOutVoltSyncTgtFD11Vld, init-value=SendCANR_OBCMOutVoltSyncTgtFD11VldValue:1}, required-interface=SendCANR_OBCMOutVoltSyncTgtFD11Vld
      SendCANR_V2X_HVCMSSltdEngTrfTyp: nonqueued-receiver-com-spec{data-element=SendCANR_V2X_HVCMSSltdEngTrfTyp, init-value=SendCANR_V2X_HVCMSSltdEngTrfTypValue:0}, required-interface=SendCANR_V2X_HVCMSSltdEngTrfTyp
      SendCANR_V2X_HVCMSSltdEngTrfTypVld: nonqueued-receiver-com-spec{data-element=SendCANR_V2X_HVCMSSltdEngTrfTypVld, init-value=SendCANR_V2X_HVCMSSltdEngTrfTypVldValue:1}, required-interface=SendCANR_V2X_HVCMSSltdEngTrfTypVld
      SendCANR_VDCM_BattBulkSOC_FD11: nonqueued-receiver-com-spec{data-element=SendCANR_VDCM_BattBulkSOC_FD11, init-value=SendCANR_VDCM_BattBulkSOC_FD11Value:0}, required-interface=SendCANR_VDCM_BattBulkSOC_FD11
      SendCANR_VDCM_BattBulkSOC_FD11Vld: nonqueued-receiver-com-spec{data-element=SendCANR_VDCM_BattBulkSOC_FD11Vld, init-value=SendCANR_VDCM_BattBulkSOC_FD11VldValue:1}, required-interface=SendCANR_VDCM_BattBulkSOC_FD11Vld
      SendCANR_VDCMCntrtAuthentIDFD11: nonqueued-receiver-com-spec{data-element=SendCANR_VDCMCntrtAuthentIDFD11, init-value=SendCANR_VDCMCntrtAuthentIDFD11Value:0}, required-interface=SendCANR_VDCMCntrtAuthentIDFD11
      SendCANR_VDCMCntrtAuthentIDFD11Vld: nonqueued-receiver-com-spec{data-element=SendCANR_VDCMCntrtAuthentIDFD11Vld, init-value=SendCANR_VDCMCntrtAuthentIDFD11VldValue:1}, required-interface=SendCANR_VDCMCntrtAuthentIDFD11Vld
      SendCANR_VDCM_GenChallenge_FD11: nonqueued-receiver-com-spec{data-element=SendCANR_VDCM_GenChallenge_FD11, init-value=SendCANR_VDCM_GenChallenge_FD11Value:0}, required-interface=SendCANR_VDCM_GenChallenge_FD11
      SendCANR_VDCM_GenChallenge_FD11Vld: nonqueued-receiver-com-spec{data-element=SendCANR_VDCM_GenChallenge_FD11Vld, init-value=SendCANR_VDCM_GenChallenge_FD11VldValue:1}, required-interface=SendCANR_VDCM_GenChallenge_FD11Vld
      SendCANR_VDCMOBCDchaCurrLimFD11: nonqueued-receiver-com-spec{data-element=SendCANR_VDCMOBCDchaCurrLimFD11, init-value=SendCANR_VDCMOBCDchaCurrLimFD11Value:-733.5}, required-interface=SendCANR_VDCMOBCDchaCurrLimFD11
      SendCANR_VDCMOBCDchaCurrLimFD11Vld: nonqueued-receiver-com-spec{data-element=SendCANR_VDCMOBCDchaCurrLimFD11Vld, init-value=SendCANR_VDCMOBCDchaCurrLimFD11VldValue:1}, required-interface=SendCANR_VDCMOBCDchaCurrLimFD11Vld
      SendCANR_VDCMTypeCNegotnStsFD11: nonqueued-receiver-com-spec{data-element=SendCANR_VDCMTypeCNegotnStsFD11, init-value=SendCANR_VDCMTypeCNegotnStsFD11Value:0}, required-interface=SendCANR_VDCMTypeCNegotnStsFD11
      SendCANR_VDCMTypeCNegotnStsFD11Vld: nonqueued-receiver-com-spec{data-element=SendCANR_VDCMTypeCNegotnStsFD11Vld, init-value=SendCANR_VDCMTypeCNegotnStsFD11VldValue:1}, required-interface=SendCANR_VDCMTypeCNegotnStsFD11Vld
      SendCANR_ClrLgsDiagInfo_FD11: nonqueued-receiver-com-spec{data-element=SendCANR_ClrLgsDiagInfo_FD11, init-value=SendCANR_ClrLgsDiagInfo_FD11Value:0}, required-interface=SendCANR_ClrLgsDiagInfo_FD11
      SendCANR_ClrLgsDiagInfo_FD11Vld: nonqueued-receiver-com-spec{data-element=SendCANR_ClrLgsDiagInfo_FD11Vld, init-value=SendCANR_ClrLgsDiagInfo_FD11VldValue:1}, required-interface=SendCANR_ClrLgsDiagInfo_FD11Vld
      SendCANR_VIN_DATA_FD11: nonqueued-receiver-com-spec{data-element=SendCANR_VIN_DATA_FD11, init-value=SendCANR_VIN_DATA_FD11Value:0}, required-interface=SendCANR_VIN_DATA_FD11
      SendCANR_VIN_DATA_FD11Vld: nonqueued-receiver-com-spec{data-element=SendCANR_VIN_DATA_FD11Vld, init-value=SendCANR_VIN_DATA_FD11VldValue:1}, required-interface=SendCANR_VIN_DATA_FD11Vld
      SendCANR_VIN_MSG_FD11: nonqueued-receiver-com-spec{data-element=SendCANR_VIN_MSG_FD11, init-value=SendCANR_VIN_MSG_FD11Value:3}, required-interface=SendCANR_VIN_MSG_FD11
      SendCANR_VIN_MSG_FD11Vld: nonqueued-receiver-com-spec{data-element=SendCANR_VIN_MSG_FD11Vld, init-value=SendCANR_VIN_MSG_FD11VldValue:1}, required-interface=SendCANR_VIN_MSG_FD11Vld
    behavior IBApplCanComAb_FD11: data-type-mapping=ADTtoIDTMapping, handle-termination-and-restart=NO-SUPPORT
      init event IninEve: start-on-event=ApplCanComAb_FD11Inin
      data received event DRECOMRX_APM2_BoostSwitchSts_APM2_VDCM_FD11: start-on-event=COMRX_APM2_BoostSwitchSts_APM2_VDCM_FD11_Received, data=CanCom_FD11RxSignalsSR.COMRX_APM2_BoostSwitchSts_APM2_VDCM_FD11
      data receive error event DEECOMRX_APM2_BoostSwitchSts_APM2_VDCM_FD11: start-on-event=COMRX_APM2_BoostSwitchSts_APM2_VDCM_FD11_Error, data=CanCom_FD11RxSignalsSR.COMRX_APM2_BoostSwitchSts_APM2_VDCM_FD11
      data received event DRECOMRX_APM2_ContactorFault_APM2_VDCM_FD11: start-on-event=COMRX_APM2_ContactorFault_APM2_VDCM_FD11_Received, data=CanCom_FD11RxSignalsSR.COMRX_APM2_ContactorFault_APM2_VDCM_FD11
      data receive error event DEECOMRX_APM2_ContactorFault_APM2_VDCM_FD11: start-on-event=COMRX_APM2_ContactorFault_APM2_VDCM_FD11_Error, data=CanCom_FD11RxSignalsSR.COMRX_APM2_ContactorFault_APM2_VDCM_FD11
      data received event DRECOMRX_APM2_DcChEnaSts_Fdbk_APM2_VDCM_FD11: start-on-event=COMRX_APM2_DcChEnaSts_Fdbk_APM2_VDCM_FD11_Received, data=CanCom_FD11RxSignalsSR.COMRX_APM2_DcChEnaSts_Fdbk_APM2_VDCM_FD11
      data receive error event DEECOMRX_APM2_DcChEnaSts_Fdbk_APM2_VDCM_FD11: start-on-event=COMRX_APM2_DcChEnaSts_Fdbk_APM2_VDCM_FD11_Error, data=CanCom_FD11RxSignalsSR.COMRX_APM2_DcChEnaSts_Fdbk_APM2_VDCM_FD11
      data received event DRECOMRX_APM2_DeratRsnSts_APM2_VDCM_FD11: start-on-event=COMRX_APM2_DeratRsnSts_APM2_VDCM_FD11_Received, data=CanCom_FD11RxSignalsSR.COMRX_APM2_DeratRsnSts_APM2_VDCM_FD11
      data receive error event DEECOMRX_APM2_DeratRsnSts_APM2_VDCM_FD11: start-on-event=COMRX_APM2_DeratRsnSts_APM2_VDCM_FD11_Error, data=CanCom_FD11RxSignalsSR.COMRX_APM2_DeratRsnSts_APM2_VDCM_FD11
      data received event DRECOMRX_APM2_DisChargedSts_Fdbk_APM2_VDCM_FD11: start-on-event=COMRX_APM2_DisChargedSts_Fdbk_APM2_VDCM_FD11_Received, data=CanCom_FD11RxSignalsSR.COMRX_APM2_DisChargedSts_Fdbk_APM2_VDCM_FD11
      data receive error event DEECOMRX_APM2_DisChargedSts_Fdbk_APM2_VDCM_FD11: start-on-event=COMRX_APM2_DisChargedSts_Fdbk_APM2_VDCM_FD11_Error, data=CanCom_FD11RxSignalsSR.COMRX_APM2_DisChargedSts_Fdbk_APM2_VDCM_FD11
      data received event DRECOMRX_APM2_ErrorWord_APM2_VDCM_FD11: start-on-event=COMRX_APM2_ErrorWord_APM2_VDCM_FD11_Received, data=CanCom_FD11RxSignalsSR.COMRX_APM2_ErrorWord_APM2_VDCM_FD11
      data receive error event DEECOMRX_APM2_ErrorWord_APM2_VDCM_FD11: start-on-event=COMRX_APM2_ErrorWord_APM2_VDCM_FD11_Error, data=CanCom_FD11RxSignalsSR.COMRX_APM2_ErrorWord_APM2_VDCM_FD11
      data received event DRECOMRX_APM2_FaultSts_APM2_VDCM_FD11: start-on-event=COMRX_APM2_FaultSts_APM2_VDCM_FD11_Received, data=CanCom_FD11RxSignalsSR.COMRX_APM2_FaultSts_APM2_VDCM_FD11
      data receive error event DEECOMRX_APM2_FaultSts_APM2_VDCM_FD11: start-on-event=COMRX_APM2_FaultSts_APM2_VDCM_FD11_Error, data=CanCom_FD11RxSignalsSR.COMRX_APM2_FaultSts_APM2_VDCM_FD11
      data received event DRECOMRX_APM2_HVChrgBusCurrent_APM2_VDCM_FD11: start-on-event=COMRX_APM2_HVChrgBusCurrent_APM2_VDCM_FD11_Received, data=CanCom_FD11RxSignalsSR.COMRX_APM2_HVChrgBusCurrent_APM2_VDCM_FD11
      data receive error event DEECOMRX_APM2_HVChrgBusCurrent_APM2_VDCM_FD11: start-on-event=COMRX_APM2_HVChrgBusCurrent_APM2_VDCM_FD11_Error, data=CanCom_FD11RxSignalsSR.COMRX_APM2_HVChrgBusCurrent_APM2_VDCM_FD11
      data received event DRECOMRX_APM2_HVChrgBusVoltage_APM2_VDCM_FD11: start-on-event=COMRX_APM2_HVChrgBusVoltage_APM2_VDCM_FD11_Received, data=CanCom_FD11RxSignalsSR.COMRX_APM2_HVChrgBusVoltage_APM2_VDCM_FD11
      data receive error event DEECOMRX_APM2_HVChrgBusVoltage_APM2_VDCM_FD11: start-on-event=COMRX_APM2_HVChrgBusVoltage_APM2_VDCM_FD11_Error, data=CanCom_FD11RxSignalsSR.COMRX_APM2_HVChrgBusVoltage_APM2_VDCM_FD11
      data received event DRECOMRX_APM2_IInpMaxCnvr_APM2_VDCM_FD11: start-on-event=COMRX_APM2_IInpMaxCnvr_APM2_VDCM_FD11_Received, data=CanCom_FD11RxSignalsSR.COMRX_APM2_IInpMaxCnvr_APM2_VDCM_FD11
      data receive error event DEECOMRX_APM2_IInpMaxCnvr_APM2_VDCM_FD11: start-on-event=COMRX_APM2_IInpMaxCnvr_APM2_VDCM_FD11_Error, data=CanCom_FD11RxSignalsSR.COMRX_APM2_IInpMaxCnvr_APM2_VDCM_FD11
      data received event DRECOMRX_APM2_K6_WldgDtnSts_APM2_VDCM_FD11: start-on-event=COMRX_APM2_K6_WldgDtnSts_APM2_VDCM_FD11_Received, data=CanCom_FD11RxSignalsSR.COMRX_APM2_K6_WldgDtnSts_APM2_VDCM_FD11
      data receive error event DEECOMRX_APM2_K6_WldgDtnSts_APM2_VDCM_FD11: start-on-event=COMRX_APM2_K6_WldgDtnSts_APM2_VDCM_FD11_Error, data=CanCom_FD11RxSignalsSR.COMRX_APM2_K6_WldgDtnSts_APM2_VDCM_FD11
      data received event DRECOMRX_APM2_K7_WldgDtnSts_APM2_VDCM_FD11: start-on-event=COMRX_APM2_K7_WldgDtnSts_APM2_VDCM_FD11_Received, data=CanCom_FD11RxSignalsSR.COMRX_APM2_K7_WldgDtnSts_APM2_VDCM_FD11
      data receive error event DEECOMRX_APM2_K7_WldgDtnSts_APM2_VDCM_FD11: start-on-event=COMRX_APM2_K7_WldgDtnSts_APM2_VDCM_FD11_Error, data=CanCom_FD11RxSignalsSR.COMRX_APM2_K7_WldgDtnSts_APM2_VDCM_FD11
      data received event DRECOMRX_APM2_ModeSts_Fbk_APM2_VDCM_FD11: start-on-event=COMRX_APM2_ModeSts_Fbk_APM2_VDCM_FD11_Received, data=CanCom_FD11RxSignalsSR.COMRX_APM2_ModeSts_Fbk_APM2_VDCM_FD11
      data receive error event DEECOMRX_APM2_ModeSts_Fbk_APM2_VDCM_FD11: start-on-event=COMRX_APM2_ModeSts_Fbk_APM2_VDCM_FD11_Error, data=CanCom_FD11RxSignalsSR.COMRX_APM2_ModeSts_Fbk_APM2_VDCM_FD11
      data received event DRECOMRX_APM2_RecoveryAction_APM2_VDCM_FD11: start-on-event=COMRX_APM2_RecoveryAction_APM2_VDCM_FD11_Received, data=CanCom_FD11RxSignalsSR.COMRX_APM2_RecoveryAction_APM2_VDCM_FD11
      data receive error event DEECOMRX_APM2_RecoveryAction_APM2_VDCM_FD11: start-on-event=COMRX_APM2_RecoveryAction_APM2_VDCM_FD11_Error, data=CanCom_FD11RxSignalsSR.COMRX_APM2_RecoveryAction_APM2_VDCM_FD11
      data received event DRECOMRX_APM2_Service_Lamp_Request_APM2_VDCM_FD11: start-on-event=COMRX_APM2_Service_Lamp_Request_APM2_VDCM_FD11_Received, data=CanCom_FD11RxSignalsSR.COMRX_APM2_Service_Lamp_Request_APM2_VDCM_FD11
      data receive error event DEECOMRX_APM2_Service_Lamp_Request_APM2_VDCM_FD11: start-on-event=COMRX_APM2_Service_Lamp_Request_APM2_VDCM_FD11_Error, data=CanCom_FD11RxSignalsSR.COMRX_APM2_Service_Lamp_Request_APM2_VDCM_FD11
      data received event DRECOMRX_APM2_TempFET1_APM2_VDCM_FD11: start-on-event=COMRX_APM2_TempFET1_APM2_VDCM_FD11_Received, data=CanCom_FD11RxSignalsSR.COMRX_APM2_TempFET1_APM2_VDCM_FD11
      data receive error event DEECOMRX_APM2_TempFET1_APM2_VDCM_FD11: start-on-event=COMRX_APM2_TempFET1_APM2_VDCM_FD11_Error, data=CanCom_FD11RxSignalsSR.COMRX_APM2_TempFET1_APM2_VDCM_FD11
      data received event DRECOMRX_APM2_TempFET2_APM2_VDCM_FD11: start-on-event=COMRX_APM2_TempFET2_APM2_VDCM_FD11_Received, data=CanCom_FD11RxSignalsSR.COMRX_APM2_TempFET2_APM2_VDCM_FD11
      data receive error event DEECOMRX_APM2_TempFET2_APM2_VDCM_FD11: start-on-event=COMRX_APM2_TempFET2_APM2_VDCM_FD11_Error, data=CanCom_FD11RxSignalsSR.COMRX_APM2_TempFET2_APM2_VDCM_FD11
      data received event DRECOMRX_APM2_TempInlet_APM2_VDCM_FD11: start-on-event=COMRX_APM2_TempInlet_APM2_VDCM_FD11_Received, data=CanCom_FD11RxSignalsSR.COMRX_APM2_TempInlet_APM2_VDCM_FD11
      data receive error event DEECOMRX_APM2_TempInlet_APM2_VDCM_FD11: start-on-event=COMRX_APM2_TempInlet_APM2_VDCM_FD11_Error, data=CanCom_FD11RxSignalsSR.COMRX_APM2_TempInlet_APM2_VDCM_FD11
      data received event DRECOMRX_APM2_TempInt_APM2_VDCM_FD11: start-on-event=COMRX_APM2_TempInt_APM2_VDCM_FD11_Received, data=CanCom_FD11RxSignalsSR.COMRX_APM2_TempInt_APM2_VDCM_FD11
      data receive error event DEECOMRX_APM2_TempInt_APM2_VDCM_FD11: start-on-event=COMRX_APM2_TempInt_APM2_VDCM_FD11_Error, data=CanCom_FD11RxSignalsSR.COMRX_APM2_TempInt_APM2_VDCM_FD11
      data received event DRECOMRX_APM2_TempL1_APM2_VDCM_FD11: start-on-event=COMRX_APM2_TempL1_APM2_VDCM_FD11_Received, data=CanCom_FD11RxSignalsSR.COMRX_APM2_TempL1_APM2_VDCM_FD11
      data receive error event DEECOMRX_APM2_TempL1_APM2_VDCM_FD11: start-on-event=COMRX_APM2_TempL1_APM2_VDCM_FD11_Error, data=CanCom_FD11RxSignalsSR.COMRX_APM2_TempL1_APM2_VDCM_FD11
      data received event DRECOMRX_APM2_TempL2_APM2_VDCM_FD11: start-on-event=COMRX_APM2_TempL2_APM2_VDCM_FD11_Received, data=CanCom_FD11RxSignalsSR.COMRX_APM2_TempL2_APM2_VDCM_FD11
      data receive error event DEECOMRX_APM2_TempL2_APM2_VDCM_FD11: start-on-event=COMRX_APM2_TempL2_APM2_VDCM_FD11_Error, data=CanCom_FD11RxSignalsSR.COMRX_APM2_TempL2_APM2_VDCM_FD11
      data received event DRECOMRX_APM2_TempMargin_APM2_VDCM_FD11: start-on-event=COMRX_APM2_TempMargin_APM2_VDCM_FD11_Received, data=CanCom_FD11RxSignalsSR.COMRX_APM2_TempMargin_APM2_VDCM_FD11
      data receive error event DEECOMRX_APM2_TempMargin_APM2_VDCM_FD11: start-on-event=COMRX_APM2_TempMargin_APM2_VDCM_FD11_Error, data=CanCom_FD11RxSignalsSR.COMRX_APM2_TempMargin_APM2_VDCM_FD11
      data received event DRECOMRX_APM2InterlockSts_APM2_VDCM_FD11: start-on-event=COMRX_APM2InterlockSts_APM2_VDCM_FD11_Received, data=CanCom_FD11RxSignalsSR.COMRX_APM2InterlockSts_APM2_VDCM_FD11
      data receive error event DEECOMRX_APM2InterlockSts_APM2_VDCM_FD11: start-on-event=COMRX_APM2InterlockSts_APM2_VDCM_FD11_Error, data=CanCom_FD11RxSignalsSR.COMRX_APM2InterlockSts_APM2_VDCM_FD11
      data received event DRECOMRX_CurrEVSE_APM2_VDCM_FD11: start-on-event=COMRX_CurrEVSE_APM2_VDCM_FD11_Received, data=CanCom_FD11RxSignalsSR.COMRX_CurrEVSE_APM2_VDCM_FD11
      data receive error event DEECOMRX_CurrEVSE_APM2_VDCM_FD11: start-on-event=COMRX_CurrEVSE_APM2_VDCM_FD11_Error, data=CanCom_FD11RxSignalsSR.COMRX_CurrEVSE_APM2_VDCM_FD11
      data received event DRECOMRX_PwrEff_APM2_VDCM_FD11: start-on-event=COMRX_PwrEff_APM2_VDCM_FD11_Received, data=CanCom_FD11RxSignalsSR.COMRX_PwrEff_APM2_VDCM_FD11
      data receive error event DEECOMRX_PwrEff_APM2_VDCM_FD11: start-on-event=COMRX_PwrEff_APM2_VDCM_FD11_Error, data=CanCom_FD11RxSignalsSR.COMRX_PwrEff_APM2_VDCM_FD11
      data received event DRECOMRX_VltgChgEVSE_APM2_VDCM_FD11: start-on-event=COMRX_VltgChgEVSE_APM2_VDCM_FD11_Received, data=CanCom_FD11RxSignalsSR.COMRX_VltgChgEVSE_APM2_VDCM_FD11
      data receive error event DEECOMRX_VltgChgEVSE_APM2_VDCM_FD11: start-on-event=COMRX_VltgChgEVSE_APM2_VDCM_FD11_Error, data=CanCom_FD11RxSignalsSR.COMRX_VltgChgEVSE_APM2_VDCM_FD11
      data received event DRECOMRX_VltgChgInt_APM2_VDCM_FD11: start-on-event=COMRX_VltgChgInt_APM2_VDCM_FD11_Received, data=CanCom_FD11RxSignalsSR.COMRX_VltgChgInt_APM2_VDCM_FD11
      data receive error event DEECOMRX_VltgChgInt_APM2_VDCM_FD11: start-on-event=COMRX_VltgChgInt_APM2_VDCM_FD11_Error, data=CanCom_FD11RxSignalsSR.COMRX_VltgChgInt_APM2_VDCM_FD11
      data received event DRECOMRX_ImpactHardwire_BATTERY_HV_FD11: start-on-event=COMRX_ImpactHardwire_BATTERY_HV_FD11_Received, data=CanCom_FD11RxSignalsSR.COMRX_ImpactHardwire_BATTERY_HV_FD11
      data receive error event DEECOMRX_ImpactHardwire_BATTERY_HV_FD11: start-on-event=COMRX_ImpactHardwire_BATTERY_HV_FD11_Error, data=CanCom_FD11RxSignalsSR.COMRX_ImpactHardwire_BATTERY_HV_FD11
      data received event DRECOMRX_ImpactHardwireV_BATTERY_HV_FD11: start-on-event=COMRX_ImpactHardwireV_BATTERY_HV_FD11_Received, data=CanCom_FD11RxSignalsSR.COMRX_ImpactHardwireV_BATTERY_HV_FD11
      data receive error event DEECOMRX_ImpactHardwireV_BATTERY_HV_FD11: start-on-event=COMRX_ImpactHardwireV_BATTERY_HV_FD11_Error, data=CanCom_FD11RxSignalsSR.COMRX_ImpactHardwireV_BATTERY_HV_FD11
      data received event DRECOMRX_BMS_HV_High_Temp_Thrsh_BATTERY_HV2_FD11: start-on-event=COMRX_BMS_HV_High_Temp_Thrsh_BATTERY_HV2_FD11_Received, data=CanCom_FD11RxSignalsSR.COMRX_BMS_HV_High_Temp_Thrsh_BATTERY_HV2_FD11
      data receive error event DEECOMRX_BMS_HV_High_Temp_Thrsh_BATTERY_HV2_FD11: start-on-event=COMRX_BMS_HV_High_Temp_Thrsh_BATTERY_HV2_FD11_Error, data=CanCom_FD11RxSignalsSR.COMRX_BMS_HV_High_Temp_Thrsh_BATTERY_HV2_FD11
      data received event DRECOMRX_BMS_HV_Low_Temp_Thrsh_BATTERY_HV2_FD11: start-on-event=COMRX_BMS_HV_Low_Temp_Thrsh_BATTERY_HV2_FD11_Received, data=CanCom_FD11RxSignalsSR.COMRX_BMS_HV_Low_Temp_Thrsh_BATTERY_HV2_FD11
      data receive error event DEECOMRX_BMS_HV_Low_Temp_Thrsh_BATTERY_HV2_FD11: start-on-event=COMRX_BMS_HV_Low_Temp_Thrsh_BATTERY_HV2_FD11_Error, data=CanCom_FD11RxSignalsSR.COMRX_BMS_HV_Low_Temp_Thrsh_BATTERY_HV2_FD11
      data received event DRECOMRX_BMS_HV_SOC_AccuracySts_BATTERY_HV2_FD11: start-on-event=COMRX_BMS_HV_SOC_AccuracySts_BATTERY_HV2_FD11_Received, data=CanCom_FD11RxSignalsSR.COMRX_BMS_HV_SOC_AccuracySts_BATTERY_HV2_FD11
      data receive error event DEECOMRX_BMS_HV_SOC_AccuracySts_BATTERY_HV2_FD11: start-on-event=COMRX_BMS_HV_SOC_AccuracySts_BATTERY_HV2_FD11_Error, data=CanCom_FD11RxSignalsSR.COMRX_BMS_HV_SOC_AccuracySts_BATTERY_HV2_FD11
      data received event DRECOMRX_BMS_HV_SOC_Max_BATTERY_HV2_FD11: start-on-event=COMRX_BMS_HV_SOC_Max_BATTERY_HV2_FD11_Received, data=CanCom_FD11RxSignalsSR.COMRX_BMS_HV_SOC_Max_BATTERY_HV2_FD11
      data receive error event DEECOMRX_BMS_HV_SOC_Max_BATTERY_HV2_FD11: start-on-event=COMRX_BMS_HV_SOC_Max_BATTERY_HV2_FD11_Error, data=CanCom_FD11RxSignalsSR.COMRX_BMS_HV_SOC_Max_BATTERY_HV2_FD11
      data received event DRECOMRX_BMS_HV_SOC_Min_BATTERY_HV2_FD11: start-on-event=COMRX_BMS_HV_SOC_Min_BATTERY_HV2_FD11_Received, data=CanCom_FD11RxSignalsSR.COMRX_BMS_HV_SOC_Min_BATTERY_HV2_FD11
      data receive error event DEECOMRX_BMS_HV_SOC_Min_BATTERY_HV2_FD11: start-on-event=COMRX_BMS_HV_SOC_Min_BATTERY_HV2_FD11_Error, data=CanCom_FD11RxSignalsSR.COMRX_BMS_HV_SOC_Min_BATTERY_HV2_FD11
      data received event DRECOMRX_HEV_OnRq_BPCM_BATTERY_HV2_FD11: start-on-event=COMRX_HEV_OnRq_BPCM_BATTERY_HV2_FD11_Received, data=CanCom_FD11RxSignalsSR.COMRX_HEV_OnRq_BPCM_BATTERY_HV2_FD11
      data receive error event DEECOMRX_HEV_OnRq_BPCM_BATTERY_HV2_FD11: start-on-event=COMRX_HEV_OnRq_BPCM_BATTERY_HV2_FD11_Error, data=CanCom_FD11RxSignalsSR.COMRX_HEV_OnRq_BPCM_BATTERY_HV2_FD11
      data received event DRECOMRX_HVBatCell_Voltage_High_Thrsh_BATTERY_HV2_FD11: start-on-event=COMRX_HVBatCell_Voltage_High_Thrsh_BATTERY_HV2_FD11_Received, data=CanCom_FD11RxSignalsSR.COMRX_HVBatCell_Voltage_High_Thrsh_BATTERY_HV2_FD11
      data receive error event DEECOMRX_HVBatCell_Voltage_High_Thrsh_BATTERY_HV2_FD11: start-on-event=COMRX_HVBatCell_Voltage_High_Thrsh_BATTERY_HV2_FD11_Error, data=CanCom_FD11RxSignalsSR.COMRX_HVBatCell_Voltage_High_Thrsh_BATTERY_HV2_FD11
      data received event DRECOMRX_HVBatCell_Voltage_Low_Thrsh_BATTERY_HV2_FD11: start-on-event=COMRX_HVBatCell_Voltage_Low_Thrsh_BATTERY_HV2_FD11_Received, data=CanCom_FD11RxSignalsSR.COMRX_HVBatCell_Voltage_Low_Thrsh_BATTERY_HV2_FD11
      data receive error event DEECOMRX_HVBatCell_Voltage_Low_Thrsh_BATTERY_HV2_FD11: start-on-event=COMRX_HVBatCell_Voltage_Low_Thrsh_BATTERY_HV2_FD11_Error, data=CanCom_FD11RxSignalsSR.COMRX_HVBatCell_Voltage_Low_Thrsh_BATTERY_HV2_FD11
      data received event DRECOMRX_OBC_Temp1_DUALCHARGER_THERMAL_FD11: start-on-event=COMRX_OBC_Temp1_DUALCHARGER_THERMAL_FD11_Received, data=CanCom_FD11RxSignalsSR.COMRX_OBC_Temp1_DUALCHARGER_THERMAL_FD11
      data receive error event DEECOMRX_OBC_Temp1_DUALCHARGER_THERMAL_FD11: start-on-event=COMRX_OBC_Temp1_DUALCHARGER_THERMAL_FD11_Error, data=CanCom_FD11RxSignalsSR.COMRX_OBC_Temp1_DUALCHARGER_THERMAL_FD11
      data received event DRECOMRX_OBC_Temp2_DUALCHARGER_THERMAL_FD11: start-on-event=COMRX_OBC_Temp2_DUALCHARGER_THERMAL_FD11_Received, data=CanCom_FD11RxSignalsSR.COMRX_OBC_Temp2_DUALCHARGER_THERMAL_FD11
      data receive error event DEECOMRX_OBC_Temp2_DUALCHARGER_THERMAL_FD11: start-on-event=COMRX_OBC_Temp2_DUALCHARGER_THERMAL_FD11_Error, data=CanCom_FD11RxSignalsSR.COMRX_OBC_Temp2_DUALCHARGER_THERMAL_FD11
      data received event DRECOMRX_OBC_Temp3_DUALCHARGER_THERMAL_FD11: start-on-event=COMRX_OBC_Temp3_DUALCHARGER_THERMAL_FD11_Received, data=CanCom_FD11RxSignalsSR.COMRX_OBC_Temp3_DUALCHARGER_THERMAL_FD11
      data receive error event DEECOMRX_OBC_Temp3_DUALCHARGER_THERMAL_FD11: start-on-event=COMRX_OBC_Temp3_DUALCHARGER_THERMAL_FD11_Error, data=CanCom_FD11RxSignalsSR.COMRX_OBC_Temp3_DUALCHARGER_THERMAL_FD11
      data received event DRECOMRX_OBC_Temp4_DUALCHARGER_THERMAL_FD11: start-on-event=COMRX_OBC_Temp4_DUALCHARGER_THERMAL_FD11_Received, data=CanCom_FD11RxSignalsSR.COMRX_OBC_Temp4_DUALCHARGER_THERMAL_FD11
      data receive error event DEECOMRX_OBC_Temp4_DUALCHARGER_THERMAL_FD11: start-on-event=COMRX_OBC_Temp4_DUALCHARGER_THERMAL_FD11_Error, data=CanCom_FD11RxSignalsSR.COMRX_OBC_Temp4_DUALCHARGER_THERMAL_FD11
      data received event DRECOMRX_CRC_FOTA_MASTER_FOTA_MASTER_FD11: start-on-event=COMRX_CRC_FOTA_MASTER_FOTA_MASTER_FD11_Received, data=CanCom_FD11RxSignalsSR.COMRX_CRC_FOTA_MASTER_FOTA_MASTER_FD11
      data receive error event DEECOMRX_CRC_FOTA_MASTER_FOTA_MASTER_FD11: start-on-event=COMRX_CRC_FOTA_MASTER_FOTA_MASTER_FD11_Error, data=CanCom_FD11RxSignalsSR.COMRX_CRC_FOTA_MASTER_FOTA_MASTER_FD11
      data received event DRECOMRX_FOTA_Status_FOTA_MASTER_FD11: start-on-event=COMRX_FOTA_Status_FOTA_MASTER_FD11_Received, data=CanCom_FD11RxSignalsSR.COMRX_FOTA_Status_FOTA_MASTER_FD11
      data receive error event DEECOMRX_FOTA_Status_FOTA_MASTER_FD11: start-on-event=COMRX_FOTA_Status_FOTA_MASTER_FD11_Error, data=CanCom_FD11RxSignalsSR.COMRX_FOTA_Status_FOTA_MASTER_FD11
      data received event DRECOMRX_MessageCounter_FOTA_MASTER_FOTA_MASTER_FD11: start-on-event=COMRX_MessageCounter_FOTA_MASTER_FOTA_MASTER_FD11_Received, data=CanCom_FD11RxSignalsSR.COMRX_MessageCounter_FOTA_MASTER_FOTA_MASTER_FD11
      data receive error event DEECOMRX_MessageCounter_FOTA_MASTER_FOTA_MASTER_FD11: start-on-event=COMRX_MessageCounter_FOTA_MASTER_FOTA_MASTER_FD11_Error, data=CanCom_FD11RxSignalsSR.COMRX_MessageCounter_FOTA_MASTER_FOTA_MASTER_FD11
      data received event DRECOMRX_N_PDU_7E_GLIWA_MCPA_RX_FD11: start-on-event=COMRX_N_PDU_7E_GLIWA_MCPA_RX_FD11_Received, data=CanCom_FD11RxSignalsSR.COMRX_N_PDU_7E_GLIWA_MCPA_RX_FD11
      data receive error event DEECOMRX_N_PDU_7E_GLIWA_MCPA_RX_FD11: start-on-event=COMRX_N_PDU_7E_GLIWA_MCPA_RX_FD11_Error, data=CanCom_FD11RxSignalsSR.COMRX_N_PDU_7E_GLIWA_MCPA_RX_FD11
      data received event DRECOMRX_N_PDU_7F_GLIWA_MCPB_RX_FD11: start-on-event=COMRX_N_PDU_7F_GLIWA_MCPB_RX_FD11_Received, data=CanCom_FD11RxSignalsSR.COMRX_N_PDU_7F_GLIWA_MCPB_RX_FD11
      data receive error event DEECOMRX_N_PDU_7F_GLIWA_MCPB_RX_FD11: start-on-event=COMRX_N_PDU_7F_GLIWA_MCPB_RX_FD11_Error, data=CanCom_FD11RxSignalsSR.COMRX_N_PDU_7F_GLIWA_MCPB_RX_FD11
      data received event DRECOMRX_N_PDU_81_GLIWA_SGCP_RX_FD11: start-on-event=COMRX_N_PDU_81_GLIWA_SGCP_RX_FD11_Received, data=CanCom_FD11RxSignalsSR.COMRX_N_PDU_81_GLIWA_SGCP_RX_FD11
      data receive error event DEECOMRX_N_PDU_81_GLIWA_SGCP_RX_FD11: start-on-event=COMRX_N_PDU_81_GLIWA_SGCP_RX_FD11_Error, data=CanCom_FD11RxSignalsSR.COMRX_N_PDU_81_GLIWA_SGCP_RX_FD11
      data received event DRECOMRX_N_PDU_343_GLIWA_T1_RX_FD11: start-on-event=COMRX_N_PDU_343_GLIWA_T1_RX_FD11_Received, data=CanCom_FD11RxSignalsSR.COMRX_N_PDU_343_GLIWA_T1_RX_FD11
      data receive error event DEECOMRX_N_PDU_343_GLIWA_T1_RX_FD11: start-on-event=COMRX_N_PDU_343_GLIWA_T1_RX_FD11_Error, data=CanCom_FD11RxSignalsSR.COMRX_N_PDU_343_GLIWA_T1_RX_FD11
      data received event DRECOMRX_HVBatteryMILRequest_HVBATTERY2_FD11: start-on-event=COMRX_HVBatteryMILRequest_HVBATTERY2_FD11_Received, data=CanCom_FD11RxSignalsSR.COMRX_HVBatteryMILRequest_HVBATTERY2_FD11
      data receive error event DEECOMRX_HVBatteryMILRequest_HVBATTERY2_FD11: start-on-event=COMRX_HVBatteryMILRequest_HVBATTERY2_FD11_Error, data=CanCom_FD11RxSignalsSR.COMRX_HVBatteryMILRequest_HVBATTERY2_FD11
      data received event DRECOMRX_HVBattery_RealTimeClock_HVBATTERY5_FD11: start-on-event=COMRX_HVBattery_RealTimeClock_HVBATTERY5_FD11_Received, data=CanCom_FD11RxSignalsSR.COMRX_HVBattery_RealTimeClock_HVBATTERY5_FD11
      data receive error event DEECOMRX_HVBattery_RealTimeClock_HVBATTERY5_FD11: start-on-event=COMRX_HVBattery_RealTimeClock_HVBATTERY5_FD11_Error, data=CanCom_FD11RxSignalsSR.COMRX_HVBattery_RealTimeClock_HVBATTERY5_FD11
      data received event DRECOMRX_HVBattery_RealTimeClockV_HVBATTERY5_FD11: start-on-event=COMRX_HVBattery_RealTimeClockV_HVBATTERY5_FD11_Received, data=CanCom_FD11RxSignalsSR.COMRX_HVBattery_RealTimeClockV_HVBATTERY5_FD11
      data receive error event DEECOMRX_HVBattery_RealTimeClockV_HVBATTERY5_FD11: start-on-event=COMRX_HVBattery_RealTimeClockV_HVBATTERY5_FD11_Error, data=CanCom_FD11RxSignalsSR.COMRX_HVBattery_RealTimeClockV_HVBATTERY5_FD11
      data received event DRECOMRX_Warning_PackTempHigh_HVBATTERY_RM_CHARGING1_FD11: start-on-event=COMRX_Warning_PackTempHigh_HVBATTERY_RM_CHARGING1_FD11_Received, data=CanCom_FD11RxSignalsSR.COMRX_Warning_PackTempHigh_HVBATTERY_RM_CHARGING1_FD11
      data receive error event DEECOMRX_Warning_PackTempHigh_HVBATTERY_RM_CHARGING1_FD11: start-on-event=COMRX_Warning_PackTempHigh_HVBATTERY_RM_CHARGING1_FD11_Error, data=CanCom_FD11RxSignalsSR.COMRX_Warning_PackTempHigh_HVBATTERY_RM_CHARGING1_FD11
      data received event DRECOMRX_HVBatSleepTime_HVBATTERY_THERMAL_FD11: start-on-event=COMRX_HVBatSleepTime_HVBATTERY_THERMAL_FD11_Received, data=CanCom_FD11RxSignalsSR.COMRX_HVBatSleepTime_HVBATTERY_THERMAL_FD11
      data receive error event DEECOMRX_HVBatSleepTime_HVBATTERY_THERMAL_FD11: start-on-event=COMRX_HVBatSleepTime_HVBATTERY_THERMAL_FD11_Error, data=CanCom_FD11RxSignalsSR.COMRX_HVBatSleepTime_HVBATTERY_THERMAL_FD11
      data received event DRECOMRX_CdM_Avail_output_current_EXT_IDCM_CHADEMO_STATUS1_FD11: start-on-event=COMRX_CdM_Avail_output_current_EXT_IDCM_CHADEMO_STATUS1_FD11_Received, data=CanCom_FD11RxSignalsSR.COMRX_CdM_Avail_output_current_EXT_IDCM_CHADEMO_STATUS1_FD11
      data receive error event DEECOMRX_CdM_Avail_output_current_EXT_IDCM_CHADEMO_STATUS1_FD11: start-on-event=COMRX_CdM_Avail_output_current_EXT_IDCM_CHADEMO_STATUS1_FD11_Error, data=CanCom_FD11RxSignalsSR.COMRX_CdM_Avail_output_current_EXT_IDCM_CHADEMO_STATUS1_FD11
      data received event DRECOMRX_CdM_Charger_connector_lock_IDCM_CHADEMO_STATUS1_FD11: start-on-event=COMRX_CdM_Charger_connector_lock_IDCM_CHADEMO_STATUS1_FD11_Received, data=CanCom_FD11RxSignalsSR.COMRX_CdM_Charger_connector_lock_IDCM_CHADEMO_STATUS1_FD11
      data receive error event DEECOMRX_CdM_Charger_connector_lock_IDCM_CHADEMO_STATUS1_FD11: start-on-event=COMRX_CdM_Charger_connector_lock_IDCM_CHADEMO_STATUS1_FD11_Error, data=CanCom_FD11RxSignalsSR.COMRX_CdM_Charger_connector_lock_IDCM_CHADEMO_STATUS1_FD11
      data received event DRECOMRX_CdM_ExtFun_Thres_Volt_IDCM_CHADEMO_STATUS1_FD11: start-on-event=COMRX_CdM_ExtFun_Thres_Volt_IDCM_CHADEMO_STATUS1_FD11_Received, data=CanCom_FD11RxSignalsSR.COMRX_CdM_ExtFun_Thres_Volt_IDCM_CHADEMO_STATUS1_FD11
      data receive error event DEECOMRX_CdM_ExtFun_Thres_Volt_IDCM_CHADEMO_STATUS1_FD11: start-on-event=COMRX_CdM_ExtFun_Thres_Volt_IDCM_CHADEMO_STATUS1_FD11_Error, data=CanCom_FD11RxSignalsSR.COMRX_CdM_ExtFun_Thres_Volt_IDCM_CHADEMO_STATUS1_FD11
      data received event DRECOMRX_EVSE_BatteryCompatibilty_IDCM_CHADEMO_STATUS1_FD11: start-on-event=COMRX_EVSE_BatteryCompatibilty_IDCM_CHADEMO_STATUS1_FD11_Received, data=CanCom_FD11RxSignalsSR.COMRX_EVSE_BatteryCompatibilty_IDCM_CHADEMO_STATUS1_FD11
      data receive error event DEECOMRX_EVSE_BatteryCompatibilty_IDCM_CHADEMO_STATUS1_FD11: start-on-event=COMRX_EVSE_BatteryCompatibilty_IDCM_CHADEMO_STATUS1_FD11_Error, data=CanCom_FD11RxSignalsSR.COMRX_EVSE_BatteryCompatibilty_IDCM_CHADEMO_STATUS1_FD11
      data received event DRECOMRX_EVSE_CHAdeMOProtocol_IDCM_CHADEMO_STATUS1_FD11: start-on-event=COMRX_EVSE_CHAdeMOProtocol_IDCM_CHADEMO_STATUS1_FD11_Received, data=CanCom_FD11RxSignalsSR.COMRX_EVSE_CHAdeMOProtocol_IDCM_CHADEMO_STATUS1_FD11
      data receive error event DEECOMRX_EVSE_CHAdeMOProtocol_IDCM_CHADEMO_STATUS1_FD11: start-on-event=COMRX_EVSE_CHAdeMOProtocol_IDCM_CHADEMO_STATUS1_FD11_Error, data=CanCom_FD11RxSignalsSR.COMRX_EVSE_CHAdeMOProtocol_IDCM_CHADEMO_STATUS1_FD11
      data received event DRECOMRX_EVSE_ChargingSystemError_IDCM_CHADEMO_STATUS1_FD11: start-on-event=COMRX_EVSE_ChargingSystemError_IDCM_CHADEMO_STATUS1_FD11_Received, data=CanCom_FD11RxSignalsSR.COMRX_EVSE_ChargingSystemError_IDCM_CHADEMO_STATUS1_FD11
      data receive error event DEECOMRX_EVSE_ChargingSystemError_IDCM_CHADEMO_STATUS1_FD11: start-on-event=COMRX_EVSE_ChargingSystemError_IDCM_CHADEMO_STATUS1_FD11_Error, data=CanCom_FD11RxSignalsSR.COMRX_EVSE_ChargingSystemError_IDCM_CHADEMO_STATUS1_FD11
      data received event DRECOMRX_EVSE_EnergizingState_IDCM_CHADEMO_STATUS1_FD11: start-on-event=COMRX_EVSE_EnergizingState_IDCM_CHADEMO_STATUS1_FD11_Received, data=CanCom_FD11RxSignalsSR.COMRX_EVSE_EnergizingState_IDCM_CHADEMO_STATUS1_FD11
      data receive error event DEECOMRX_EVSE_EnergizingState_IDCM_CHADEMO_STATUS1_FD11: start-on-event=COMRX_EVSE_EnergizingState_IDCM_CHADEMO_STATUS1_FD11_Error, data=CanCom_FD11RxSignalsSR.COMRX_EVSE_EnergizingState_IDCM_CHADEMO_STATUS1_FD11
      data received event DRECOMRX_EVSE_RemainingMin_IDCM_CHADEMO_STATUS1_FD11: start-on-event=COMRX_EVSE_RemainingMin_IDCM_CHADEMO_STATUS1_FD11_Received, data=CanCom_FD11RxSignalsSR.COMRX_EVSE_RemainingMin_IDCM_CHADEMO_STATUS1_FD11
      data receive error event DEECOMRX_EVSE_RemainingMin_IDCM_CHADEMO_STATUS1_FD11: start-on-event=COMRX_EVSE_RemainingMin_IDCM_CHADEMO_STATUS1_FD11_Error, data=CanCom_FD11RxSignalsSR.COMRX_EVSE_RemainingMin_IDCM_CHADEMO_STATUS1_FD11
      data received event DRECOMRX_EVSE_RemainingSec_IDCM_CHADEMO_STATUS1_FD11: start-on-event=COMRX_EVSE_RemainingSec_IDCM_CHADEMO_STATUS1_FD11_Received, data=CanCom_FD11RxSignalsSR.COMRX_EVSE_RemainingSec_IDCM_CHADEMO_STATUS1_FD11
      data receive error event DEECOMRX_EVSE_RemainingSec_IDCM_CHADEMO_STATUS1_FD11: start-on-event=COMRX_EVSE_RemainingSec_IDCM_CHADEMO_STATUS1_FD11_Error, data=CanCom_FD11RxSignalsSR.COMRX_EVSE_RemainingSec_IDCM_CHADEMO_STATUS1_FD11
      data received event DRECOMRX_EVSE_ThrshldVoltage_IDCM_CHADEMO_STATUS1_FD11: start-on-event=COMRX_EVSE_ThrshldVoltage_IDCM_CHADEMO_STATUS1_FD11_Received, data=CanCom_FD11RxSignalsSR.COMRX_EVSE_ThrshldVoltage_IDCM_CHADEMO_STATUS1_FD11
      data receive error event DEECOMRX_EVSE_ThrshldVoltage_IDCM_CHADEMO_STATUS1_FD11: start-on-event=COMRX_EVSE_ThrshldVoltage_IDCM_CHADEMO_STATUS1_FD11_Error, data=CanCom_FD11RxSignalsSR.COMRX_EVSE_ThrshldVoltage_IDCM_CHADEMO_STATUS1_FD11
      data received event DRECOMRX_CRC_IDCM_OBD_DTC_IDCM_OBD_DTC_FD11: start-on-event=COMRX_CRC_IDCM_OBD_DTC_IDCM_OBD_DTC_FD11_Received, data=CanCom_FD11RxSignalsSR.COMRX_CRC_IDCM_OBD_DTC_IDCM_OBD_DTC_FD11
      data receive error event DEECOMRX_CRC_IDCM_OBD_DTC_IDCM_OBD_DTC_FD11: start-on-event=COMRX_CRC_IDCM_OBD_DTC_IDCM_OBD_DTC_FD11_Error, data=CanCom_FD11RxSignalsSR.COMRX_CRC_IDCM_OBD_DTC_IDCM_OBD_DTC_FD11
      data received event DRECOMRX_IDCM_CAL_ID_IDCM_OBD_DTC_FD11: start-on-event=COMRX_IDCM_CAL_ID_IDCM_OBD_DTC_FD11_Received, data=CanCom_FD11RxSignalsSR.COMRX_IDCM_CAL_ID_IDCM_OBD_DTC_FD11
      data receive error event DEECOMRX_IDCM_CAL_ID_IDCM_OBD_DTC_FD11: start-on-event=COMRX_IDCM_CAL_ID_IDCM_OBD_DTC_FD11_Error, data=CanCom_FD11RxSignalsSR.COMRX_IDCM_CAL_ID_IDCM_OBD_DTC_FD11
      data received event DRECOMRX_IDCM_CAL_VN_IDCM_OBD_DTC_FD11: start-on-event=COMRX_IDCM_CAL_VN_IDCM_OBD_DTC_FD11_Received, data=CanCom_FD11RxSignalsSR.COMRX_IDCM_CAL_VN_IDCM_OBD_DTC_FD11
      data receive error event DEECOMRX_IDCM_CAL_VN_IDCM_OBD_DTC_FD11: start-on-event=COMRX_IDCM_CAL_VN_IDCM_OBD_DTC_FD11_Error, data=CanCom_FD11RxSignalsSR.COMRX_IDCM_CAL_VN_IDCM_OBD_DTC_FD11
      data received event DRECOMRX_IDCM_DTC_Idx1_IDCM_OBD_DTC_FD11: start-on-event=COMRX_IDCM_DTC_Idx1_IDCM_OBD_DTC_FD11_Received, data=CanCom_FD11RxSignalsSR.COMRX_IDCM_DTC_Idx1_IDCM_OBD_DTC_FD11
      data receive error event DEECOMRX_IDCM_DTC_Idx1_IDCM_OBD_DTC_FD11: start-on-event=COMRX_IDCM_DTC_Idx1_IDCM_OBD_DTC_FD11_Error, data=CanCom_FD11RxSignalsSR.COMRX_IDCM_DTC_Idx1_IDCM_OBD_DTC_FD11
      data received event DRECOMRX_IDCM_DTC_Idx2_IDCM_OBD_DTC_FD11: start-on-event=COMRX_IDCM_DTC_Idx2_IDCM_OBD_DTC_FD11_Received, data=CanCom_FD11RxSignalsSR.COMRX_IDCM_DTC_Idx2_IDCM_OBD_DTC_FD11
      data receive error event DEECOMRX_IDCM_DTC_Idx2_IDCM_OBD_DTC_FD11: start-on-event=COMRX_IDCM_DTC_Idx2_IDCM_OBD_DTC_FD11_Error, data=CanCom_FD11RxSignalsSR.COMRX_IDCM_DTC_Idx2_IDCM_OBD_DTC_FD11
      data received event DRECOMRX_IDCM_DTC_Idx3_IDCM_OBD_DTC_FD11: start-on-event=COMRX_IDCM_DTC_Idx3_IDCM_OBD_DTC_FD11_Received, data=CanCom_FD11RxSignalsSR.COMRX_IDCM_DTC_Idx3_IDCM_OBD_DTC_FD11
      data receive error event DEECOMRX_IDCM_DTC_Idx3_IDCM_OBD_DTC_FD11: start-on-event=COMRX_IDCM_DTC_Idx3_IDCM_OBD_DTC_FD11_Error, data=CanCom_FD11RxSignalsSR.COMRX_IDCM_DTC_Idx3_IDCM_OBD_DTC_FD11
      data received event DRECOMRX_IDCM_DTC_Idx4_IDCM_OBD_DTC_FD11: start-on-event=COMRX_IDCM_DTC_Idx4_IDCM_OBD_DTC_FD11_Received, data=CanCom_FD11RxSignalsSR.COMRX_IDCM_DTC_Idx4_IDCM_OBD_DTC_FD11
      data receive error event DEECOMRX_IDCM_DTC_Idx4_IDCM_OBD_DTC_FD11: start-on-event=COMRX_IDCM_DTC_Idx4_IDCM_OBD_DTC_FD11_Error, data=CanCom_FD11RxSignalsSR.COMRX_IDCM_DTC_Idx4_IDCM_OBD_DTC_FD11
      data received event DRECOMRX_IDCM_DTC_Idx5_IDCM_OBD_DTC_FD11: start-on-event=COMRX_IDCM_DTC_Idx5_IDCM_OBD_DTC_FD11_Received, data=CanCom_FD11RxSignalsSR.COMRX_IDCM_DTC_Idx5_IDCM_OBD_DTC_FD11
      data receive error event DEECOMRX_IDCM_DTC_Idx5_IDCM_OBD_DTC_FD11: start-on-event=COMRX_IDCM_DTC_Idx5_IDCM_OBD_DTC_FD11_Error, data=CanCom_FD11RxSignalsSR.COMRX_IDCM_DTC_Idx5_IDCM_OBD_DTC_FD11
      data received event DRECOMRX_IDCM_DTC_Idx6_IDCM_OBD_DTC_FD11: start-on-event=COMRX_IDCM_DTC_Idx6_IDCM_OBD_DTC_FD11_Received, data=CanCom_FD11RxSignalsSR.COMRX_IDCM_DTC_Idx6_IDCM_OBD_DTC_FD11
      data receive error event DEECOMRX_IDCM_DTC_Idx6_IDCM_OBD_DTC_FD11: start-on-event=COMRX_IDCM_DTC_Idx6_IDCM_OBD_DTC_FD11_Error, data=CanCom_FD11RxSignalsSR.COMRX_IDCM_DTC_Idx6_IDCM_OBD_DTC_FD11
      data received event DRECOMRX_IDCM_DTC_Idx7_IDCM_OBD_DTC_FD11: start-on-event=COMRX_IDCM_DTC_Idx7_IDCM_OBD_DTC_FD11_Received, data=CanCom_FD11RxSignalsSR.COMRX_IDCM_DTC_Idx7_IDCM_OBD_DTC_FD11
      data receive error event DEECOMRX_IDCM_DTC_Idx7_IDCM_OBD_DTC_FD11: start-on-event=COMRX_IDCM_DTC_Idx7_IDCM_OBD_DTC_FD11_Error, data=CanCom_FD11RxSignalsSR.COMRX_IDCM_DTC_Idx7_IDCM_OBD_DTC_FD11
      data received event DRECOMRX_IDCM_DTC_Idx8_IDCM_OBD_DTC_FD11: start-on-event=COMRX_IDCM_DTC_Idx8_IDCM_OBD_DTC_FD11_Received, data=CanCom_FD11RxSignalsSR.COMRX_IDCM_DTC_Idx8_IDCM_OBD_DTC_FD11
      data receive error event DEECOMRX_IDCM_DTC_Idx8_IDCM_OBD_DTC_FD11: start-on-event=COMRX_IDCM_DTC_Idx8_IDCM_OBD_DTC_FD11_Error, data=CanCom_FD11RxSignalsSR.COMRX_IDCM_DTC_Idx8_IDCM_OBD_DTC_FD11
      data received event DRECOMRX_IDCM_DTC_Stat1_IDCM_OBD_DTC_FD11: start-on-event=COMRX_IDCM_DTC_Stat1_IDCM_OBD_DTC_FD11_Received, data=CanCom_FD11RxSignalsSR.COMRX_IDCM_DTC_Stat1_IDCM_OBD_DTC_FD11
      data receive error event DEECOMRX_IDCM_DTC_Stat1_IDCM_OBD_DTC_FD11: start-on-event=COMRX_IDCM_DTC_Stat1_IDCM_OBD_DTC_FD11_Error, data=CanCom_FD11RxSignalsSR.COMRX_IDCM_DTC_Stat1_IDCM_OBD_DTC_FD11
      data received event DRECOMRX_IDCM_DTC_Stat2_IDCM_OBD_DTC_FD11: start-on-event=COMRX_IDCM_DTC_Stat2_IDCM_OBD_DTC_FD11_Received, data=CanCom_FD11RxSignalsSR.COMRX_IDCM_DTC_Stat2_IDCM_OBD_DTC_FD11
      data receive error event DEECOMRX_IDCM_DTC_Stat2_IDCM_OBD_DTC_FD11: start-on-event=COMRX_IDCM_DTC_Stat2_IDCM_OBD_DTC_FD11_Error, data=CanCom_FD11RxSignalsSR.COMRX_IDCM_DTC_Stat2_IDCM_OBD_DTC_FD11
      data received event DRECOMRX_IDCM_DTC_Stat3_IDCM_OBD_DTC_FD11: start-on-event=COMRX_IDCM_DTC_Stat3_IDCM_OBD_DTC_FD11_Received, data=CanCom_FD11RxSignalsSR.COMRX_IDCM_DTC_Stat3_IDCM_OBD_DTC_FD11
      data receive error event DEECOMRX_IDCM_DTC_Stat3_IDCM_OBD_DTC_FD11: start-on-event=COMRX_IDCM_DTC_Stat3_IDCM_OBD_DTC_FD11_Error, data=CanCom_FD11RxSignalsSR.COMRX_IDCM_DTC_Stat3_IDCM_OBD_DTC_FD11
      data received event DRECOMRX_IDCM_DTC_Stat4_IDCM_OBD_DTC_FD11: start-on-event=COMRX_IDCM_DTC_Stat4_IDCM_OBD_DTC_FD11_Received, data=CanCom_FD11RxSignalsSR.COMRX_IDCM_DTC_Stat4_IDCM_OBD_DTC_FD11
      data receive error event DEECOMRX_IDCM_DTC_Stat4_IDCM_OBD_DTC_FD11: start-on-event=COMRX_IDCM_DTC_Stat4_IDCM_OBD_DTC_FD11_Error, data=CanCom_FD11RxSignalsSR.COMRX_IDCM_DTC_Stat4_IDCM_OBD_DTC_FD11
      data received event DRECOMRX_IDCM_DTC_Stat5_IDCM_OBD_DTC_FD11: start-on-event=COMRX_IDCM_DTC_Stat5_IDCM_OBD_DTC_FD11_Received, data=CanCom_FD11RxSignalsSR.COMRX_IDCM_DTC_Stat5_IDCM_OBD_DTC_FD11
      data receive error event DEECOMRX_IDCM_DTC_Stat5_IDCM_OBD_DTC_FD11: start-on-event=COMRX_IDCM_DTC_Stat5_IDCM_OBD_DTC_FD11_Error, data=CanCom_FD11RxSignalsSR.COMRX_IDCM_DTC_Stat5_IDCM_OBD_DTC_FD11
      data received event DRECOMRX_IDCM_DTC_Stat6_IDCM_OBD_DTC_FD11: start-on-event=COMRX_IDCM_DTC_Stat6_IDCM_OBD_DTC_FD11_Received, data=CanCom_FD11RxSignalsSR.COMRX_IDCM_DTC_Stat6_IDCM_OBD_DTC_FD11
      data receive error event DEECOMRX_IDCM_DTC_Stat6_IDCM_OBD_DTC_FD11: start-on-event=COMRX_IDCM_DTC_Stat6_IDCM_OBD_DTC_FD11_Error, data=CanCom_FD11RxSignalsSR.COMRX_IDCM_DTC_Stat6_IDCM_OBD_DTC_FD11
      data received event DRECOMRX_IDCM_DTC_Stat7_IDCM_OBD_DTC_FD11: start-on-event=COMRX_IDCM_DTC_Stat7_IDCM_OBD_DTC_FD11_Received, data=CanCom_FD11RxSignalsSR.COMRX_IDCM_DTC_Stat7_IDCM_OBD_DTC_FD11
      data receive error event DEECOMRX_IDCM_DTC_Stat7_IDCM_OBD_DTC_FD11: start-on-event=COMRX_IDCM_DTC_Stat7_IDCM_OBD_DTC_FD11_Error, data=CanCom_FD11RxSignalsSR.COMRX_IDCM_DTC_Stat7_IDCM_OBD_DTC_FD11
      data received event DRECOMRX_IDCM_DTC_Stat8_IDCM_OBD_DTC_FD11: start-on-event=COMRX_IDCM_DTC_Stat8_IDCM_OBD_DTC_FD11_Received, data=CanCom_FD11RxSignalsSR.COMRX_IDCM_DTC_Stat8_IDCM_OBD_DTC_FD11
      data receive error event DEECOMRX_IDCM_DTC_Stat8_IDCM_OBD_DTC_FD11: start-on-event=COMRX_IDCM_DTC_Stat8_IDCM_OBD_DTC_FD11_Error, data=CanCom_FD11RxSignalsSR.COMRX_IDCM_DTC_Stat8_IDCM_OBD_DTC_FD11
      data received event DRECOMRX_IDCM_RBM_Idx_IDCM_OBD_DTC_FD11: start-on-event=COMRX_IDCM_RBM_Idx_IDCM_OBD_DTC_FD11_Received, data=CanCom_FD11RxSignalsSR.COMRX_IDCM_RBM_Idx_IDCM_OBD_DTC_FD11
      data receive error event DEECOMRX_IDCM_RBM_Idx_IDCM_OBD_DTC_FD11: start-on-event=COMRX_IDCM_RBM_Idx_IDCM_OBD_DTC_FD11_Error, data=CanCom_FD11RxSignalsSR.COMRX_IDCM_RBM_Idx_IDCM_OBD_DTC_FD11
      data received event DRECOMRX_IDCM_RBM_Stat_IDCM_OBD_DTC_FD11: start-on-event=COMRX_IDCM_RBM_Stat_IDCM_OBD_DTC_FD11_Received, data=CanCom_FD11RxSignalsSR.COMRX_IDCM_RBM_Stat_IDCM_OBD_DTC_FD11
      data receive error event DEECOMRX_IDCM_RBM_Stat_IDCM_OBD_DTC_FD11: start-on-event=COMRX_IDCM_RBM_Stat_IDCM_OBD_DTC_FD11_Error, data=CanCom_FD11RxSignalsSR.COMRX_IDCM_RBM_Stat_IDCM_OBD_DTC_FD11
      data received event DRECOMRX_MessageCounter_IDCM_OBD_DTC_IDCM_OBD_DTC_FD11: start-on-event=COMRX_MessageCounter_IDCM_OBD_DTC_IDCM_OBD_DTC_FD11_Received, data=CanCom_FD11RxSignalsSR.COMRX_MessageCounter_IDCM_OBD_DTC_IDCM_OBD_DTC_FD11
      data receive error event DEECOMRX_MessageCounter_IDCM_OBD_DTC_IDCM_OBD_DTC_FD11: start-on-event=COMRX_MessageCounter_IDCM_OBD_DTC_IDCM_OBD_DTC_FD11_Error, data=CanCom_FD11RxSignalsSR.COMRX_MessageCounter_IDCM_OBD_DTC_IDCM_OBD_DTC_FD11
      data received event DRECOMRX_IDCM_Wakeup_HCP_LV_CHARGER1_FD11: start-on-event=COMRX_IDCM_Wakeup_HCP_LV_CHARGER1_FD11_Received, data=CanCom_FD11RxSignalsSR.COMRX_IDCM_Wakeup_HCP_LV_CHARGER1_FD11
      data receive error event DEECOMRX_IDCM_Wakeup_HCP_LV_CHARGER1_FD11: start-on-event=COMRX_IDCM_Wakeup_HCP_LV_CHARGER1_FD11_Error, data=CanCom_FD11RxSignalsSR.COMRX_IDCM_Wakeup_HCP_LV_CHARGER1_FD11
